VERSION ""

NS_ :

BS_:

BU_: AHLM ASBS CADM CBC DIAGNOST DPDM DTCM ECM EHPS ESC ESL ESM ETM EVCU2 GPF IC IRCM LTM OCM ORC PTS RF_HUB SCCM SGW TBM TCM

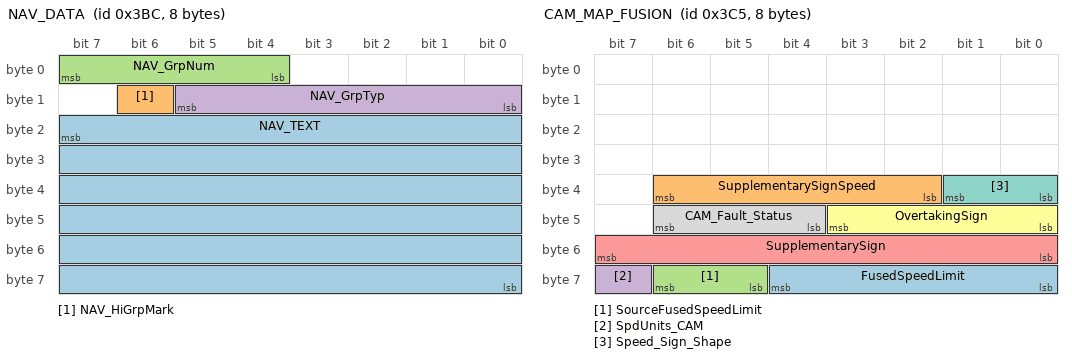
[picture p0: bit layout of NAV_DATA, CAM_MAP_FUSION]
BO_ 956 NAV_DATA: 8 CBC
 SG_ NAV_TEXT : 23|48@0+ (1,0) [0|0] ""  IC,SGW
 SG_ NAV_HiGrpMark : 14|1@1+ (1,0) [0|0] ""  IC,SGW
 SG_ NAV_GrpNum : 4|4@1+ (1,1) [1|16] "Group"  IC,SGW
 SG_ NAV_GrpTyp : 8|6@1+ (1,0) [1|40] "Text"  IC,SGW

BO_ 958 IC_TripData_7: 8 IC
 SG_ Electric_Dist_Miles : 1|10@0+ (1,0) [0|999] "Mile"  CBC,ETM,SGW,TBM
 SG_ Hybrid_Dist_Miles : 17|10@0+ (1,0) [0|999] "Mile"  CBC,ETM,SGW,TBM

BO_ 959 IC_TripData_8: 8 IC
 SG_ Electric_Dist_Kilometers : 1|10@0+ (1,0) [0|999] "km"  CBC,ETM,SGW,TBM
 SG_ Hybrid_Dist_Kilometers : 17|10@0+ (1,0) [0|999] "km"  CBC,ETM,SGW,TBM

BO_ 962 VehCfgCSM3: 8 CBC
 SG_ VC_LIFT_GATE_RELEASE_CSO : 37|1@1+ (1,0) [0|0] ""  RF_HUB,SGW
 SG_ VC_VISM_KEEP_AWAKE_CSO : 38|1@1+ (1,0) [0|0] ""  RF_HUB,SGW
 SG_ VC_FOA_Presence : 39|1@1+ (1,0) [0|0] ""  IC,RF_HUB,SGW,TBM
 SG_ VC_FOA_Type : 12|2@1+ (1,0) [0|0] ""  IC,RF_HUB,SGW,TBM
 SG_ VC_CHMSL_DYN_CNTR_CSO : 7|1@1+ (1,0) [0|0] ""  RF_HUB,SGW
 SG_ VC_VehCfgCSO3_Stat : 0|2@1+ (1,0) [0|0] ""  EVCU2,IC,RF_HUB,SGW
 SG_ VC_FFC_GRIDLINES_CSO : 48|1@1+ (1,0) [0|0] ""  RF_HUB,SGW
 SG_ VC_RVC_CVPM_DGRID_CSO : 49|1@1+ (1,0) [0|0] ""  RF_HUB,SGW
 SG_ VC_RVC_CVPM_SGRID_CSO : 50|1@1+ (1,0) [0|0] ""  RF_HUB,SGW
 SG_ VC_PEB_CSO : 51|1@1+ (1,0) [0|0] ""  RF_HUB,SGW
 SG_ VC_FT_PK_LOOSE_SHIP_CSO : 8|1@1+ (1,0) [0|0] ""  RF_HUB,SGW
 SG_ VC_RR_PK_LOOSE_SHIP_CSO : 9|1@1+ (1,0) [0|0] ""  RF_HUB,SGW
 SG_ VC_ESAVE_CSO : 10|1@1+ (1,0) [0|0] ""  RF_HUB,SGW
 SG_ VC_ESAVE_BATT_LVL_CSO : 11|1@1+ (1,0) [0|0] ""  RF_HUB,SGW
 SG_ VC_AL_OR_PLUS_CSO : 41|1@1+ (1,0) [0|0] ""  RF_HUB,SGW
 SG_ VC_TSR_WARNING_MODE_CSO : 42|1@1+ (1,0) [0|0] ""  RF_HUB,SGW
 SG_ VC_TSR_WARNING_MODE_OFFSET_CSO : 43|1@1+ (1,0) [0|0] ""  RF_HUB,SGW
 SG_ VC_3RD_ROW_LOCK_CSO : 45|1@1+ (1,0) [0|0] ""  RF_HUB,SGW
 SG_ VC_CHARGE_LOW_POPUP_CSO : 46|1@1+ (1,0) [0|0] ""  RF_HUB,SGW
 SG_ VC_FOBIK_SAFE_CSO : 32|1@1+ (1,0) [0|0] ""  RF_HUB,SGW
 SG_ VC_FOB_LEFT_VEHICLE_CHIME_CSO : 33|1@1+ (1,0) [0|0] ""  RF_HUB,SGW
 SG_ VC_THEFT_ALARM_CSO : 34|1@1+ (1,0) [0|0] ""  RF_HUB,SGW
 SG_ VC_PANIC_ALARM_CSO : 35|1@1+ (1,0) [0|0] ""  RF_HUB,SGW
 SG_ VC_SECURE_PARK_CSO : 36|1@1+ (1,0) [0|0] ""  RF_HUB,SGW

BO_ 963 VehCfgCSM3_BU: 8 RF_HUB
 SG_ VC_BU_TSR_WARNING_MODE_CSO : 42|1@1+ (1,0) [0|0] ""  CBC,SGW
 SG_ VC_BU_TSR_WARNING_MODE_OFFSET_CS : 43|1@1+ (1,0) [0|0] ""  CBC,SGW
 SG_ VC_BU_3RD_ROW_LOCK_CSO : 45|1@1+ (1,0) [0|0] ""  CBC,SGW
 SG_ VC_BU_CHARGE_LOW_POPUP_CSO : 46|1@1+ (1,0) [0|0] ""  CBC,SGW
 SG_ VC_BU_FOA_Presence : 39|1@1+ (1,0) [0|0] ""  CBC,SGW
 SG_ VC_BU_FOA_Type : 12|2@1+ (1,0) [0|0] ""  CBC,SGW
 SG_ VC_BU_FOBIK_SAFE_CSO : 32|1@1+ (1,0) [0|0] ""  CBC,SGW
 SG_ VC_BU_FOB_LEFT_VEHICLE_CHIME_CSO : 33|1@1+ (1,0) [0|0] ""  CBC,SGW
 SG_ VC_BU_THEFT_ALARM_CSO : 34|1@1+ (1,0) [0|0] ""  CBC,SGW
 SG_ VC_BU_PANIC_ALARM_CSO : 35|1@1+ (1,0) [0|0] ""  CBC,SGW
 SG_ VC_BU_SECURE_PARK_CSO : 36|1@1+ (1,0) [0|0] ""  CBC,SGW
 SG_ VC_BU_LIFT_GATE_RELEASE_CSO : 37|1@1+ (1,0) [0|0] ""  CBC,SGW
 SG_ VC_BU_VISM_KEEP_AWAKE_CSO : 38|1@1+ (1,0) [0|0] ""  CBC,SGW
 SG_ VC_BU_CHMSL_DYN_CNTR_CSO : 7|1@1+ (1,0) [0|0] ""  CBC,SGW
 SG_ VC_BU_FT_PK_LOOSE_SHIP_CSO : 8|1@1+ (1,0) [0|0] ""  CBC,SGW
 SG_ VC_BU_RR_PK_LOOSE_SHIP_CSO : 9|1@1+ (1,0) [0|0] ""  CBC,SGW
 SG_ VC_BU_ESAVE_CSO : 10|1@1+ (1,0) [0|0] ""  CBC,SGW
 SG_ VC_BU_ESAVE_BATT_LVL_CSO : 11|1@1+ (1,0) [0|0] ""  CBC,SGW
 SG_ VC_BU_VehCfgCSO3_Stat : 0|2@1+ (1,0) [0|0] ""  CBC,SGW
 SG_ VC_BU_FFC_GRIDLINES_CSO : 48|1@1+ (1,0) [0|0] ""  CBC,SGW
 SG_ VC_BU_RVC_CVPM_DGRID_CSO : 49|1@1+ (1,0) [0|0] ""  CBC,SGW
 SG_ VC_BU_RVC_CVPM_SGRID_CSO : 50|1@1+ (1,0) [0|0] ""  CBC,SGW
 SG_ VC_BU_PEB_CSO : 51|1@1+ (1,0) [0|0] ""  CBC,SGW
 SG_ VC_BU_AL_OR_PLUS_CSO : 41|1@1+ (1,0) [0|0] ""  CBC,SGW

BO_ 965 CAM_MAP_FUSION: 8 CADM
 SG_ FusedSpeedLimit : 56|5@1+ (1,0) [0|0] ""  CBC,IC,SGW
 SG_ SupplementarySignSpeed : 34|5@1+ (1,0) [0|0] ""  CBC,IC,SGW
 SG_ SourceFusedSpeedLimit : 61|2@1+ (1,0) [0|0] ""  CBC,SGW
 SG_ SpdUnits_CAM : 63|1@1+ (1,0) [0|0] ""  CBC,IC,SGW
 SG_ SupplementarySign : 48|8@1+ (1,0) [0|0] ""  CBC,IC,SGW
 SG_ OvertakingSign : 40|4@1+ (1,0) [0|0] ""  CBC,IC,SGW
 SG_ Speed_Sign_Shape : 32|2@1+ (1,0) [0|0] ""  CBC,IC,SGW
 SG_ CAM_Fault_Status : 44|3@1+ (1,0) [0|0] ""  CBC,IC,SGW

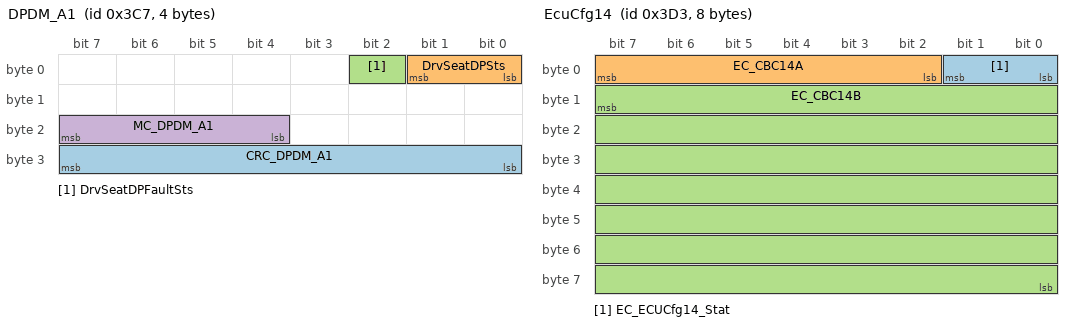
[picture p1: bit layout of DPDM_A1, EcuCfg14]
BO_ 967 DPDM_A1: 4 DPDM
 SG_ CRC_DPDM_A1 : 24|8@1+ (1,0) [0|0] ""  ECM,SGW
 SG_ DrvSeatDPSts : 0|2@1+ (1,0) [0|0] ""  CADM,ECM,ESC,IRCM,ORC,RF_HUB,SGW
 SG_ DrvSeatDPFaultSts : 2|1@1+ (1,0) [0|0] ""  ECM,ORC,SGW
 SG_ MC_DPDM_A1 : 20|4@1+ (1,0) [0|15] ""  ECM,SGW

BO_ 969 AMB_TEMP_DISP: 4 CBC
 SG_ AMB_TEMP_AVG_F : 0|8@1+ (1,-40) [-40|210] "∞F"  IC,SGW
 SG_ AMB_TEMP_AVG_C : 8|8@1+ (1,-40) [-40|210] "∞C"  IC,SGW

BO_ 973 IPC_LMPS: 8 IC
 SG_ EPB_WARN_STAT : 46|2@1+ (1,0) [0|0] ""  CBC,SGW
 SG_ CATALYST_TEMP_STAT : 48|2@1+ (1,0) [0|0] ""  CBC,SGW
 SG_ FUEL_CAP_STAT : 50|2@1+ (1,0) [0|0] ""  CBC,SGW
 SG_ WINDSHIELD_FLUID_STAT : 52|2@1+ (1,0) [0|0] ""  CBC,SGW
 SG_ COOLENT_LEVEL_STAT : 54|2@1+ (1,0) [0|0] ""  CBC,SGW
 SG_ OIL_LEVEL_STAT : 56|2@1+ (1,0) [0|0] ""  CBC,SGW
 SG_ ELECTRIC_WRENCH_STAT : 58|2@1+ (1,0) [0|0] ""  CBC,SGW
 SG_ ENGINE_TEMP_STAT : 0|2@1+ (1,0) [0|0] ""  CBC,SGW
 SG_ BATTERY_CHARGE_STAT : 2|2@1+ (1,0) [0|0] ""  CBC,SGW
 SG_ OIL_PRESSURE_STAT : 4|2@1+ (1,0) [0|0] ""  CBC,SGW
 SG_ BRK_IND_STAT : 6|2@1+ (1,0) [0|0] ""  CBC,SGW
 SG_ ABS_IND_STAT : 8|2@1+ (1,0) [0|0] ""  CBC,SGW
 SG_ ENGINE_MIL_STAT : 10|2@1+ (1,0) [0|0] ""  CBC,SGW
 SG_ TIRE_PRESSURE_STAT : 12|2@1+ (1,0) [0|0] ""  CBC,SGW
 SG_ ETC_CONTROL_STAT : 14|2@1+ (1,0) [0|0] ""  CBC,SGW
 SG_ ELEC_STAB_STAT : 16|2@1+ (1,0) [0|0] ""  CBC,SGW
 SG_ OVER_TEMP_STAT : 18|2@1+ (1,0) [0|0] ""  CBC,SGW
 SG_ STOP_START_STAT : 20|2@1+ (1,0) [0|0] ""  CBC,SGW
 SG_ EPS_STAT : 22|2@1+ (1,0) [0|0] ""  CBC,SGW
 SG_ FCW_SYSTEM_STAT : 24|2@1+ (1,0) [0|0] ""  CBC,SGW
 SG_ SERVICE_ACC_STAT : 26|2@1+ (1,0) [0|0] ""  CBC,SGW
 SG_ WATER_IN_FUEL_STAT : 28|2@1+ (1,0) [0|0] ""  CBC,SGW
 SG_ TORQUE_STAT : 60|2@1+ (1,0) [0|0] ""  CBC,SGW
 SG_ DEF_STAT : 30|2@1+ (1,0) [0|0] ""  CBC,SGW
 SG_ OIL_TEMP_STAT : 32|2@1+ (1,0) [0|0] ""  CBC,SGW
 SG_ SERVICE_STAT : 34|2@1+ (1,0) [0|0] ""  CBC,SGW
 SG_ DAMPING_SYSTEM_STAT : 36|2@1+ (1,0) [0|0] ""  CBC,SGW
 SG_ BRAKE_PAD_STAT : 38|2@1+ (1,0) [0|0] ""  CBC,SGW
 SG_ FOUR_WD_SERVICE_STAT : 40|2@1+ (1,0) [0|0] ""  CBC,SGW
 SG_ LANE_SENSE_STAT : 42|2@1+ (1,0) [0|0] ""  CBC,SGW
 SG_ AWD_SERVICE_STAT : 44|2@1+ (1,0) [0|0] ""  CBC,SGW
 SG_ FOA_AppAlert_Disable_UserReq : 62|1@1+ (1,0) [0|0] ""  CBC,SGW

BO_ 976 ECM_A4: 8 ECM
 SG_ PF_WARN_MSG : 24|3@1+ (1,0) [0|0] ""  IC,SGW
 SG_ KNK_MG_TRIGGER : 29|2@1+ (1,0) [0|0] ""  IC,SGW

BO_ 979 EcuCfg14: 8 CBC
 SG_ EC_ECUCfg14_Stat : 0|2@1+ (1,0) [0|0] ""  RF_HUB,SGW
 SG_ EC_CBC14A : 2|6@1+ (1,0) [0|0] ""  RF_HUB,SGW
 SG_ EC_CBC14B : 15|56@0+ (1,0) [0|0] ""  RF_HUB,SGW

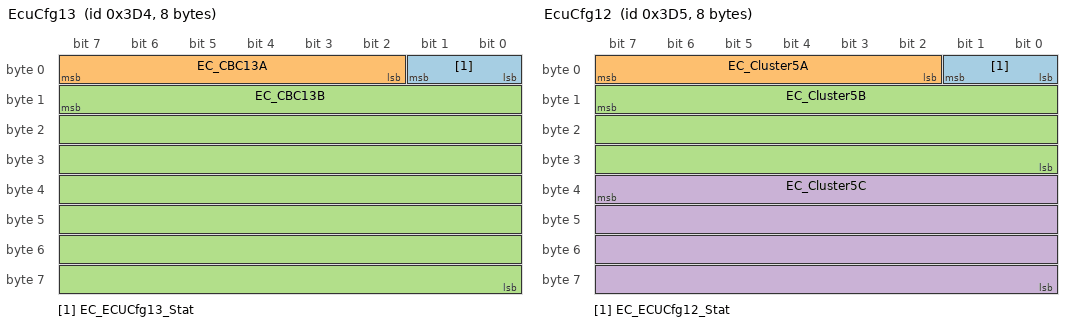
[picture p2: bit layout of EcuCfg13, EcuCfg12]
BO_ 980 EcuCfg13: 8 CBC
 SG_ EC_ECUCfg13_Stat : 0|2@1+ (1,0) [0|0] ""  RF_HUB,SGW
 SG_ EC_CBC13A : 2|6@1+ (1,0) [0|0] ""  RF_HUB,SGW
 SG_ EC_CBC13B : 15|56@0+ (1,0) [0|0] ""  RF_HUB,SGW

BO_ 981 EcuCfg12: 8 CBC
 SG_ EC_ECUCfg12_Stat : 0|2@1+ (1,0) [0|0] ""  IC,RF_HUB,SGW
 SG_ EC_Cluster5A : 2|6@1+ (1,0) [0|0] ""  RF_HUB,SGW
 SG_ EC_Cluster5B : 15|24@0+ (1,0) [0|0] ""  RF_HUB,SGW
 SG_ EC_Cluster5C : 39|32@0+ (1,0) [0|0] ""  RF_HUB,SGW

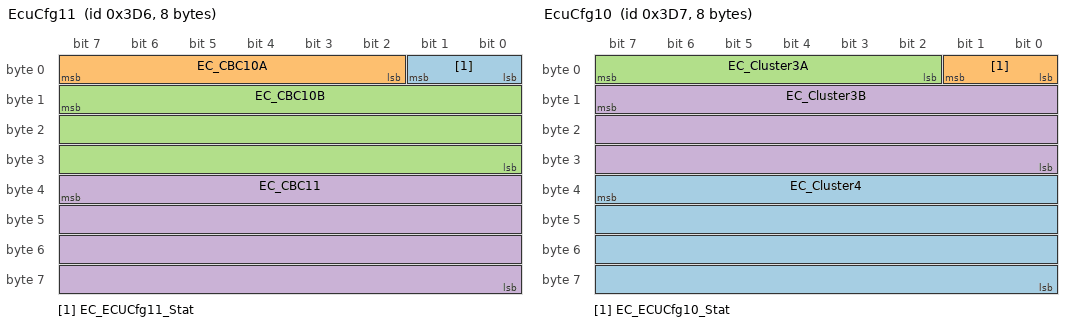
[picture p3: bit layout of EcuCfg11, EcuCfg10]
BO_ 982 EcuCfg11: 8 CBC
 SG_ EC_ECUCfg11_Stat : 0|2@1+ (1,0) [0|0] ""  RF_HUB,SGW
 SG_ EC_CBC10A : 2|6@1+ (1,0) [0|0] ""  RF_HUB,SGW
 SG_ EC_CBC10B : 15|24@0+ (1,0) [0|0] ""  RF_HUB,SGW
 SG_ EC_CBC11 : 39|32@0+ (1,0) [0|0] ""  RF_HUB,SGW

BO_ 983 EcuCfg10: 8 CBC
 SG_ EC_Cluster4 : 39|32@0+ (1,0) [0|0] ""  RF_HUB,SGW
 SG_ EC_ECUCfg10_Stat : 0|2@1+ (1,0) [0|0] ""  IC,RF_HUB,SGW
 SG_ EC_Cluster3A : 2|6@1+ (1,0) [0|0] ""  RF_HUB,SGW
 SG_ EC_Cluster3B : 15|24@0+ (1,0) [0|0] ""  RF_HUB,SGW

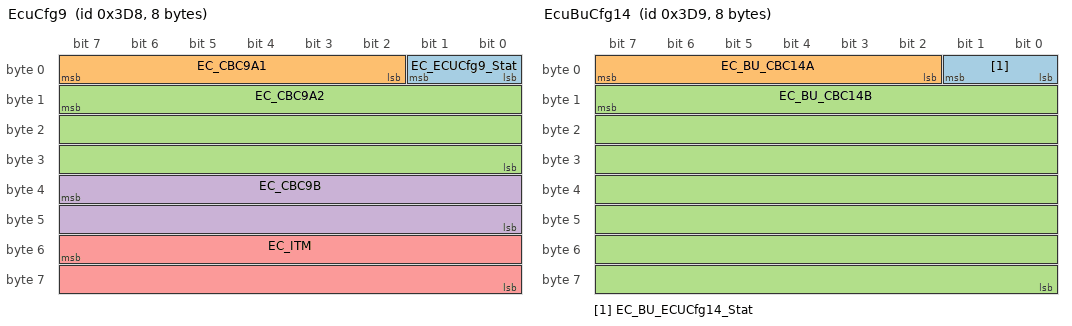
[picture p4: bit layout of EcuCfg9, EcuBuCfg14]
BO_ 984 EcuCfg9: 8 CBC
 SG_ EC_ECUCfg9_Stat : 0|2@1+ (1,0) [0|0] ""  RF_HUB,SGW
 SG_ EC_CBC9A1 : 2|6@1+ (1,0) [0|0] ""  RF_HUB,SGW
 SG_ EC_CBC9A2 : 15|24@0+ (1,0) [0|0] ""  RF_HUB,SGW
 SG_ EC_CBC9B : 39|16@0+ (1,0) [0|0] ""  RF_HUB,SGW
 SG_ EC_ITM : 55|16@0+ (1,0) [0|0] ""  RF_HUB,SGW

BO_ 985 EcuBuCfg14: 8 RF_HUB
 SG_ EC_BU_ECUCfg14_Stat : 0|2@1+ (1,0) [0|0] ""  CBC,SGW
 SG_ EC_BU_CBC14A : 2|6@1+ (1,0) [0|0] ""  CBC,SGW
 SG_ EC_BU_CBC14B : 15|56@0+ (1,0) [0|0] ""  CBC,SGW

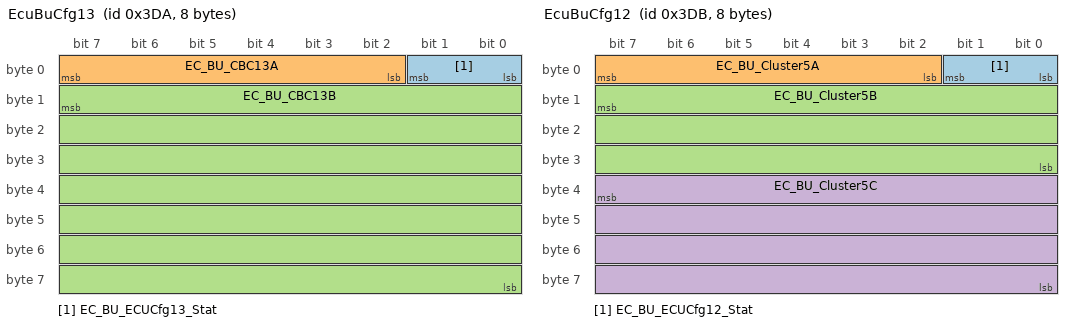
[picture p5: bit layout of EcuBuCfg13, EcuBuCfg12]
BO_ 986 EcuBuCfg13: 8 RF_HUB
 SG_ EC_BU_ECUCfg13_Stat : 0|2@1+ (1,0) [0|0] ""  CBC,SGW
 SG_ EC_BU_CBC13A : 2|6@1+ (1,0) [0|0] ""  CBC,SGW
 SG_ EC_BU_CBC13B : 15|56@0+ (1,0) [0|0] ""  CBC,SGW

BO_ 987 EcuBuCfg12: 8 RF_HUB
 SG_ EC_BU_ECUCfg12_Stat : 0|2@1+ (1,0) [0|0] ""  CBC,SGW
 SG_ EC_BU_Cluster5A : 2|6@1+ (1,0) [0|0] ""  CBC,SGW
 SG_ EC_BU_Cluster5B : 15|24@0+ (1,0) [0|0] ""  CBC,SGW
 SG_ EC_BU_Cluster5C : 39|32@0+ (1,0) [0|0] ""  CBC,SGW

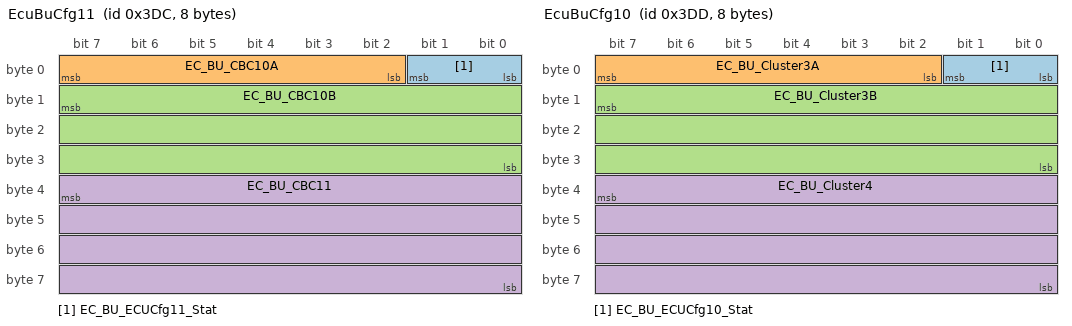
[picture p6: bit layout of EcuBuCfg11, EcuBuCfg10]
BO_ 988 EcuBuCfg11: 8 RF_HUB
 SG_ EC_BU_ECUCfg11_Stat : 0|2@1+ (1,0) [0|0] ""  CBC,SGW
 SG_ EC_BU_CBC10A : 2|6@1+ (1,0) [0|0] ""  CBC,SGW
 SG_ EC_BU_CBC10B : 15|24@0+ (1,0) [0|0] ""  CBC,SGW
 SG_ EC_BU_CBC11 : 39|32@0+ (1,0) [0|0] ""  CBC,SGW

BO_ 989 EcuBuCfg10: 8 RF_HUB
 SG_ EC_BU_ECUCfg10_Stat : 0|2@1+ (1,0) [0|0] ""  CBC,SGW
 SG_ EC_BU_Cluster3A : 2|6@1+ (1,0) [0|0] ""  CBC,SGW
 SG_ EC_BU_Cluster3B : 15|24@0+ (1,0) [0|0] ""  CBC,SGW
 SG_ EC_BU_Cluster4 : 39|32@0+ (1,0) [0|0] ""  CBC,SGW

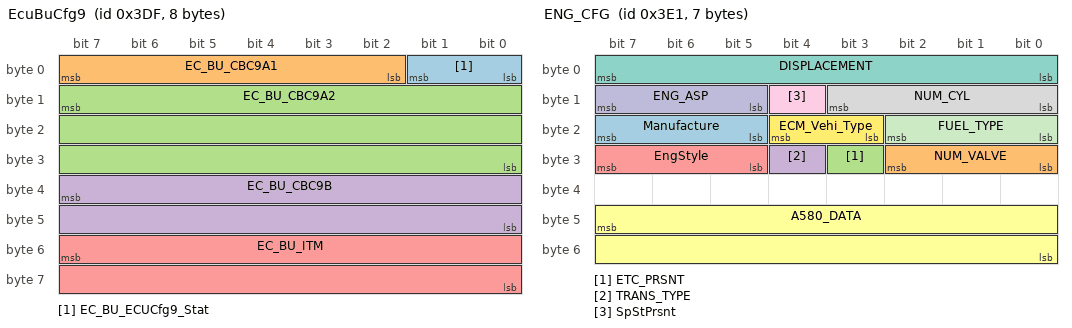
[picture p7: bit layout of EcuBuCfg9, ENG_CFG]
BO_ 991 EcuBuCfg9: 8 RF_HUB
 SG_ EC_BU_ECUCfg9_Stat : 0|2@1+ (1,0) [0|0] ""  CBC,SGW
 SG_ EC_BU_CBC9A1 : 2|6@1+ (1,0) [0|0] ""  CBC,SGW
 SG_ EC_BU_CBC9A2 : 15|24@0+ (1,0) [0|0] ""  CBC,SGW
 SG_ EC_BU_CBC9B : 39|16@0+ (1,0) [0|0] ""  CBC,SGW
 SG_ EC_BU_ITM : 55|16@0+ (1,0) [0|0] ""  CBC,SGW

BO_ 992 VIN: 8 ECM
 SG_ VIN_DATA : 15|56@0+ (1,0) [0|0] ""  AHLM,ASBS,CADM,CBC,DPDM,DTCM,EHPS,ESC,ESL,ESM,ETM,EVCU2,IC,IRCM,OCM,ORC,PTS,RF_HUB,SCCM,SGW,TBM,TCM
 SG_ VIN_MSG : 0|2@1+ (1,0) [0|0] ""  AHLM,ASBS,CADM,CBC,DPDM,DTCM,EHPS,ESC,ESL,ESM,ETM,EVCU2,IC,IRCM,OCM,ORC,PTS,RF_HUB,SCCM,SGW,TBM,TCM

BO_ 993 ENG_CFG: 7 ECM
 SG_ Manufacture : 21|3@1+ (1,0) [0|0] ""  SGW
 SG_ NUM_VALVE : 24|3@1+ (1,0) [0|6] "valve-per-cylinder"  CADM,IRCM,SGW
 SG_ ETC_PRSNT : 27|1@1+ (1,0) [0|0] ""  SGW
 SG_ TRANS_TYPE : 28|1@1+ (1,0) [0|0] ""  ETM,SGW,TBM
 SG_ EngStyle : 29|3@1+ (1,0) [0|0] ""  CBC,ESC,SGW
 SG_ A580_DATA : 47|16@0+ (1,0) [0|0] ""  SGW
 SG_ DISPLACEMENT : 0|8@1+ (0.1,0) [0|25] "liters"  CADM,DTCM,ESC,ETM,IC,IRCM,ORC,SGW,TBM
 SG_ NUM_CYL : 8|4@1+ (1,0) [0|14] "cylinders"  CADM,ESC,ETM,IC,IRCM,SGW,TBM
 SG_ SpStPrsnt : 12|1@1+ (1,0) [0|0] ""  CADM,CBC,EHPS,ESC,IC,IRCM,PTS,SGW
 SG_ ENG_ASP : 13|3@1+ (1,0) [0|0] ""  CADM,ESC,IC,IRCM,SGW
 SG_ FUEL_TYPE : 16|3@1+ (1,0) [0|0] ""  CADM,CBC,ESC,ETM,IC,IRCM,SGW,TBM
 SG_ ECM_Vehi_Type : 19|2@1+ (1,0) [0|0] ""  SGW

BO_ 995 NET_CFG_INT: 8 CBC
 SG_ NetCfg_UPFM : 46|1@1+ (1,0) [0|0] ""  RF_HUB,SGW
 SG_ NetCfg_TTM : 47|1@1+ (1,0) [0|0] ""  RF_HUB,SGW
 SG_ NetCfg_PSSM : 45|1@1+ (1,0) [0|0] ""  IC,RF_HUB,SGW
 SG_ NetCfg_TBM : 38|1@1+ (1,0) [0|0] ""  IC,RF_HUB,SGW
 SG_ NetCfg_ICS_R : 34|1@1+ (1,0) [0|0] ""  RF_HUB,SGW
 SG_ NetCfg_MSM_PASS : 35|1@1+ (1,0) [0|0] ""  RF_HUB,SGW
 SG_ NetCfg_VRM : 36|1@1+ (1,0) [0|0] ""  RF_HUB,SGW
 SG_ NetCfg_VES2_I : 28|1@1+ (1,0) [0|0] ""  RF_HUB,SGW
 SG_ NetCfg_VES3_I : 29|1@1+ (1,0) [0|0] ""  RF_HUB,SGW
 SG_ NetCfg_CRSM : 30|1@1+ (1,0) [0|0] ""  RF_HUB,SGW
 SG_ NetCfg_HVAC_R : 31|1@1+ (1,0) [0|0] ""  RF_HUB,SGW
 SG_ NetCfg_CVPM : 32|1@1+ (1,0) [0|0] ""  RF_HUB,SGW
 SG_ NetCfg_AMP_I : 24|1@1+ (1,0) [0|0] ""  RF_HUB,SGW
 SG_ NetCfg_DVD_CDM : 25|1@1+ (1,0) [0|0] ""  RF_HUB,SGW
 SG_ NetCfg_HFM_CTM : 26|1@1+ (1,0) [0|0] ""  RF_HUB,SGW
 SG_ NetCfg_RBC : 18|1@1+ (1,0) [0|0] ""  RF_HUB,SGW
 SG_ NetCfg_DTV : 19|1@1+ (1,0) [0|0] ""  RF_HUB,SGW
 SG_ NetCfg_TGW : 20|1@1+ (1,0) [0|0] ""  RF_HUB,SGW
 SG_ NetCfg_CLOCK : 21|1@1+ (1,0) [0|0] ""  ETM,RF_HUB,SGW,TBM
 SG_ NetCfg_VSIM : 22|1@1+ (1,0) [0|0] ""  RF_HUB,SGW
 SG_ NetCfg_TGWM : 42|1@1+ (1,0) [0|0] ""  RF_HUB,SGW
 SG_ NetCfg_RBSS : 2|1@1+ (1,0) [0|0] ""  RF_HUB,SGW
 SG_ NetCfg_BSM : 3|1@1+ (1,0) [0|0] ""  CADM,IC,IRCM,RF_HUB,SGW
 SG_ NetCfg_CBC_IN : 4|1@1+ (1,0) [0|0] ""  RF_HUB,SGW
 SG_ NetCfg_CSWM : 5|1@1+ (1,0) [0|0] ""  RF_HUB,SGW
 SG_ NetCfg_DCM_DR : 6|1@1+ (1,0) [0|0] ""  RF_HUB,SGW
 SG_ NetCfg_DCM_PASS : 7|1@1+ (1,0) [0|0] ""  RF_HUB,SGW
 SG_ NetCfg_DCM_RL : 8|1@1+ (1,0) [0|0] ""  RF_HUB,SGW
 SG_ NetCfg_FSM : 16|1@1+ (1,0) [0|0] ""  RF_HUB,SGW
 SG_ NET_CFG_STAT_INT : 0|2@1+ (1,0) [0|0] ""  CADM,IC,IRCM,RF_HUB,SGW
 SG_ NetCfg_HVAC : 10|1@1+ (1,0) [0|0] ""  RF_HUB,SGW
 SG_ NetCfg_MSM : 11|1@1+ (1,0) [0|0] ""  RF_HUB,SGW
 SG_ NetCfg_PLG : 12|1@1+ (1,0) [0|0] ""  RF_HUB,SGW
 SG_ NetCfg_VTM : 13|1@1+ (1,0) [0|0] ""  RF_HUB,SGW
 SG_ NetCfg_PSD_LT : 14|1@1+ (1,0) [0|0] ""  RF_HUB,SGW
 SG_ NetCfg_DCM_RR : 9|1@1+ (1,0) [0|0] ""  RF_HUB,SGW
 SG_ NetCfg_PSD_RT : 15|1@1+ (1,0) [0|0] ""  RF_HUB,SGW
 SG_ NetCfg_PTCM : 17|1@1+ (1,0) [0|0] ""  IC,RF_HUB,SGW
 SG_ NetCfg_ITM : 23|1@1+ (1,0) [0|0] ""  RF_HUB,SGW
 SG_ NetCfg_ICS_I : 27|1@1+ (1,0) [0|0] ""  CADM,RF_HUB,SGW
 SG_ NetCfg_TMM : 33|1@1+ (1,0) [0|0] ""  RF_HUB,SGW
 SG_ NetCfg_DCSD : 37|1@1+ (1,0) [0|0] ""  RF_HUB,SGW
 SG_ NetCfg_ANC_I : 39|1@1+ (1,0) [0|0] ""  RF_HUB,SGW

CM_ SG_ 956 NAV_TEXT "NAV data field";
CM_ SG_ 956 NAV_HiGrpMark "NAV high group mark";
CM_ SG_ 956 NAV_GrpNum "NAV group number";
CM_ SG_ 956 NAV_GrpTyp "NAV group type";
CM_ SG_ 958 Electric_Dist_Miles "Electric distance traveled during IgnCycle in US miles";
CM_ SG_ 958 Hybrid_Dist_Miles "Hybrid distance traveled during IgnCycle in US miles";
CM_ SG_ 959 Electric_Dist_Kilometers "Electric distance traveled during IgnCycle in kilometers";
CM_ SG_ 959 Hybrid_Dist_Kilometers "Hybrid distance traveled during IgnCycle in kilometers";
CM_ SG_ 962 VC_LIFT_GATE_RELEASE_CSO "Liftgate release settings  ; 0 - Absent , 1 - Present";
CM_ SG_ 962 VC_VISM_KEEP_AWAKE_CSO "VSIM Keep Awake settings ; 0 - Absent , 1 - Present";
CM_ SG_ 962 VC_FOA_Presence "Forgotten Occupant/Object Alert;0 =Absent 1 = Present";
CM_ SG_ 962 VC_FOA_Type "Forgotten Occupant/Object Alert Type";
CM_ SG_ 962 VC_CHMSL_DYN_CNTR_CSO "CHMSL Dynamic Centerline Enable/Disable customer settings menu";
CM_ SG_ 962 VC_VehCfgCSO3_Stat "Configuration message CSO3 status";
CM_ SG_ 962 VC_FFC_GRIDLINES_CSO "Forward Facing Camera Gridlines, Present = 1";
CM_ SG_ 962 VC_RVC_CVPM_DGRID_CSO "Rear CVPM Camera Dynamic Gridlines, Present = 1";
CM_ SG_ 962 VC_RVC_CVPM_SGRID_CSO "Rear CVPM Camera Static Gridlines, Present = 1";
CM_ SG_ 962 VC_PEB_CSO "Pedestrian Emergency Brake Enable/Disable customer settings menu";
CM_ SG_ 962 VC_FT_PK_LOOSE_SHIP_CSO "Front Park Sense Loose Ship Enable/Disable customer settings menu;0 - Absent 1 - Present";
CM_ SG_ 962 VC_RR_PK_LOOSE_SHIP_CSO "Rear Park Sense Loose Ship Enable/Disable customer settings menu;0 - Absent 1 - Present";
CM_ SG_ 962 VC_ESAVE_CSO "E-Save Enable/Disable customer settings menu";
CM_ SG_ 962 VC_ESAVE_BATT_LVL_CSO "E-Save Battery Level customer settings menu";
CM_ SG_ 962 VC_AL_OR_PLUS_CSO "Auto Launch Off Road Plus customer settings menu";
CM_ SG_ 962 VC_TSR_WARNING_MODE_CSO "TSR Warning Mode customer setting menu, Present = 1";
CM_ SG_ 962 VC_TSR_WARNING_MODE_OFFSET_CSO "TSR Warning Mode Offset customer setting menu, Present = 1";
CM_ SG_ 962 VC_3RD_ROW_LOCK_CSO "3rd Row Lockout Enable/Disable customer settings menu, Present = [1]";
CM_ SG_ 962 VC_CHARGE_LOW_POPUP_CSO "Charge Low PopUp Enable/Disable customer settings menu, Present = [1]";
CM_ SG_ 962 VC_FOBIK_SAFE_CSO "FOBIK SAFE Enable/Disable customer settings menu;0 - Absent , 1 - Present";
CM_ SG_ 962 VC_FOB_LEFT_VEHICLE_CHIME_CSO "FOB Left Vehicle chime settings;0 - Absent , 1 - Present";
CM_ SG_ 962 VC_THEFT_ALARM_CSO "Theft Alarm settings;0 - Absent , 1 - Present";
CM_ SG_ 962 VC_PANIC_ALARM_CSO "Panic Alarm settings ; 0 - Absent , 1 - Present";
CM_ SG_ 962 VC_SECURE_PARK_CSO "Secure Park settings ; 0 - Absent , 1 - Present";
CM_ SG_ 963 VC_BU_TSR_WARNING_MODE_CSO "Backup TSR Warning Mode customer setting menu, Present = 1";
CM_ SG_ 963 VC_BU_TSR_WARNING_MODE_OFFSET_CS "Backup TSR Warning Mode Offset customer setting menu, Present = 1";
CM_ SG_ 963 VC_BU_3RD_ROW_LOCK_CSO "Backup 3rd Row Lockout Enable/Disable customer settings menu, Present = [1]";
CM_ SG_ 963 VC_BU_CHARGE_LOW_POPUP_CSO "Backup Charge Low PopUp Enable/Disable customer settings menu, Present = [1]";
CM_ SG_ 963 VC_BU_FOA_Presence "Back up for VC_FOA_Presence";
CM_ SG_ 963 VC_BU_FOA_Type "Backup for VC_FOA_Type";
CM_ SG_ 963 VC_BU_FOBIK_SAFE_CSO "Back up for FOBIK SAFE Enable/Disable customer settings menu;0 - Absent , 1 - Present";
CM_ SG_ 963 VC_BU_FOB_LEFT_VEHICLE_CHIME_CSO "Back up for FOB Left Vehicle chime settings ;0 - Absent , 1 - Present";
CM_ SG_ 963 VC_BU_THEFT_ALARM_CSO "Back up for Theft Alarm settings ;0 - Absent , 1 - Present";
CM_ SG_ 963 VC_BU_PANIC_ALARM_CSO "Back up for Panic Alarm settings ; 0 - Absent , 1 - Present";
CM_ SG_ 963 VC_BU_SECURE_PARK_CSO "Back up for Secure Park settings ; 0 - Absent , 1 - Present";
CM_ SG_ 963 VC_BU_LIFT_GATE_RELEASE_CSO "Back up for Liftgate release settings  ; 0 - Absent , 1 - Present";
CM_ SG_ 963 VC_BU_VISM_KEEP_AWAKE_CSO "Back up for VSIM Keep Awake settings ; 0 - Absent , 1 - Present";
CM_ SG_ 963 VC_BU_CHMSL_DYN_CNTR_CSO "BACKUP CHMSL Dynamic Centerline Enable/Disable customer settings menu";
CM_ SG_ 963 VC_BU_FT_PK_LOOSE_SHIP_CSO "Back up for Front Park Sense Loose Ship Enable/Disable customer settings menu;0 - Absent 1 - Present";
CM_ SG_ 963 VC_BU_RR_PK_LOOSE_SHIP_CSO "Back up for Rear Park Sense Loose Ship Enable/Disable customer settings menu;0 - Absent 1 - Present";
CM_ SG_ 963 VC_BU_ESAVE_CSO "Backup E-Save Enable/Disable customer settings menu";
CM_ SG_ 963 VC_BU_ESAVE_BATT_LVL_CSO "Backup E-Save Battery Level customer settings menu";
CM_ SG_ 963 VC_BU_VehCfgCSO3_Stat "Backup for Configuration message CSO3 status";
CM_ SG_ 963 VC_BU_FFC_GRIDLINES_CSO "Backup for Forward Facing Camera Gridlines, Present = 1";
CM_ SG_ 963 VC_BU_RVC_CVPM_DGRID_CSO "Backup for Rear CVPM Camera Dynamic Gridlines, Present = 1";
CM_ SG_ 963 VC_BU_RVC_CVPM_SGRID_CSO "Backup for Rear CVPM Camera Static Gridlines, Present = 1";
CM_ SG_ 963 VC_BU_PEB_CSO "Pedestrian Emergency Brake Enable/Disable customer settings menu";
CM_ SG_ 963 VC_BU_AL_OR_PLUS_CSO "BACKUP Auto Launch Off Road Plus customer settings menu";
CM_ SG_ 965 FusedSpeedLimit "Fused Speed Limit from Camera + Map Data";
CM_ SG_ 965 SupplementarySignSpeed "Supplementary Sign Speed detected by camera";
CM_ SG_ 965 SourceFusedSpeedLimit "Source of the fused speed limit data";
CM_ SG_ 965 SpdUnits_CAM "Speed Units";
CM_ SG_ 965 SupplementarySign "Supplementary Sign detected by camera";
CM_ SG_ 965 OvertakingSign "Overtaking Sign detected by camera";
CM_ SG_ 965 Speed_Sign_Shape "Shape of Speed Sign";
CM_ SG_ 965 CAM_Fault_Status "Camera Status";
CM_ SG_ 967 CRC_DPDM_A1 "CRC-checksum byte 1 to 5 according to SAE J1850";
CM_ SG_ 967 DrvSeatDPSts "Driver Presence Status";
CM_ SG_ 967 DrvSeatDPFaultSts "Driver Detection Fault Status";
CM_ SG_ 967 MC_DPDM_A1 "Message counter";
CM_ SG_ 969 AMB_TEMP_AVG_F "Ambient temperature average - in degrees Fahrenheit";
CM_ SG_ 969 AMB_TEMP_AVG_C "Ambient temperature average - in degrees Celsius";
CM_ SG_ 973 EPB_WARN_STAT "EPB warn indicator status";
CM_ SG_ 973 CATALYST_TEMP_STAT "Catalyst Overtemp";
CM_ SG_ 973 FUEL_CAP_STAT "Fuel Cap Unfastened";
CM_ SG_ 973 WINDSHIELD_FLUID_STAT "Windshield Water Fluid";
CM_ SG_ 973 COOLENT_LEVEL_STAT "Low Coolent Level";
CM_ SG_ 973 OIL_LEVEL_STAT "Oil Level";
CM_ SG_ 973 ELECTRIC_WRENCH_STAT "Electric Wrench";
CM_ SG_ 973 ENGINE_TEMP_STAT "Engine temperature indicator status";
CM_ SG_ 973 BATTERY_CHARGE_STAT "Battery charge indicator status";
CM_ SG_ 973 OIL_PRESSURE_STAT "Oil pressure indicator status";
CM_ SG_ 973 BRK_IND_STAT "Brake indicator status";
CM_ SG_ 973 ABS_IND_STAT "ABS indicator status";
CM_ SG_ 973 ENGINE_MIL_STAT "Engine MIL indicator status";
CM_ SG_ 973 TIRE_PRESSURE_STAT "Tire pressure indicator status";
CM_ SG_ 973 ETC_CONTROL_STAT "ETC control indicator status";
CM_ SG_ 973 ELEC_STAB_STAT "Electronic stability indicator status";
CM_ SG_ 973 OVER_TEMP_STAT "Over temperature indicator status";
CM_ SG_ 973 STOP_START_STAT "Stop start indicator status";
CM_ SG_ 973 EPS_STAT "EPS indicator status";
CM_ SG_ 973 FCW_SYSTEM_STAT "FCW system indicator status";
CM_ SG_ 973 SERVICE_ACC_STAT "Service ACC indicator status";
CM_ SG_ 973 WATER_IN_FUEL_STAT "Water in fuel indicator status";
CM_ SG_ 973 TORQUE_STAT "Torque Limited";
CM_ SG_ 973 DEF_STAT "DEF indicator status";
CM_ SG_ 973 OIL_TEMP_STAT "Oil temperature indicator status";
CM_ SG_ 973 SERVICE_STAT "Service indicator status";
CM_ SG_ 973 DAMPING_SYSTEM_STAT "Damping system indicator status";
CM_ SG_ 973 BRAKE_PAD_STAT "Brake pad indicator status";
CM_ SG_ 973 FOUR_WD_SERVICE_STAT "Service indicator status";
CM_ SG_ 973 LANE_SENSE_STAT "Lane sense indicator status";
CM_ SG_ 973 AWD_SERVICE_STAT "AWD service indicator status";
CM_ SG_ 973 FOA_AppAlert_Disable_UserReq "Forgotten Object Alert IPC disable request;0 = Not_Active 1 = Active";
CM_ SG_ 976 PF_WARN_MSG "Particulate Filter warning message status";
CM_ SG_ 976 KNK_MG_TRIGGER "engine is experiencing high levels of LSPI (mega-knock)";
CM_ SG_ 979 EC_ECUCfg14_Stat "ECU Configuration messages status 14";
CM_ SG_ 979 EC_CBC14A "CBC ecu configuration 14A";
CM_ SG_ 979 EC_CBC14B "CBC ecu configuration 14B";
CM_ SG_ 980 EC_ECUCfg13_Stat "ECU Configuration messages status 13";
CM_ SG_ 980 EC_CBC13A "CBC ecu configuration 13A";
CM_ SG_ 980 EC_CBC13B "CBC ecu configuration 13B";
CM_ SG_ 981 EC_ECUCfg12_Stat "ECU Configuration messages status 12";
CM_ SG_ 981 EC_Cluster5A "Instrument cluster ecu configuration 5A";
CM_ SG_ 981 EC_Cluster5B "Instrument cluster ecu configuration 5B";
CM_ SG_ 981 EC_Cluster5C "Instrument cluster ecu configuration 5C";
CM_ SG_ 982 EC_ECUCfg11_Stat "ECU Configuration messages status 11";
CM_ SG_ 982 EC_CBC10A "CBC ecu configuration 10A";
CM_ SG_ 982 EC_CBC10B "CBC ecu configuration 10B";
CM_ SG_ 982 EC_CBC11 "CBC ecu configuration 11";
CM_ SG_ 983 EC_Cluster4 "Instrument cluster ecu configuration 4";
CM_ SG_ 983 EC_ECUCfg10_Stat "ECU Configuration messages status 10";
CM_ SG_ 983 EC_Cluster3A "Instrument cluster ecu configuration 3A";
CM_ SG_ 983 EC_Cluster3B "Instrument cluster ecu configuration 3B";
CM_ SG_ 984 EC_ECUCfg9_Stat "ECU Configuration messages status 9";
CM_ SG_ 984 EC_CBC9A1 "CBC configuration 9A1";
CM_ SG_ 984 EC_CBC9A2 "CBC configuration 9A2";
CM_ SG_ 984 EC_CBC9B "CBC configuration 9B";
CM_ SG_ 984 EC_ITM "ITM ecu configuration";
CM_ SG_ 985 EC_BU_ECUCfg14_Stat "Backup for ECU Configuration messages status 14";
CM_ SG_ 985 EC_BU_CBC14A "Backup for CBC ecu configuration 14A";
CM_ SG_ 985 EC_BU_CBC14B "Backup for CBC ecu configuration 14B";
CM_ SG_ 986 EC_BU_ECUCfg13_Stat "Backup for ECU Configuration messages status 13";
CM_ SG_ 986 EC_BU_CBC13A "Backup for CBC ecu configuration 13A";
CM_ SG_ 986 EC_BU_CBC13B "Backup for CBC ecu configuration 13B";
CM_ SG_ 987 EC_BU_ECUCfg12_Stat "Backup for ECU Configuration messages status 12";
CM_ SG_ 987 EC_BU_Cluster5A "Backup for Instrument cluster ecu configuration 5A";
CM_ SG_ 987 EC_BU_Cluster5B "Backup for Instrument cluster ecu configuration 5B";
CM_ SG_ 987 EC_BU_Cluster5C "Backup for Instrument cluster ecu configuration 5C";
CM_ SG_ 988 EC_BU_ECUCfg11_Stat "Backup for ECU Configuration messages status 11";
CM_ SG_ 988 EC_BU_CBC10A "Backup for CBC ecu configuration 10A";
CM_ SG_ 988 EC_BU_CBC10B "Backup for CBC ecu configuration 10B";
CM_ SG_ 988 EC_BU_CBC11 "Backup for CBC ecu configuration 11";
CM_ SG_ 989 EC_BU_ECUCfg10_Stat "Backup for ECU Configuration messages status 10";
CM_ SG_ 989 EC_BU_Cluster3A "Backup for Instrument cluster ecu configuration 3A";
CM_ SG_ 989 EC_BU_Cluster3B "Backup for Instrument cluster ecu configuration 3B";
CM_ SG_ 989 EC_BU_Cluster4 "Backup for Instrument cluster ecu configuration 4";
CM_ SG_ 991 EC_BU_ECUCfg9_Stat "Backup for ECU Configuration messages status 9";
CM_ SG_ 991 EC_BU_CBC9A1 "Backup for CBC configuration 9A1";
CM_ SG_ 991 EC_BU_CBC9A2 "Backup for CBC configuration 9A2";
CM_ SG_ 991 EC_BU_CBC9B "Backup for CBC configuration 9B";
CM_ SG_ 991 EC_BU_ITM "Backup for ITM ecu configuration";
CM_ SG_ 992 VIN_DATA "VIN Digits (8 bit ascii encoded) - see Signal Description Doc for details";
CM_ SG_ 992 VIN_MSG "VIN Message Information";
CM_ SG_ 993 Manufacture "Engine manufacture";
CM_ SG_ 993 NUM_VALVE "Number of valves per cylinder";
CM_ SG_ 993 ETC_PRSNT "Electronic throttle control";
CM_ SG_ 993 TRANS_TYPE "Transmission type; [0] = manual, [1] = automatic";
CM_ SG_ 993 EngStyle "Engine output version";
CM_ SG_ 993 A580_DATA "A580 engine stored data and CRC";
CM_ SG_ 993 DISPLACEMENT "Engine displacement";
CM_ SG_ 993 NUM_CYL "Number of engine cylinders";
CM_ SG_ 993 SpStPrsnt "Stop start feature present";
CM_ SG_ 993 ENG_ASP "Engine aspiration method";
CM_ SG_ 993 FUEL_TYPE "Fuel type";
CM_ SG_ 993 ECM_Vehi_Type "Engine vehicle type";
CM_ SG_ 995 NetCfg_UPFM "CAN I Upfitter Module (1=present)";
CM_ SG_ 995 NetCfg_TTM "0= Not Present;  1= Present";
CM_ SG_ 995 NetCfg_PSSM "NetCfg PSSM";
CM_ SG_ 995 NetCfg_TBM "Telematics Box Module (1=present)";
CM_ SG_ 995 NetCfg_ICS_R "CAN I Integrated rear Center Stack Module (1=present)";
CM_ SG_ 995 NetCfg_MSM_PASS "CAN I Memory Seat Module Passenger (1=present)";
CM_ SG_ 995 NetCfg_VRM "Video Routing Module (1=present)";
CM_ SG_ 995 NetCfg_VES2_I "CAN I Video Ent. System screen 2 Module (1=present)";
CM_ SG_ 995 NetCfg_VES3_I "CAN I Video Ent. System screen 1 Module (1=present)";
CM_ SG_ 995 NetCfg_CRSM "CAN I Comfort Rear Seat Module (1=present)";
CM_ SG_ 995 NetCfg_HVAC_R "CAN I Rear Heating Ventilation Air Conditioning (1=present)";
CM_ SG_ 995 NetCfg_CVPM "CAN I Central Vision Processing Module (1=present)";
CM_ SG_ 995 NetCfg_AMP_I "CAN I Amplifier Module (1=present)";
CM_ SG_ 995 NetCfg_DVD_CDM "CAN I in-dash disc player module (1=present)";
CM_ SG_ 995 NetCfg_HFM_CTM "Convergence Telematics Module (1=present)";
CM_ SG_ 995 NetCfg_RBC "Rear Body Controller Module (1=present)";
CM_ SG_ 995 NetCfg_DTV "Digital TV Module (1=present)";
CM_ SG_ 995 NetCfg_TGW "Telematics gateway (1=present)";
CM_ SG_ 995 NetCfg_CLOCK "CAN I Clock Module (1=present)";
CM_ SG_ 995 NetCfg_VSIM "Vehicle System Interface Module (1=present)";
CM_ SG_ 995 NetCfg_TGWM "Trailer Gateway Module  (1=present)";
CM_ SG_ 995 NetCfg_RBSS "Right Blind-Spot Module (1=present)";
CM_ SG_ 995 NetCfg_BSM "Blind-Spot Module (1=present)";
CM_ SG_ 995 NetCfg_CBC_IN "Common Body Controller Int Bus (1=present)";
CM_ SG_ 995 NetCfg_CSWM "Comfot Seats and Wheel Module (1=present)";
CM_ SG_ 995 NetCfg_DCM_DR "Door Control Module Driver (1=present)";
CM_ SG_ 995 NetCfg_DCM_PASS "Door Control Module Passenger (1=present)";
CM_ SG_ 995 NetCfg_DCM_RL "Door Control Module Rear Left (1=present)";
CM_ SG_ 995 NetCfg_FSM "Folding Seat Module (1=present)";
CM_ SG_ 995 NET_CFG_STAT_INT "Network configuration status";
CM_ SG_ 995 NetCfg_HVAC "Heating Ventilation Air Conditioning (1=present)";
CM_ SG_ 995 NetCfg_MSM "Memory Seat Module (1=present)";
CM_ SG_ 995 NetCfg_PLG "Power Liftgate Module (1=present)";
CM_ SG_ 995 NetCfg_VTM "Vehicle theft / tax module (1=present)";
CM_ SG_ 995 NetCfg_PSD_LT "Power Sliding Door Left Module (1=present)";
CM_ SG_ 995 NetCfg_DCM_RR "Door Control Module Rear Right (1=present)";
CM_ SG_ 995 NetCfg_PSD_RT "Power Sliding Door Right Module (1=present)";
CM_ SG_ 995 NetCfg_PTCM "Power Top Control Module (1=present)";
CM_ SG_ 995 NetCfg_ITM "Intrusion module (1=present)";
CM_ SG_ 995 NetCfg_ICS_I "CAN I Integrated Center Stack Module (1=present)";
CM_ SG_ 995 NetCfg_TMM "CAN I Track Mapping Module (1=present)";
CM_ SG_ 995 NetCfg_DCSD "Disassociated Center Stack Display Module (1=present)";
CM_ SG_ 995 NetCfg_ANC_I "Active Noise Cancellation interior (1=present)";
BA_DEF_ BO_  "App-Botschaft" ENUM  "nein","ja";
BA_DEF_ BO_  "CanMsgMinLen" INT 0 8;
BA_DEF_ BO_  "DiagRequest" ENUM  "nein","ja";
BA_DEF_ BO_  "DiagResponse" ENUM  "nein","ja";
BA_DEF_ BO_  "DiagState" ENUM  "nein","ja";
BA_DEF_ BO_  "GenMsgCycleTime" INT 0 65535;
BA_DEF_ BO_  "GenMsgCycleTimeActive" INT 0 65535;
BA_DEF_ BO_  "GenMsgDelayTime" INT 0 65535;
BA_DEF_ BO_  "GenMsgNrOfRepetitions" INT 0 65535;
BA_DEF_ BO_  "GenMsgSendType" ENUM  "cyclicX","spontanX","cyclicIfActiveX","spontanWithDelay","cyclicAndSpontanX","cyclicAndSpontanWithDelay","spontanWithRepitition","cyclicIfActiveAndSpontanWD","cyclicIfActiveFast","cyclicWithRepeatOnDemand","none";
BA_DEF_ BO_  "GenMsgStartDelayTime" INT 0 65535;
BA_DEF_ BO_  "GenMsgStartValue" STRING ;
BA_DEF_ BO_  "NWM-Botschaft" ENUM  "nein","ja";
BA_DEF_ BO_  "TpTxIndex" INT 0 99;
BA_DEF_ SG_  "FlexKomComment" STRING ;
BA_DEF_ SG_  "FlexKomIsMotorola" ENUM  "nein","ja";
BA_DEF_ SG_  "FlexKomSID" INT 0 2147483647;
BA_DEF_ SG_  "FlexKomSigLaenge" INT 0 64;
BA_DEF_ SG_  "FlexKomSigName" STRING ;
BA_DEF_ SG_  "FlexKomSigStartPos" INT 0 63;
BA_DEF_ SG_  "FlexKomSigStartValue" STRING ;
BA_DEF_ SG_  "GenSigCycleTime" INT 0 65535;
BA_DEF_ SG_  "GenSigCycleTimeActive" INT 0 65535;
BA_DEF_ SG_  "GenSigSendType" ENUM  "cyclicX","spontanX","cyclicIfActiveX","spontanWithDelay","cyclicAndSpontanX","cyclicAndSpontanWithDelay","spontanWithRepitition","cyclicIfActiveAndSpontanWD","cyclicIfActiveFast","cyclicWithRepeatOnDemand","none";
BA_DEF_ SG_  "GenSigSNA" STRING ;
BA_DEF_ SG_  "GenSigStartValue" HEX 0 2147483648;
BA_DEF_ SG_  "GenSigTimeout_AHLM" INT 0 65535;
BA_DEF_ SG_  "GenSigTimeout_ASBS" INT 0 65535;
BA_DEF_ SG_  "GenSigTimeout_CBC" INT 0 65535;
BA_DEF_ SG_  "GenSigTimeout_DPDM" INT 0 65535;
BA_DEF_ SG_  "GenSigTimeout_DTCM" INT 0 65535;
BA_DEF_ SG_  "GenSigTimeout_EHPS" INT 0 65535;
BA_DEF_ SG_  "GenSigTimeout_ESC" INT 0 65535;
BA_DEF_ SG_  "GenSigTimeout_ESL" INT 0 65535;
BA_DEF_ SG_  "GenSigTimeout_ESM" INT 0 65535;
BA_DEF_ SG_  "GenSigTimeout_ETM" INT 0 65535;
BA_DEF_ SG_  "GenSigTimeout_IC" INT 0 65535;
BA_DEF_ SG_  "GenSigTimeout_OCM" INT 0 65535;
BA_DEF_ SG_  "GenSigTimeout_ORC" INT 0 65535;
BA_DEF_ SG_  "GenSigTimeout_PTS" INT 0 65535;
BA_DEF_ SG_  "GenSigTimeout_RF_HUB" INT 0 65535;
BA_DEF_ SG_  "GenSigTimeout_SCCM" INT 0 65535;
BA_DEF_ SG_  "GenSigTimeout_TBM" INT 0 65535;
BA_DEF_ SG_  "GenSigTimeout_TCM" INT 0 65535;
BA_DEF_ SG_  "GenSigTimeout_TPM" INT 0 65535;
BA_DEF_ SG_  "RID" STRING ;
BA_DEF_ SG_  "SystemSignalLongSymbol" STRING ;
BA_DEF_DEF_  "App-Botschaft" "nein";
BA_DEF_DEF_  "CanMsgMinLen" 0;
BA_DEF_DEF_  "DiagRequest" "nein";
BA_DEF_DEF_  "DiagResponse" "nein";
BA_DEF_DEF_  "DiagState" "nein";
BA_DEF_DEF_  "GenMsgCycleTime" 0;
BA_DEF_DEF_  "GenMsgCycleTimeActive" 0;
BA_DEF_DEF_  "GenMsgDelayTime" 0;
BA_DEF_DEF_  "GenMsgNrOfRepetitions" 0;
BA_DEF_DEF_  "GenMsgSendType" "cyclicX";
BA_DEF_DEF_  "GenMsgStartDelayTime" 0;
BA_DEF_DEF_  "GenMsgStartValue" "";
BA_DEF_DEF_  "NWM-Botschaft" "nein";
BA_DEF_DEF_  "TpTxIndex" 0;
BA_DEF_DEF_  "FlexKomComment" "";
BA_DEF_DEF_  "FlexKomIsMotorola" "nein";
BA_DEF_DEF_  "FlexKomSID" 0;
BA_DEF_DEF_  "FlexKomSigLaenge" 0;
BA_DEF_DEF_  "FlexKomSigName" "";
BA_DEF_DEF_  "FlexKomSigStartPos" 0;
BA_DEF_DEF_  "FlexKomSigStartValue" "";
BA_DEF_DEF_  "GenSigCycleTime" 0;
BA_DEF_DEF_  "GenSigCycleTimeActive" 0;
BA_DEF_DEF_  "GenSigSendType" "cyclicX";
BA_DEF_DEF_  "GenSigSNA" "";
BA_DEF_DEF_  "GenSigStartValue" 0;
BA_DEF_DEF_  "GenSigTimeout_AHLM" 0;
BA_DEF_DEF_  "GenSigTimeout_ASBS" 0;
BA_DEF_DEF_  "GenSigTimeout_CBC" 0;
BA_DEF_DEF_  "GenSigTimeout_DPDM" 0;
BA_DEF_DEF_  "GenSigTimeout_DTCM" 0;
BA_DEF_DEF_  "GenSigTimeout_EHPS" 0;
BA_DEF_DEF_  "GenSigTimeout_ESC" 0;
BA_DEF_DEF_  "GenSigTimeout_ESL" 0;
BA_DEF_DEF_  "GenSigTimeout_ESM" 0;
BA_DEF_DEF_  "GenSigTimeout_ETM" 0;
BA_DEF_DEF_  "GenSigTimeout_IC" 0;
BA_DEF_DEF_  "GenSigTimeout_OCM" 0;
BA_DEF_DEF_  "GenSigTimeout_ORC" 0;
BA_DEF_DEF_  "GenSigTimeout_PTS" 0;
BA_DEF_DEF_  "GenSigTimeout_RF_HUB" 0;
BA_DEF_DEF_  "GenSigTimeout_SCCM" 0;
BA_DEF_DEF_  "GenSigTimeout_TBM" 0;
BA_DEF_DEF_  "GenSigTimeout_TCM" 0;
BA_DEF_DEF_  "GenSigTimeout_TPM" 0;
BA_DEF_DEF_  "RID" "";
BA_DEF_DEF_  "SystemSignalLongSymbol" "";
BA_ "GenMsgStartValue" BO_ 956 "0000000000000000h";
BA_ "GenMsgSendType" BO_ 956 1;
BA_ "GenMsgNrOfRepetitions" BO_ 956 2;
BA_ "GenMsgDelayTime" BO_ 956 20;
BA_ "GenMsgStartValue" BO_ 958 "0000000000000000h";
BA_ "GenMsgStartDelayTime" BO_ 958 300;
BA_ "GenMsgNrOfRepetitions" BO_ 958 2;
BA_ "GenMsgDelayTime" BO_ 958 20;
BA_ "GenMsgCycleTime" BO_ 958 1000;
BA_ "GenMsgStartValue" BO_ 959 "0000000000000000h";
BA_ "GenMsgStartDelayTime" BO_ 959 350;
BA_ "GenMsgNrOfRepetitions" BO_ 959 2;
BA_ "GenMsgDelayTime" BO_ 959 20;
BA_ "GenMsgCycleTime" BO_ 959 1000;
BA_ "GenMsgStartValue" BO_ 962 "0300400000000000h";
BA_ "GenMsgStartDelayTime" BO_ 962 70;
BA_ "GenMsgSendType" BO_ 962 5;
BA_ "GenMsgNrOfRepetitions" BO_ 962 2;
BA_ "GenMsgDelayTime" BO_ 962 20;
BA_ "GenMsgCycleTime" BO_ 962 2000;
BA_ "GenMsgStartValue" BO_ 963 "0300400000000000h";
BA_ "GenMsgStartDelayTime" BO_ 963 70;
BA_ "GenMsgSendType" BO_ 963 1;
BA_ "GenMsgNrOfRepetitions" BO_ 963 2;
BA_ "GenMsgDelayTime" BO_ 963 20;
BA_ "GenMsgStartValue" BO_ 965 "0000000000000000h";
BA_ "GenMsgSendType" BO_ 965 5;
BA_ "GenMsgNrOfRepetitions" BO_ 965 2;
BA_ "GenMsgDelayTime" BO_ 965 20;
BA_ "GenMsgCycleTime" BO_ 965 500;
BA_ "GenMsgStartValue" BO_ 967 "000000FFh";
BA_ "GenMsgSendType" BO_ 967 5;
BA_ "GenMsgNrOfRepetitions" BO_ 967 2;
BA_ "GenMsgDelayTime" BO_ 967 20;
BA_ "GenMsgCycleTime" BO_ 967 200;
BA_ "GenMsgStartValue" BO_ 969 "FFFF0000h";
BA_ "GenMsgNrOfRepetitions" BO_ 969 2;
BA_ "GenMsgDelayTime" BO_ 969 20;
BA_ "GenMsgCycleTime" BO_ 969 1000;
BA_ "GenMsgStartValue" BO_ 973 "0000000000000000h";
BA_ "GenMsgSendType" BO_ 973 5;
BA_ "GenMsgNrOfRepetitions" BO_ 973 2;
BA_ "GenMsgDelayTime" BO_ 973 20;
BA_ "GenMsgCycleTime" BO_ 973 2000;
BA_ "GenMsgStartValue" BO_ 976 "0000000000000000h";
BA_ "GenMsgNrOfRepetitions" BO_ 976 2;
BA_ "GenMsgDelayTime" BO_ 976 20;
BA_ "GenMsgCycleTime" BO_ 976 500;
BA_ "GenMsgStartValue" BO_ 979 "0300000000000000h";
BA_ "GenMsgStartDelayTime" BO_ 979 130;
BA_ "GenMsgNrOfRepetitions" BO_ 979 2;
BA_ "GenMsgDelayTime" BO_ 979 20;
BA_ "GenMsgCycleTime" BO_ 979 2000;
BA_ "GenMsgStartValue" BO_ 980 "0300000000000000h";
BA_ "GenMsgStartDelayTime" BO_ 980 130;
BA_ "GenMsgNrOfRepetitions" BO_ 980 2;
BA_ "GenMsgDelayTime" BO_ 980 20;
BA_ "GenMsgCycleTime" BO_ 980 2000;
BA_ "GenMsgStartValue" BO_ 981 "0300000000000000h";
BA_ "GenMsgStartDelayTime" BO_ 981 120;
BA_ "GenMsgSendType" BO_ 981 5;
BA_ "GenMsgNrOfRepetitions" BO_ 981 2;
BA_ "GenMsgDelayTime" BO_ 981 20;
BA_ "GenMsgCycleTime" BO_ 981 2000;
BA_ "GenMsgStartValue" BO_ 982 "0300000000000000h";
BA_ "GenMsgStartDelayTime" BO_ 982 130;
BA_ "GenMsgNrOfRepetitions" BO_ 982 2;
BA_ "GenMsgDelayTime" BO_ 982 20;
BA_ "GenMsgCycleTime" BO_ 982 2000;
BA_ "GenMsgStartValue" BO_ 983 "0300000000000000h";
BA_ "GenMsgStartDelayTime" BO_ 983 100;
BA_ "GenMsgSendType" BO_ 983 5;
BA_ "GenMsgNrOfRepetitions" BO_ 983 2;
BA_ "GenMsgDelayTime" BO_ 983 20;
BA_ "GenMsgCycleTime" BO_ 983 2000;
BA_ "GenMsgStartValue" BO_ 984 "0300000000000000h";
BA_ "GenMsgStartDelayTime" BO_ 984 90;
BA_ "GenMsgNrOfRepetitions" BO_ 984 2;
BA_ "GenMsgDelayTime" BO_ 984 20;
BA_ "GenMsgCycleTime" BO_ 984 2000;
BA_ "GenMsgStartValue" BO_ 985 "0300000000000000h";
BA_ "GenMsgSendType" BO_ 985 1;
BA_ "GenMsgNrOfRepetitions" BO_ 985 2;
BA_ "GenMsgDelayTime" BO_ 985 20;
BA_ "GenMsgStartValue" BO_ 986 "0300000000000000h";
BA_ "GenMsgSendType" BO_ 986 1;
BA_ "GenMsgNrOfRepetitions" BO_ 986 2;
BA_ "GenMsgDelayTime" BO_ 986 20;
BA_ "GenMsgStartValue" BO_ 987 "0300000000000000h";
BA_ "GenMsgSendType" BO_ 987 1;
BA_ "GenMsgNrOfRepetitions" BO_ 987 2;
BA_ "GenMsgDelayTime" BO_ 987 20;
BA_ "GenMsgStartValue" BO_ 988 "0300000000000000h";
BA_ "GenMsgSendType" BO_ 988 1;
BA_ "GenMsgNrOfRepetitions" BO_ 988 2;
BA_ "GenMsgDelayTime" BO_ 988 20;
BA_ "GenMsgStartValue" BO_ 989 "0300000000000000h";
BA_ "GenMsgSendType" BO_ 989 1;
BA_ "GenMsgNrOfRepetitions" BO_ 989 2;
BA_ "GenMsgDelayTime" BO_ 989 20;
BA_ "GenMsgStartValue" BO_ 991 "0300000000000000h";
BA_ "GenMsgSendType" BO_ 991 1;
BA_ "GenMsgNrOfRepetitions" BO_ 991 2;
BA_ "GenMsgDelayTime" BO_ 991 20;
BA_ "GenMsgStartValue" BO_ 992 "0300000000000000h";
BA_ "GenMsgNrOfRepetitions" BO_ 992 2;
BA_ "GenMsgDelayTime" BO_ 992 20;
BA_ "GenMsgCycleTime" BO_ 992 100;
BA_ "GenMsgStartValue" BO_ 993 "FFEFE7E71F0000h";
BA_ "GenMsgNrOfRepetitions" BO_ 993 2;
BA_ "GenMsgDelayTime" BO_ 993 20;
BA_ "GenMsgCycleTime" BO_ 993 100;
BA_ "GenMsgStartValue" BO_ 995 "0300000000000000h";
BA_ "GenMsgStartDelayTime" BO_ 995 20;
BA_ "GenMsgSendType" BO_ 995 5;
BA_ "GenMsgNrOfRepetitions" BO_ 995 2;
BA_ "GenMsgDelayTime" BO_ 995 20;
BA_ "GenMsgCycleTime" BO_ 995 2000;
BA_ "RID" SG_ 956 NAV_TEXT "1051";
BA_ "GenSigSNA" SG_ 956 NAV_TEXT "0h";
BA_ "GenSigSendType" SG_ 956 NAV_TEXT 1;
BA_ "FlexKomSigStartValue" SG_ 956 NAV_TEXT "0000000000000000h";
BA_ "FlexKomSigStartPos" SG_ 956 NAV_TEXT 7;
BA_ "FlexKomSigName" SG_ 956 NAV_TEXT "NAV_DATA";
BA_ "FlexKomSigLaenge" SG_ 956 NAV_TEXT 64;
BA_ "FlexKomSID" SG_ 956 NAV_TEXT 576;
BA_ "FlexKomIsMotorola" SG_ 956 NAV_TEXT 1;
BA_ "FlexKomComment" SG_ 956 NAV_TEXT "Text data packet transfer from NAV";
BA_ "RID" SG_ 956 NAV_HiGrpMark "1176";
BA_ "GenSigSNA" SG_ 956 NAV_HiGrpMark "0h";
BA_ "GenSigSendType" SG_ 956 NAV_HiGrpMark 1;
BA_ "FlexKomSigStartValue" SG_ 956 NAV_HiGrpMark "0000000000000000h";
BA_ "FlexKomSigStartPos" SG_ 956 NAV_HiGrpMark 7;
BA_ "FlexKomSigName" SG_ 956 NAV_HiGrpMark "NAV_DATA";
BA_ "FlexKomSigLaenge" SG_ 956 NAV_HiGrpMark 64;
BA_ "FlexKomSID" SG_ 956 NAV_HiGrpMark 576;
BA_ "FlexKomIsMotorola" SG_ 956 NAV_HiGrpMark 1;
BA_ "FlexKomComment" SG_ 956 NAV_HiGrpMark "Text data packet transfer from NAV";
BA_ "RID" SG_ 956 NAV_GrpNum "1187";
BA_ "GenSigSNA" SG_ 956 NAV_GrpNum "0h";
BA_ "GenSigSendType" SG_ 956 NAV_GrpNum 1;
BA_ "FlexKomSigStartValue" SG_ 956 NAV_GrpNum "0000000000000000h";
BA_ "FlexKomSigStartPos" SG_ 956 NAV_GrpNum 7;
BA_ "FlexKomSigName" SG_ 956 NAV_GrpNum "NAV_DATA";
BA_ "FlexKomSigLaenge" SG_ 956 NAV_GrpNum 64;
BA_ "FlexKomSID" SG_ 956 NAV_GrpNum 576;
BA_ "FlexKomIsMotorola" SG_ 956 NAV_GrpNum 1;
BA_ "FlexKomComment" SG_ 956 NAV_GrpNum "Text data packet transfer from NAV";
BA_ "RID" SG_ 956 NAV_GrpTyp "1272";
BA_ "GenSigSNA" SG_ 956 NAV_GrpTyp "3Fh";
BA_ "GenSigSendType" SG_ 956 NAV_GrpTyp 1;
BA_ "FlexKomSigStartValue" SG_ 956 NAV_GrpTyp "0000000000000000h";
BA_ "FlexKomSigStartPos" SG_ 956 NAV_GrpTyp 7;
BA_ "FlexKomSigName" SG_ 956 NAV_GrpTyp "NAV_DATA";
BA_ "FlexKomSigLaenge" SG_ 956 NAV_GrpTyp 64;
BA_ "FlexKomSID" SG_ 956 NAV_GrpTyp 576;
BA_ "FlexKomIsMotorola" SG_ 956 NAV_GrpTyp 1;
BA_ "FlexKomComment" SG_ 956 NAV_GrpTyp "Text data packet transfer from NAV";
BA_ "RID" SG_ 958 Electric_Dist_Miles "6515";
BA_ "GenSigTimeout_ETM" SG_ 958 Electric_Dist_Miles 10500;
BA_ "GenSigTimeout_CBC" SG_ 958 Electric_Dist_Miles 10500;
BA_ "GenSigSNA" SG_ 958 Electric_Dist_Miles "3FFh";
BA_ "GenSigCycleTime" SG_ 958 Electric_Dist_Miles 1000;
BA_ "FlexKomSigStartValue" SG_ 958 Electric_Dist_Miles "0000000000000000h";
BA_ "FlexKomSigStartPos" SG_ 958 Electric_Dist_Miles 7;
BA_ "FlexKomSigName" SG_ 958 Electric_Dist_Miles "IC_TripData_Pkt_7";
BA_ "FlexKomSigLaenge" SG_ 958 Electric_Dist_Miles 64;
BA_ "FlexKomSID" SG_ 958 Electric_Dist_Miles 2579;
BA_ "FlexKomIsMotorola" SG_ 958 Electric_Dist_Miles 1;
BA_ "FlexKomComment" SG_ 958 Electric_Dist_Miles "IC Trip data packet 7";
BA_ "RID" SG_ 958 Hybrid_Dist_Miles "6510";
BA_ "GenSigTimeout_ETM" SG_ 958 Hybrid_Dist_Miles 10500;
BA_ "GenSigTimeout_CBC" SG_ 958 Hybrid_Dist_Miles 10500;
BA_ "GenSigSNA" SG_ 958 Hybrid_Dist_Miles "3FFh";
BA_ "GenSigCycleTime" SG_ 958 Hybrid_Dist_Miles 1000;
BA_ "FlexKomSigStartValue" SG_ 958 Hybrid_Dist_Miles "0000000000000000h";
BA_ "FlexKomSigStartPos" SG_ 958 Hybrid_Dist_Miles 7;
BA_ "FlexKomSigName" SG_ 958 Hybrid_Dist_Miles "IC_TripData_Pkt_7";
BA_ "FlexKomSigLaenge" SG_ 958 Hybrid_Dist_Miles 64;
BA_ "FlexKomSID" SG_ 958 Hybrid_Dist_Miles 2579;
BA_ "FlexKomIsMotorola" SG_ 958 Hybrid_Dist_Miles 1;
BA_ "FlexKomComment" SG_ 958 Hybrid_Dist_Miles "IC Trip data packet 7";
BA_ "RID" SG_ 959 Electric_Dist_Kilometers "6511";
BA_ "GenSigTimeout_ETM" SG_ 959 Electric_Dist_Kilometers 10500;
BA_ "GenSigTimeout_CBC" SG_ 959 Electric_Dist_Kilometers 10500;
BA_ "GenSigSNA" SG_ 959 Electric_Dist_Kilometers "3FFh";
BA_ "GenSigCycleTime" SG_ 959 Electric_Dist_Kilometers 1000;
BA_ "FlexKomSigStartValue" SG_ 959 Electric_Dist_Kilometers "0000000000000000h";
BA_ "FlexKomSigStartPos" SG_ 959 Electric_Dist_Kilometers 7;
BA_ "FlexKomSigName" SG_ 959 Electric_Dist_Kilometers "IC_TripData_Pkt_8";
BA_ "FlexKomSigLaenge" SG_ 959 Electric_Dist_Kilometers 64;
BA_ "FlexKomSID" SG_ 959 Electric_Dist_Kilometers 2569;
BA_ "FlexKomIsMotorola" SG_ 959 Electric_Dist_Kilometers 1;
BA_ "FlexKomComment" SG_ 959 Electric_Dist_Kilometers "IC Trip data packet 8";
BA_ "RID" SG_ 959 Hybrid_Dist_Kilometers "6521";
BA_ "GenSigTimeout_ETM" SG_ 959 Hybrid_Dist_Kilometers 10500;
BA_ "GenSigTimeout_CBC" SG_ 959 Hybrid_Dist_Kilometers 10500;
BA_ "GenSigSNA" SG_ 959 Hybrid_Dist_Kilometers "3FFh";
BA_ "GenSigCycleTime" SG_ 959 Hybrid_Dist_Kilometers 1000;
BA_ "FlexKomSigStartValue" SG_ 959 Hybrid_Dist_Kilometers "0000000000000000h";
BA_ "FlexKomSigStartPos" SG_ 959 Hybrid_Dist_Kilometers 7;
BA_ "FlexKomSigName" SG_ 959 Hybrid_Dist_Kilometers "IC_TripData_Pkt_8";
BA_ "FlexKomSigLaenge" SG_ 959 Hybrid_Dist_Kilometers 64;
BA_ "FlexKomSID" SG_ 959 Hybrid_Dist_Kilometers 2569;
BA_ "FlexKomIsMotorola" SG_ 959 Hybrid_Dist_Kilometers 1;
BA_ "FlexKomComment" SG_ 959 Hybrid_Dist_Kilometers "IC Trip data packet 8";
BA_ "GenSigSNA" SG_ 962 VC_LIFT_GATE_RELEASE_CSO "0h";
BA_ "GenSigSendType" SG_ 962 VC_LIFT_GATE_RELEASE_CSO 5;
BA_ "GenSigCycleTime" SG_ 962 VC_LIFT_GATE_RELEASE_CSO 2000;
BA_ "FlexKomSigStartValue" SG_ 962 VC_LIFT_GATE_RELEASE_CSO "0300400000000000h";
BA_ "FlexKomSigStartPos" SG_ 962 VC_LIFT_GATE_RELEASE_CSO 7;
BA_ "FlexKomSigName" SG_ 962 VC_LIFT_GATE_RELEASE_CSO "VehCfgCSM3_Pkt";
BA_ "FlexKomSigLaenge" SG_ 962 VC_LIFT_GATE_RELEASE_CSO 64;
BA_ "FlexKomSID" SG_ 962 VC_LIFT_GATE_RELEASE_CSO 2720;
BA_ "FlexKomIsMotorola" SG_ 962 VC_LIFT_GATE_RELEASE_CSO 1;
BA_ "FlexKomComment" SG_ 962 VC_LIFT_GATE_RELEASE_CSO "Vehicle configuration - customer settings menu 3 P";
BA_ "GenSigSNA" SG_ 962 VC_VISM_KEEP_AWAKE_CSO "0h";
BA_ "GenSigSendType" SG_ 962 VC_VISM_KEEP_AWAKE_CSO 5;
BA_ "GenSigCycleTime" SG_ 962 VC_VISM_KEEP_AWAKE_CSO 2000;
BA_ "FlexKomSigStartValue" SG_ 962 VC_VISM_KEEP_AWAKE_CSO "0300400000000000h";
BA_ "FlexKomSigStartPos" SG_ 962 VC_VISM_KEEP_AWAKE_CSO 7;
BA_ "FlexKomSigName" SG_ 962 VC_VISM_KEEP_AWAKE_CSO "VehCfgCSM3_Pkt";
BA_ "FlexKomSigLaenge" SG_ 962 VC_VISM_KEEP_AWAKE_CSO 64;
BA_ "FlexKomSID" SG_ 962 VC_VISM_KEEP_AWAKE_CSO 2720;
BA_ "FlexKomIsMotorola" SG_ 962 VC_VISM_KEEP_AWAKE_CSO 1;
BA_ "FlexKomComment" SG_ 962 VC_VISM_KEEP_AWAKE_CSO "Vehicle configuration - customer settings menu 3 P";
BA_ "GenSigSNA" SG_ 962 VC_FOA_Presence "0h";
BA_ "GenSigSendType" SG_ 962 VC_FOA_Presence 5;
BA_ "GenSigCycleTime" SG_ 962 VC_FOA_Presence 2000;
BA_ "FlexKomSigStartValue" SG_ 962 VC_FOA_Presence "0300400000000000h";
BA_ "FlexKomSigStartPos" SG_ 962 VC_FOA_Presence 7;
BA_ "FlexKomSigName" SG_ 962 VC_FOA_Presence "VehCfgCSM3_Pkt";
BA_ "FlexKomSigLaenge" SG_ 962 VC_FOA_Presence 64;
BA_ "FlexKomSID" SG_ 962 VC_FOA_Presence 2720;
BA_ "FlexKomIsMotorola" SG_ 962 VC_FOA_Presence 1;
BA_ "FlexKomComment" SG_ 962 VC_FOA_Presence "Vehicle configuration - customer settings menu 3 P";
BA_ "GenSigSNA" SG_ 962 VC_FOA_Type "0h";
BA_ "GenSigSendType" SG_ 962 VC_FOA_Type 5;
BA_ "GenSigCycleTime" SG_ 962 VC_FOA_Type 2000;
BA_ "FlexKomSigStartValue" SG_ 962 VC_FOA_Type "0300400000000000h";
BA_ "FlexKomSigStartPos" SG_ 962 VC_FOA_Type 7;
BA_ "FlexKomSigName" SG_ 962 VC_FOA_Type "VehCfgCSM3_Pkt";
BA_ "FlexKomSigLaenge" SG_ 962 VC_FOA_Type 64;
BA_ "FlexKomSID" SG_ 962 VC_FOA_Type 2720;
BA_ "FlexKomIsMotorola" SG_ 962 VC_FOA_Type 1;
BA_ "FlexKomComment" SG_ 962 VC_FOA_Type "Vehicle configuration - customer settings menu 3 P";
BA_ "GenSigSNA" SG_ 962 VC_CHMSL_DYN_CNTR_CSO "0h";
BA_ "GenSigSendType" SG_ 962 VC_CHMSL_DYN_CNTR_CSO 5;
BA_ "GenSigCycleTime" SG_ 962 VC_CHMSL_DYN_CNTR_CSO 2000;
BA_ "FlexKomSigStartValue" SG_ 962 VC_CHMSL_DYN_CNTR_CSO "0300400000000000h";
BA_ "FlexKomSigStartPos" SG_ 962 VC_CHMSL_DYN_CNTR_CSO 7;
BA_ "FlexKomSigName" SG_ 962 VC_CHMSL_DYN_CNTR_CSO "VehCfgCSM3_Pkt";
BA_ "FlexKomSigLaenge" SG_ 962 VC_CHMSL_DYN_CNTR_CSO 64;
BA_ "FlexKomSID" SG_ 962 VC_CHMSL_DYN_CNTR_CSO 2720;
BA_ "FlexKomIsMotorola" SG_ 962 VC_CHMSL_DYN_CNTR_CSO 1;
BA_ "FlexKomComment" SG_ 962 VC_CHMSL_DYN_CNTR_CSO "Vehicle configuration - customer settings menu 3 P";
BA_ "GenSigStartValue" SG_ 962 VC_VehCfgCSO3_Stat 3;
BA_ "GenSigSNA" SG_ 962 VC_VehCfgCSO3_Stat "3h";
BA_ "GenSigSendType" SG_ 962 VC_VehCfgCSO3_Stat 5;
BA_ "GenSigCycleTime" SG_ 962 VC_VehCfgCSO3_Stat 2000;
BA_ "FlexKomSigStartValue" SG_ 962 VC_VehCfgCSO3_Stat "0300400000000000h";
BA_ "FlexKomSigStartPos" SG_ 962 VC_VehCfgCSO3_Stat 7;
BA_ "FlexKomSigName" SG_ 962 VC_VehCfgCSO3_Stat "VehCfgCSM3_Pkt";
BA_ "FlexKomSigLaenge" SG_ 962 VC_VehCfgCSO3_Stat 64;
BA_ "FlexKomSID" SG_ 962 VC_VehCfgCSO3_Stat 2720;
BA_ "FlexKomIsMotorola" SG_ 962 VC_VehCfgCSO3_Stat 1;
BA_ "FlexKomComment" SG_ 962 VC_VehCfgCSO3_Stat "Vehicle configuration - customer settings menu 3 P";
BA_ "GenSigSNA" SG_ 962 VC_FFC_GRIDLINES_CSO "0h";
BA_ "GenSigSendType" SG_ 962 VC_FFC_GRIDLINES_CSO 5;
BA_ "GenSigCycleTime" SG_ 962 VC_FFC_GRIDLINES_CSO 2000;
BA_ "FlexKomSigStartValue" SG_ 962 VC_FFC_GRIDLINES_CSO "0300400000000000h";
BA_ "FlexKomSigStartPos" SG_ 962 VC_FFC_GRIDLINES_CSO 7;
BA_ "FlexKomSigName" SG_ 962 VC_FFC_GRIDLINES_CSO "VehCfgCSM3_Pkt";
BA_ "FlexKomSigLaenge" SG_ 962 VC_FFC_GRIDLINES_CSO 64;
BA_ "FlexKomSID" SG_ 962 VC_FFC_GRIDLINES_CSO 2720;
BA_ "FlexKomIsMotorola" SG_ 962 VC_FFC_GRIDLINES_CSO 1;
BA_ "FlexKomComment" SG_ 962 VC_FFC_GRIDLINES_CSO "Vehicle configuration - customer settings menu 3 P";
BA_ "GenSigSNA" SG_ 962 VC_RVC_CVPM_DGRID_CSO "0h";
BA_ "GenSigSendType" SG_ 962 VC_RVC_CVPM_DGRID_CSO 5;
BA_ "GenSigCycleTime" SG_ 962 VC_RVC_CVPM_DGRID_CSO 2000;
BA_ "FlexKomSigStartValue" SG_ 962 VC_RVC_CVPM_DGRID_CSO "0300400000000000h";
BA_ "FlexKomSigStartPos" SG_ 962 VC_RVC_CVPM_DGRID_CSO 7;
BA_ "FlexKomSigName" SG_ 962 VC_RVC_CVPM_DGRID_CSO "VehCfgCSM3_Pkt";
BA_ "FlexKomSigLaenge" SG_ 962 VC_RVC_CVPM_DGRID_CSO 64;
BA_ "FlexKomSID" SG_ 962 VC_RVC_CVPM_DGRID_CSO 2720;
BA_ "FlexKomIsMotorola" SG_ 962 VC_RVC_CVPM_DGRID_CSO 1;
BA_ "FlexKomComment" SG_ 962 VC_RVC_CVPM_DGRID_CSO "Vehicle configuration - customer settings menu 3 P";
BA_ "GenSigSNA" SG_ 962 VC_RVC_CVPM_SGRID_CSO "0h";
BA_ "GenSigSendType" SG_ 962 VC_RVC_CVPM_SGRID_CSO 5;
BA_ "GenSigCycleTime" SG_ 962 VC_RVC_CVPM_SGRID_CSO 2000;
BA_ "FlexKomSigStartValue" SG_ 962 VC_RVC_CVPM_SGRID_CSO "0300400000000000h";
BA_ "FlexKomSigStartPos" SG_ 962 VC_RVC_CVPM_SGRID_CSO 7;
BA_ "FlexKomSigName" SG_ 962 VC_RVC_CVPM_SGRID_CSO "VehCfgCSM3_Pkt";
BA_ "FlexKomSigLaenge" SG_ 962 VC_RVC_CVPM_SGRID_CSO 64;
BA_ "FlexKomSID" SG_ 962 VC_RVC_CVPM_SGRID_CSO 2720;
BA_ "FlexKomIsMotorola" SG_ 962 VC_RVC_CVPM_SGRID_CSO 1;
BA_ "FlexKomComment" SG_ 962 VC_RVC_CVPM_SGRID_CSO "Vehicle configuration - customer settings menu 3 P";
BA_ "GenSigSNA" SG_ 962 VC_PEB_CSO "0h";
BA_ "GenSigSendType" SG_ 962 VC_PEB_CSO 5;
BA_ "GenSigCycleTime" SG_ 962 VC_PEB_CSO 2000;
BA_ "FlexKomSigStartValue" SG_ 962 VC_PEB_CSO "0300400000000000h";
BA_ "FlexKomSigStartPos" SG_ 962 VC_PEB_CSO 7;
BA_ "FlexKomSigName" SG_ 962 VC_PEB_CSO "VehCfgCSM3_Pkt";
BA_ "FlexKomSigLaenge" SG_ 962 VC_PEB_CSO 64;
BA_ "FlexKomSID" SG_ 962 VC_PEB_CSO 2720;
BA_ "FlexKomIsMotorola" SG_ 962 VC_PEB_CSO 1;
BA_ "FlexKomComment" SG_ 962 VC_PEB_CSO "Vehicle configuration - customer settings menu 3 P";
BA_ "GenSigSNA" SG_ 962 VC_FT_PK_LOOSE_SHIP_CSO "0h";
BA_ "GenSigSendType" SG_ 962 VC_FT_PK_LOOSE_SHIP_CSO 5;
BA_ "GenSigCycleTime" SG_ 962 VC_FT_PK_LOOSE_SHIP_CSO 2000;
BA_ "FlexKomSigStartValue" SG_ 962 VC_FT_PK_LOOSE_SHIP_CSO "0300400000000000h";
BA_ "FlexKomSigStartPos" SG_ 962 VC_FT_PK_LOOSE_SHIP_CSO 7;
BA_ "FlexKomSigName" SG_ 962 VC_FT_PK_LOOSE_SHIP_CSO "VehCfgCSM3_Pkt";
BA_ "FlexKomSigLaenge" SG_ 962 VC_FT_PK_LOOSE_SHIP_CSO 64;
BA_ "FlexKomSID" SG_ 962 VC_FT_PK_LOOSE_SHIP_CSO 2720;
BA_ "FlexKomIsMotorola" SG_ 962 VC_FT_PK_LOOSE_SHIP_CSO 1;
BA_ "FlexKomComment" SG_ 962 VC_FT_PK_LOOSE_SHIP_CSO "Vehicle configuration - customer settings menu 3 P";
BA_ "GenSigSNA" SG_ 962 VC_RR_PK_LOOSE_SHIP_CSO "0h";
BA_ "GenSigSendType" SG_ 962 VC_RR_PK_LOOSE_SHIP_CSO 5;
BA_ "GenSigCycleTime" SG_ 962 VC_RR_PK_LOOSE_SHIP_CSO 2000;
BA_ "FlexKomSigStartValue" SG_ 962 VC_RR_PK_LOOSE_SHIP_CSO "0300400000000000h";
BA_ "FlexKomSigStartPos" SG_ 962 VC_RR_PK_LOOSE_SHIP_CSO 7;
BA_ "FlexKomSigName" SG_ 962 VC_RR_PK_LOOSE_SHIP_CSO "VehCfgCSM3_Pkt";
BA_ "FlexKomSigLaenge" SG_ 962 VC_RR_PK_LOOSE_SHIP_CSO 64;
BA_ "FlexKomSID" SG_ 962 VC_RR_PK_LOOSE_SHIP_CSO 2720;
BA_ "FlexKomIsMotorola" SG_ 962 VC_RR_PK_LOOSE_SHIP_CSO 1;
BA_ "FlexKomComment" SG_ 962 VC_RR_PK_LOOSE_SHIP_CSO "Vehicle configuration - customer settings menu 3 P";
BA_ "GenSigSNA" SG_ 962 VC_ESAVE_CSO "0h";
BA_ "GenSigSendType" SG_ 962 VC_ESAVE_CSO 5;
BA_ "GenSigCycleTime" SG_ 962 VC_ESAVE_CSO 2000;
BA_ "FlexKomSigStartValue" SG_ 962 VC_ESAVE_CSO "0300400000000000h";
BA_ "FlexKomSigStartPos" SG_ 962 VC_ESAVE_CSO 7;
BA_ "FlexKomSigName" SG_ 962 VC_ESAVE_CSO "VehCfgCSM3_Pkt";
BA_ "FlexKomSigLaenge" SG_ 962 VC_ESAVE_CSO 64;
BA_ "FlexKomSID" SG_ 962 VC_ESAVE_CSO 2720;
BA_ "FlexKomIsMotorola" SG_ 962 VC_ESAVE_CSO 1;
BA_ "FlexKomComment" SG_ 962 VC_ESAVE_CSO "E-Save Enable/Disable customer settings menu";
BA_ "GenSigSNA" SG_ 962 VC_ESAVE_BATT_LVL_CSO "0h";
BA_ "GenSigSendType" SG_ 962 VC_ESAVE_BATT_LVL_CSO 5;
BA_ "GenSigCycleTime" SG_ 962 VC_ESAVE_BATT_LVL_CSO 2000;
BA_ "FlexKomSigStartValue" SG_ 962 VC_ESAVE_BATT_LVL_CSO "0300400000000000h";
BA_ "FlexKomSigStartPos" SG_ 962 VC_ESAVE_BATT_LVL_CSO 7;
BA_ "FlexKomSigName" SG_ 962 VC_ESAVE_BATT_LVL_CSO "VehCfgCSM3_Pkt";
BA_ "FlexKomSigLaenge" SG_ 962 VC_ESAVE_BATT_LVL_CSO 64;
BA_ "FlexKomSID" SG_ 962 VC_ESAVE_BATT_LVL_CSO 2720;
BA_ "FlexKomIsMotorola" SG_ 962 VC_ESAVE_BATT_LVL_CSO 1;
BA_ "FlexKomComment" SG_ 962 VC_ESAVE_BATT_LVL_CSO "E-Save Battery Level customer settings menu";
BA_ "GenSigSNA" SG_ 962 VC_AL_OR_PLUS_CSO "0h";
BA_ "GenSigSendType" SG_ 962 VC_AL_OR_PLUS_CSO 5;
BA_ "GenSigCycleTime" SG_ 962 VC_AL_OR_PLUS_CSO 2000;
BA_ "FlexKomSigStartValue" SG_ 962 VC_AL_OR_PLUS_CSO "0300400000000000h";
BA_ "FlexKomSigStartPos" SG_ 962 VC_AL_OR_PLUS_CSO 7;
BA_ "FlexKomSigName" SG_ 962 VC_AL_OR_PLUS_CSO "VehCfgCSM3_Pkt";
BA_ "FlexKomSigLaenge" SG_ 962 VC_AL_OR_PLUS_CSO 64;
BA_ "FlexKomSID" SG_ 962 VC_AL_OR_PLUS_CSO 2720;
BA_ "FlexKomIsMotorola" SG_ 962 VC_AL_OR_PLUS_CSO 1;
BA_ "FlexKomComment" SG_ 962 VC_AL_OR_PLUS_CSO "Vehicle configuration - customer settings menu 3 P";
BA_ "GenSigSNA" SG_ 962 VC_TSR_WARNING_MODE_CSO "0h";
BA_ "GenSigSendType" SG_ 962 VC_TSR_WARNING_MODE_CSO 5;
BA_ "GenSigCycleTime" SG_ 962 VC_TSR_WARNING_MODE_CSO 2000;
BA_ "FlexKomSigStartValue" SG_ 962 VC_TSR_WARNING_MODE_CSO "0300400000000000h";
BA_ "FlexKomSigStartPos" SG_ 962 VC_TSR_WARNING_MODE_CSO 7;
BA_ "FlexKomSigName" SG_ 962 VC_TSR_WARNING_MODE_CSO "VehCfgCSM3_Pkt";
BA_ "FlexKomSigLaenge" SG_ 962 VC_TSR_WARNING_MODE_CSO 64;
BA_ "FlexKomSID" SG_ 962 VC_TSR_WARNING_MODE_CSO 2720;
BA_ "FlexKomIsMotorola" SG_ 962 VC_TSR_WARNING_MODE_CSO 1;
BA_ "FlexKomComment" SG_ 962 VC_TSR_WARNING_MODE_CSO "Vehicle configuration - customer settings menu 3 P";
BA_ "GenSigSNA" SG_ 962 VC_TSR_WARNING_MODE_OFFSET_CSO "0h";
BA_ "GenSigSendType" SG_ 962 VC_TSR_WARNING_MODE_OFFSET_CSO 5;
BA_ "GenSigCycleTime" SG_ 962 VC_TSR_WARNING_MODE_OFFSET_CSO 2000;
BA_ "FlexKomSigStartValue" SG_ 962 VC_TSR_WARNING_MODE_OFFSET_CSO "0300400000000000h";
BA_ "FlexKomSigStartPos" SG_ 962 VC_TSR_WARNING_MODE_OFFSET_CSO 7;
BA_ "FlexKomSigName" SG_ 962 VC_TSR_WARNING_MODE_OFFSET_CSO "VehCfgCSM3_Pkt";
BA_ "FlexKomSigLaenge" SG_ 962 VC_TSR_WARNING_MODE_OFFSET_CSO 64;
BA_ "FlexKomSID" SG_ 962 VC_TSR_WARNING_MODE_OFFSET_CSO 2720;
BA_ "FlexKomIsMotorola" SG_ 962 VC_TSR_WARNING_MODE_OFFSET_CSO 1;
BA_ "FlexKomComment" SG_ 962 VC_TSR_WARNING_MODE_OFFSET_CSO "Vehicle configuration - customer settings menu 3 P";
BA_ "GenSigSNA" SG_ 962 VC_3RD_ROW_LOCK_CSO "0h";
BA_ "GenSigSendType" SG_ 962 VC_3RD_ROW_LOCK_CSO 5;
BA_ "GenSigCycleTime" SG_ 962 VC_3RD_ROW_LOCK_CSO 2000;
BA_ "FlexKomSigStartValue" SG_ 962 VC_3RD_ROW_LOCK_CSO "0300400000000000h";
BA_ "FlexKomSigStartPos" SG_ 962 VC_3RD_ROW_LOCK_CSO 7;
BA_ "FlexKomSigName" SG_ 962 VC_3RD_ROW_LOCK_CSO "VehCfgCSM3_Pkt";
BA_ "FlexKomSigLaenge" SG_ 962 VC_3RD_ROW_LOCK_CSO 64;
BA_ "FlexKomSID" SG_ 962 VC_3RD_ROW_LOCK_CSO 2720;
BA_ "FlexKomIsMotorola" SG_ 962 VC_3RD_ROW_LOCK_CSO 1;
BA_ "FlexKomComment" SG_ 962 VC_3RD_ROW_LOCK_CSO "Vehicle configuration - customer settings menu 3 P";
BA_ "GenSigSNA" SG_ 962 VC_CHARGE_LOW_POPUP_CSO "0h";
BA_ "GenSigSendType" SG_ 962 VC_CHARGE_LOW_POPUP_CSO 5;
BA_ "GenSigCycleTime" SG_ 962 VC_CHARGE_LOW_POPUP_CSO 2000;
BA_ "FlexKomSigStartValue" SG_ 962 VC_CHARGE_LOW_POPUP_CSO "0300400000000000h";
BA_ "FlexKomSigStartPos" SG_ 962 VC_CHARGE_LOW_POPUP_CSO 7;
BA_ "FlexKomSigName" SG_ 962 VC_CHARGE_LOW_POPUP_CSO "VehCfgCSM3_Pkt";
BA_ "FlexKomSigLaenge" SG_ 962 VC_CHARGE_LOW_POPUP_CSO 64;
BA_ "FlexKomSID" SG_ 962 VC_CHARGE_LOW_POPUP_CSO 2720;
BA_ "FlexKomIsMotorola" SG_ 962 VC_CHARGE_LOW_POPUP_CSO 1;
BA_ "FlexKomComment" SG_ 962 VC_CHARGE_LOW_POPUP_CSO "Vehicle configuration - customer settings menu 3 P";
BA_ "GenSigSNA" SG_ 962 VC_FOBIK_SAFE_CSO "0h";
BA_ "GenSigSendType" SG_ 962 VC_FOBIK_SAFE_CSO 5;
BA_ "GenSigCycleTime" SG_ 962 VC_FOBIK_SAFE_CSO 2000;
BA_ "FlexKomSigStartValue" SG_ 962 VC_FOBIK_SAFE_CSO "0300400000000000h";
BA_ "FlexKomSigStartPos" SG_ 962 VC_FOBIK_SAFE_CSO 7;
BA_ "FlexKomSigName" SG_ 962 VC_FOBIK_SAFE_CSO "VehCfgCSM3_Pkt";
BA_ "FlexKomSigLaenge" SG_ 962 VC_FOBIK_SAFE_CSO 64;
BA_ "FlexKomSID" SG_ 962 VC_FOBIK_SAFE_CSO 2720;
BA_ "FlexKomIsMotorola" SG_ 962 VC_FOBIK_SAFE_CSO 1;
BA_ "FlexKomComment" SG_ 962 VC_FOBIK_SAFE_CSO "Vehicle configuration - customer settings menu 3 P";
BA_ "GenSigSNA" SG_ 962 VC_FOB_LEFT_VEHICLE_CHIME_CSO "0h";
BA_ "GenSigSendType" SG_ 962 VC_FOB_LEFT_VEHICLE_CHIME_CSO 5;
BA_ "GenSigCycleTime" SG_ 962 VC_FOB_LEFT_VEHICLE_CHIME_CSO 2000;
BA_ "FlexKomSigStartValue" SG_ 962 VC_FOB_LEFT_VEHICLE_CHIME_CSO "0300400000000000h";
BA_ "FlexKomSigStartPos" SG_ 962 VC_FOB_LEFT_VEHICLE_CHIME_CSO 7;
BA_ "FlexKomSigName" SG_ 962 VC_FOB_LEFT_VEHICLE_CHIME_CSO "VehCfgCSM3_Pkt";
BA_ "FlexKomSigLaenge" SG_ 962 VC_FOB_LEFT_VEHICLE_CHIME_CSO 64;
BA_ "FlexKomSID" SG_ 962 VC_FOB_LEFT_VEHICLE_CHIME_CSO 2720;
BA_ "FlexKomIsMotorola" SG_ 962 VC_FOB_LEFT_VEHICLE_CHIME_CSO 1;
BA_ "FlexKomComment" SG_ 962 VC_FOB_LEFT_VEHICLE_CHIME_CSO "Vehicle configuration - customer settings menu 3 P";
BA_ "GenSigSNA" SG_ 962 VC_THEFT_ALARM_CSO "0h";
BA_ "GenSigSendType" SG_ 962 VC_THEFT_ALARM_CSO 5;
BA_ "GenSigCycleTime" SG_ 962 VC_THEFT_ALARM_CSO 2000;
BA_ "FlexKomSigStartValue" SG_ 962 VC_THEFT_ALARM_CSO "0300400000000000h";
BA_ "FlexKomSigStartPos" SG_ 962 VC_THEFT_ALARM_CSO 7;
BA_ "FlexKomSigName" SG_ 962 VC_THEFT_ALARM_CSO "VehCfgCSM3_Pkt";
BA_ "FlexKomSigLaenge" SG_ 962 VC_THEFT_ALARM_CSO 64;
BA_ "FlexKomSID" SG_ 962 VC_THEFT_ALARM_CSO 2720;
BA_ "FlexKomIsMotorola" SG_ 962 VC_THEFT_ALARM_CSO 1;
BA_ "FlexKomComment" SG_ 962 VC_THEFT_ALARM_CSO "Vehicle configuration - customer settings menu 3 P";
BA_ "GenSigSNA" SG_ 962 VC_PANIC_ALARM_CSO "0h";
BA_ "GenSigSendType" SG_ 962 VC_PANIC_ALARM_CSO 5;
BA_ "GenSigCycleTime" SG_ 962 VC_PANIC_ALARM_CSO 2000;
BA_ "FlexKomSigStartValue" SG_ 962 VC_PANIC_ALARM_CSO "0300400000000000h";
BA_ "FlexKomSigStartPos" SG_ 962 VC_PANIC_ALARM_CSO 7;
BA_ "FlexKomSigName" SG_ 962 VC_PANIC_ALARM_CSO "VehCfgCSM3_Pkt";
BA_ "FlexKomSigLaenge" SG_ 962 VC_PANIC_ALARM_CSO 64;
BA_ "FlexKomSID" SG_ 962 VC_PANIC_ALARM_CSO 2720;
BA_ "FlexKomIsMotorola" SG_ 962 VC_PANIC_ALARM_CSO 1;
BA_ "FlexKomComment" SG_ 962 VC_PANIC_ALARM_CSO "Vehicle configuration - customer settings menu 3 P";
BA_ "GenSigSNA" SG_ 962 VC_SECURE_PARK_CSO "0h";
BA_ "GenSigSendType" SG_ 962 VC_SECURE_PARK_CSO 5;
BA_ "GenSigCycleTime" SG_ 962 VC_SECURE_PARK_CSO 2000;
BA_ "FlexKomSigStartValue" SG_ 962 VC_SECURE_PARK_CSO "0300400000000000h";
BA_ "FlexKomSigStartPos" SG_ 962 VC_SECURE_PARK_CSO 7;
BA_ "FlexKomSigName" SG_ 962 VC_SECURE_PARK_CSO "VehCfgCSM3_Pkt";
BA_ "FlexKomSigLaenge" SG_ 962 VC_SECURE_PARK_CSO 64;
BA_ "FlexKomSID" SG_ 962 VC_SECURE_PARK_CSO 2720;
BA_ "FlexKomIsMotorola" SG_ 962 VC_SECURE_PARK_CSO 1;
BA_ "FlexKomComment" SG_ 962 VC_SECURE_PARK_CSO "Vehicle configuration - customer settings menu 3 P";
BA_ "GenSigSNA" SG_ 963 VC_BU_TSR_WARNING_MODE_CSO "0h";
BA_ "GenSigSendType" SG_ 963 VC_BU_TSR_WARNING_MODE_CSO 1;
BA_ "FlexKomSigStartValue" SG_ 963 VC_BU_TSR_WARNING_MODE_CSO "0300400000000000h";
BA_ "FlexKomSigStartPos" SG_ 963 VC_BU_TSR_WARNING_MODE_CSO 7;
BA_ "FlexKomSigName" SG_ 963 VC_BU_TSR_WARNING_MODE_CSO "VehCfgCSM3_BuPkt";
BA_ "FlexKomSigLaenge" SG_ 963 VC_BU_TSR_WARNING_MODE_CSO 64;
BA_ "FlexKomSID" SG_ 963 VC_BU_TSR_WARNING_MODE_CSO 2721;
BA_ "FlexKomIsMotorola" SG_ 963 VC_BU_TSR_WARNING_MODE_CSO 1;
BA_ "FlexKomComment" SG_ 963 VC_BU_TSR_WARNING_MODE_CSO "Backup for veh config - customer settings menu 3 p";
BA_ "GenSigSNA" SG_ 963 VC_BU_TSR_WARNING_MODE_OFFSET_CS "0h";
BA_ "GenSigSendType" SG_ 963 VC_BU_TSR_WARNING_MODE_OFFSET_CS 1;
BA_ "FlexKomSigStartValue" SG_ 963 VC_BU_TSR_WARNING_MODE_OFFSET_CS "0300400000000000h";
BA_ "FlexKomSigStartPos" SG_ 963 VC_BU_TSR_WARNING_MODE_OFFSET_CS 7;
BA_ "FlexKomSigName" SG_ 963 VC_BU_TSR_WARNING_MODE_OFFSET_CS "VehCfgCSM3_BuPkt";
BA_ "FlexKomSigLaenge" SG_ 963 VC_BU_TSR_WARNING_MODE_OFFSET_CS 64;
BA_ "FlexKomSID" SG_ 963 VC_BU_TSR_WARNING_MODE_OFFSET_CS 2721;
BA_ "FlexKomIsMotorola" SG_ 963 VC_BU_TSR_WARNING_MODE_OFFSET_CS 1;
BA_ "FlexKomComment" SG_ 963 VC_BU_TSR_WARNING_MODE_OFFSET_CS "Backup for veh config - customer settings menu 3 p";
BA_ "SystemSignalLongSymbol" SG_ 963 VC_BU_TSR_WARNING_MODE_OFFSET_CS "VC_BU_TSR_WARNING_MODE_OFFSET_CSO";
BA_ "GenSigSNA" SG_ 963 VC_BU_3RD_ROW_LOCK_CSO "0h";
BA_ "GenSigSendType" SG_ 963 VC_BU_3RD_ROW_LOCK_CSO 1;
BA_ "FlexKomSigStartValue" SG_ 963 VC_BU_3RD_ROW_LOCK_CSO "0300400000000000h";
BA_ "FlexKomSigStartPos" SG_ 963 VC_BU_3RD_ROW_LOCK_CSO 7;
BA_ "FlexKomSigName" SG_ 963 VC_BU_3RD_ROW_LOCK_CSO "VehCfgCSM3_BuPkt";
BA_ "FlexKomSigLaenge" SG_ 963 VC_BU_3RD_ROW_LOCK_CSO 64;
BA_ "FlexKomSID" SG_ 963 VC_BU_3RD_ROW_LOCK_CSO 2721;
BA_ "FlexKomIsMotorola" SG_ 963 VC_BU_3RD_ROW_LOCK_CSO 1;
BA_ "FlexKomComment" SG_ 963 VC_BU_3RD_ROW_LOCK_CSO "Backup for veh config - customer settings menu 3 p";
BA_ "GenSigSNA" SG_ 963 VC_BU_CHARGE_LOW_POPUP_CSO "0h";
BA_ "GenSigSendType" SG_ 963 VC_BU_CHARGE_LOW_POPUP_CSO 1;
BA_ "FlexKomSigStartValue" SG_ 963 VC_BU_CHARGE_LOW_POPUP_CSO "0300400000000000h";
BA_ "FlexKomSigStartPos" SG_ 963 VC_BU_CHARGE_LOW_POPUP_CSO 7;
BA_ "FlexKomSigName" SG_ 963 VC_BU_CHARGE_LOW_POPUP_CSO "VehCfgCSM3_BuPkt";
BA_ "FlexKomSigLaenge" SG_ 963 VC_BU_CHARGE_LOW_POPUP_CSO 64;
BA_ "FlexKomSID" SG_ 963 VC_BU_CHARGE_LOW_POPUP_CSO 2721;
BA_ "FlexKomIsMotorola" SG_ 963 VC_BU_CHARGE_LOW_POPUP_CSO 1;
BA_ "FlexKomComment" SG_ 963 VC_BU_CHARGE_LOW_POPUP_CSO "Backup for veh config - customer settings menu 3 p";
BA_ "GenSigSNA" SG_ 963 VC_BU_FOA_Presence "0h";
BA_ "GenSigSendType" SG_ 963 VC_BU_FOA_Presence 1;
BA_ "FlexKomSigStartValue" SG_ 963 VC_BU_FOA_Presence "0300400000000000h";
BA_ "FlexKomSigStartPos" SG_ 963 VC_BU_FOA_Presence 7;
BA_ "FlexKomSigName" SG_ 963 VC_BU_FOA_Presence "VehCfgCSM3_BuPkt";
BA_ "FlexKomSigLaenge" SG_ 963 VC_BU_FOA_Presence 64;
BA_ "FlexKomSID" SG_ 963 VC_BU_FOA_Presence 2721;
BA_ "FlexKomIsMotorola" SG_ 963 VC_BU_FOA_Presence 1;
BA_ "FlexKomComment" SG_ 963 VC_BU_FOA_Presence "Backup for veh config - customer settings menu 3 p";
BA_ "GenSigSNA" SG_ 963 VC_BU_FOA_Type "0h";
BA_ "GenSigSendType" SG_ 963 VC_BU_FOA_Type 1;
BA_ "FlexKomSigStartValue" SG_ 963 VC_BU_FOA_Type "0300400000000000h";
BA_ "FlexKomSigStartPos" SG_ 963 VC_BU_FOA_Type 7;
BA_ "FlexKomSigName" SG_ 963 VC_BU_FOA_Type "VehCfgCSM3_BuPkt";
BA_ "FlexKomSigLaenge" SG_ 963 VC_BU_FOA_Type 64;
BA_ "FlexKomSID" SG_ 963 VC_BU_FOA_Type 2721;
BA_ "FlexKomIsMotorola" SG_ 963 VC_BU_FOA_Type 1;
BA_ "FlexKomComment" SG_ 963 VC_BU_FOA_Type "Backup for veh config - customer settings menu 3 p";
BA_ "GenSigSNA" SG_ 963 VC_BU_FOBIK_SAFE_CSO "0h";
BA_ "GenSigSendType" SG_ 963 VC_BU_FOBIK_SAFE_CSO 1;
BA_ "FlexKomSigStartValue" SG_ 963 VC_BU_FOBIK_SAFE_CSO "0300400000000000h";
BA_ "FlexKomSigStartPos" SG_ 963 VC_BU_FOBIK_SAFE_CSO 7;
BA_ "FlexKomSigName" SG_ 963 VC_BU_FOBIK_SAFE_CSO "VehCfgCSM3_BuPkt";
BA_ "FlexKomSigLaenge" SG_ 963 VC_BU_FOBIK_SAFE_CSO 64;
BA_ "FlexKomSID" SG_ 963 VC_BU_FOBIK_SAFE_CSO 2721;
BA_ "FlexKomIsMotorola" SG_ 963 VC_BU_FOBIK_SAFE_CSO 1;
BA_ "FlexKomComment" SG_ 963 VC_BU_FOBIK_SAFE_CSO "Backup for veh config - customer settings menu 3 p";
BA_ "GenSigSNA" SG_ 963 VC_BU_FOB_LEFT_VEHICLE_CHIME_CSO "0h";
BA_ "GenSigSendType" SG_ 963 VC_BU_FOB_LEFT_VEHICLE_CHIME_CSO 1;
BA_ "FlexKomSigStartValue" SG_ 963 VC_BU_FOB_LEFT_VEHICLE_CHIME_CSO "0300400000000000h";
BA_ "FlexKomSigStartPos" SG_ 963 VC_BU_FOB_LEFT_VEHICLE_CHIME_CSO 7;
BA_ "FlexKomSigName" SG_ 963 VC_BU_FOB_LEFT_VEHICLE_CHIME_CSO "VehCfgCSM3_BuPkt";
BA_ "FlexKomSigLaenge" SG_ 963 VC_BU_FOB_LEFT_VEHICLE_CHIME_CSO 64;
BA_ "FlexKomSID" SG_ 963 VC_BU_FOB_LEFT_VEHICLE_CHIME_CSO 2721;
BA_ "FlexKomIsMotorola" SG_ 963 VC_BU_FOB_LEFT_VEHICLE_CHIME_CSO 1;
BA_ "FlexKomComment" SG_ 963 VC_BU_FOB_LEFT_VEHICLE_CHIME_CSO "Backup for veh config - customer settings menu 3 p";
BA_ "GenSigSNA" SG_ 963 VC_BU_THEFT_ALARM_CSO "0h";
BA_ "GenSigSendType" SG_ 963 VC_BU_THEFT_ALARM_CSO 1;
BA_ "FlexKomSigStartValue" SG_ 963 VC_BU_THEFT_ALARM_CSO "0300400000000000h";
BA_ "FlexKomSigStartPos" SG_ 963 VC_BU_THEFT_ALARM_CSO 7;
BA_ "FlexKomSigName" SG_ 963 VC_BU_THEFT_ALARM_CSO "VehCfgCSM3_BuPkt";
BA_ "FlexKomSigLaenge" SG_ 963 VC_BU_THEFT_ALARM_CSO 64;
BA_ "FlexKomSID" SG_ 963 VC_BU_THEFT_ALARM_CSO 2721;
BA_ "FlexKomIsMotorola" SG_ 963 VC_BU_THEFT_ALARM_CSO 1;
BA_ "FlexKomComment" SG_ 963 VC_BU_THEFT_ALARM_CSO "Backup for veh config - customer settings menu 3 p";
BA_ "GenSigSNA" SG_ 963 VC_BU_PANIC_ALARM_CSO "0h";
BA_ "GenSigSendType" SG_ 963 VC_BU_PANIC_ALARM_CSO 1;
BA_ "FlexKomSigStartValue" SG_ 963 VC_BU_PANIC_ALARM_CSO "0300400000000000h";
BA_ "FlexKomSigStartPos" SG_ 963 VC_BU_PANIC_ALARM_CSO 7;
BA_ "FlexKomSigName" SG_ 963 VC_BU_PANIC_ALARM_CSO "VehCfgCSM3_BuPkt";
BA_ "FlexKomSigLaenge" SG_ 963 VC_BU_PANIC_ALARM_CSO 64;
BA_ "FlexKomSID" SG_ 963 VC_BU_PANIC_ALARM_CSO 2721;
BA_ "FlexKomIsMotorola" SG_ 963 VC_BU_PANIC_ALARM_CSO 1;
BA_ "FlexKomComment" SG_ 963 VC_BU_PANIC_ALARM_CSO "Backup for veh config - customer settings menu 3 p";
BA_ "GenSigSNA" SG_ 963 VC_BU_SECURE_PARK_CSO "0h";
BA_ "GenSigSendType" SG_ 963 VC_BU_SECURE_PARK_CSO 1;
BA_ "FlexKomSigStartValue" SG_ 963 VC_BU_SECURE_PARK_CSO "0300400000000000h";
BA_ "FlexKomSigStartPos" SG_ 963 VC_BU_SECURE_PARK_CSO 7;
BA_ "FlexKomSigName" SG_ 963 VC_BU_SECURE_PARK_CSO "VehCfgCSM3_BuPkt";
BA_ "FlexKomSigLaenge" SG_ 963 VC_BU_SECURE_PARK_CSO 64;
BA_ "FlexKomSID" SG_ 963 VC_BU_SECURE_PARK_CSO 2721;
BA_ "FlexKomIsMotorola" SG_ 963 VC_BU_SECURE_PARK_CSO 1;
BA_ "FlexKomComment" SG_ 963 VC_BU_SECURE_PARK_CSO "Backup for veh config - customer settings menu 3 p";
BA_ "GenSigSNA" SG_ 963 VC_BU_LIFT_GATE_RELEASE_CSO "0h";
BA_ "GenSigSendType" SG_ 963 VC_BU_LIFT_GATE_RELEASE_CSO 1;
BA_ "FlexKomSigStartValue" SG_ 963 VC_BU_LIFT_GATE_RELEASE_CSO "0300400000000000h";
BA_ "FlexKomSigStartPos" SG_ 963 VC_BU_LIFT_GATE_RELEASE_CSO 7;
BA_ "FlexKomSigName" SG_ 963 VC_BU_LIFT_GATE_RELEASE_CSO "VehCfgCSM3_BuPkt";
BA_ "FlexKomSigLaenge" SG_ 963 VC_BU_LIFT_GATE_RELEASE_CSO 64;
BA_ "FlexKomSID" SG_ 963 VC_BU_LIFT_GATE_RELEASE_CSO 2721;
BA_ "FlexKomIsMotorola" SG_ 963 VC_BU_LIFT_GATE_RELEASE_CSO 1;
BA_ "FlexKomComment" SG_ 963 VC_BU_LIFT_GATE_RELEASE_CSO "Backup for veh config - customer settings menu 3 p";
BA_ "GenSigSNA" SG_ 963 VC_BU_VISM_KEEP_AWAKE_CSO "0h";
BA_ "GenSigSendType" SG_ 963 VC_BU_VISM_KEEP_AWAKE_CSO 1;
BA_ "FlexKomSigStartValue" SG_ 963 VC_BU_VISM_KEEP_AWAKE_CSO "0300400000000000h";
BA_ "FlexKomSigStartPos" SG_ 963 VC_BU_VISM_KEEP_AWAKE_CSO 7;
BA_ "FlexKomSigName" SG_ 963 VC_BU_VISM_KEEP_AWAKE_CSO "VehCfgCSM3_BuPkt";
BA_ "FlexKomSigLaenge" SG_ 963 VC_BU_VISM_KEEP_AWAKE_CSO 64;
BA_ "FlexKomSID" SG_ 963 VC_BU_VISM_KEEP_AWAKE_CSO 2721;
BA_ "FlexKomIsMotorola" SG_ 963 VC_BU_VISM_KEEP_AWAKE_CSO 1;
BA_ "FlexKomComment" SG_ 963 VC_BU_VISM_KEEP_AWAKE_CSO "Backup for veh config - customer settings menu 3 p";
BA_ "GenSigSNA" SG_ 963 VC_BU_CHMSL_DYN_CNTR_CSO "0h";
BA_ "GenSigSendType" SG_ 963 VC_BU_CHMSL_DYN_CNTR_CSO 1;
BA_ "FlexKomSigStartValue" SG_ 963 VC_BU_CHMSL_DYN_CNTR_CSO "0300400000000000h";
BA_ "FlexKomSigStartPos" SG_ 963 VC_BU_CHMSL_DYN_CNTR_CSO 7;
BA_ "FlexKomSigName" SG_ 963 VC_BU_CHMSL_DYN_CNTR_CSO "VehCfgCSM3_BuPkt";
BA_ "FlexKomSigLaenge" SG_ 963 VC_BU_CHMSL_DYN_CNTR_CSO 64;
BA_ "FlexKomSID" SG_ 963 VC_BU_CHMSL_DYN_CNTR_CSO 2721;
BA_ "FlexKomIsMotorola" SG_ 963 VC_BU_CHMSL_DYN_CNTR_CSO 1;
BA_ "FlexKomComment" SG_ 963 VC_BU_CHMSL_DYN_CNTR_CSO "Backup for veh config - customer settings menu 3 p";
BA_ "GenSigSNA" SG_ 963 VC_BU_FT_PK_LOOSE_SHIP_CSO "0h";
BA_ "GenSigSendType" SG_ 963 VC_BU_FT_PK_LOOSE_SHIP_CSO 1;
BA_ "FlexKomSigStartValue" SG_ 963 VC_BU_FT_PK_LOOSE_SHIP_CSO "0300400000000000h";
BA_ "FlexKomSigStartPos" SG_ 963 VC_BU_FT_PK_LOOSE_SHIP_CSO 7;
BA_ "FlexKomSigName" SG_ 963 VC_BU_FT_PK_LOOSE_SHIP_CSO "VehCfgCSM3_BuPkt";
BA_ "FlexKomSigLaenge" SG_ 963 VC_BU_FT_PK_LOOSE_SHIP_CSO 64;
BA_ "FlexKomSID" SG_ 963 VC_BU_FT_PK_LOOSE_SHIP_CSO 2721;
BA_ "FlexKomIsMotorola" SG_ 963 VC_BU_FT_PK_LOOSE_SHIP_CSO 1;
BA_ "FlexKomComment" SG_ 963 VC_BU_FT_PK_LOOSE_SHIP_CSO "Backup for veh config - customer settings menu 3 p";
BA_ "GenSigSNA" SG_ 963 VC_BU_RR_PK_LOOSE_SHIP_CSO "0h";
BA_ "GenSigSendType" SG_ 963 VC_BU_RR_PK_LOOSE_SHIP_CSO 1;
BA_ "FlexKomSigStartValue" SG_ 963 VC_BU_RR_PK_LOOSE_SHIP_CSO "0300400000000000h";
BA_ "FlexKomSigStartPos" SG_ 963 VC_BU_RR_PK_LOOSE_SHIP_CSO 7;
BA_ "FlexKomSigName" SG_ 963 VC_BU_RR_PK_LOOSE_SHIP_CSO "VehCfgCSM3_BuPkt";
BA_ "FlexKomSigLaenge" SG_ 963 VC_BU_RR_PK_LOOSE_SHIP_CSO 64;
BA_ "FlexKomSID" SG_ 963 VC_BU_RR_PK_LOOSE_SHIP_CSO 2721;
BA_ "FlexKomIsMotorola" SG_ 963 VC_BU_RR_PK_LOOSE_SHIP_CSO 1;
BA_ "FlexKomComment" SG_ 963 VC_BU_RR_PK_LOOSE_SHIP_CSO "Backup for veh config - customer settings menu 3 p";
BA_ "GenSigSNA" SG_ 963 VC_BU_ESAVE_CSO "0h";
BA_ "GenSigSendType" SG_ 963 VC_BU_ESAVE_CSO 1;
BA_ "FlexKomSigStartValue" SG_ 963 VC_BU_ESAVE_CSO "0300400000000000h";
BA_ "FlexKomSigStartPos" SG_ 963 VC_BU_ESAVE_CSO 7;
BA_ "FlexKomSigName" SG_ 963 VC_BU_ESAVE_CSO "VehCfgCSM3_BuPkt";
BA_ "FlexKomSigLaenge" SG_ 963 VC_BU_ESAVE_CSO 64;
BA_ "FlexKomSID" SG_ 963 VC_BU_ESAVE_CSO 2721;
BA_ "FlexKomIsMotorola" SG_ 963 VC_BU_ESAVE_CSO 1;
BA_ "FlexKomComment" SG_ 963 VC_BU_ESAVE_CSO "Backup E-Save Enable/Disable customer settings menu";
BA_ "GenSigSNA" SG_ 963 VC_BU_ESAVE_BATT_LVL_CSO "0h";
BA_ "GenSigSendType" SG_ 963 VC_BU_ESAVE_BATT_LVL_CSO 1;
BA_ "FlexKomSigStartValue" SG_ 963 VC_BU_ESAVE_BATT_LVL_CSO "0300400000000000h";
BA_ "FlexKomSigStartPos" SG_ 963 VC_BU_ESAVE_BATT_LVL_CSO 7;
BA_ "FlexKomSigName" SG_ 963 VC_BU_ESAVE_BATT_LVL_CSO "VehCfgCSM3_BuPkt";
BA_ "FlexKomSigLaenge" SG_ 963 VC_BU_ESAVE_BATT_LVL_CSO 64;
BA_ "FlexKomSID" SG_ 963 VC_BU_ESAVE_BATT_LVL_CSO 2721;
BA_ "FlexKomIsMotorola" SG_ 963 VC_BU_ESAVE_BATT_LVL_CSO 1;
BA_ "FlexKomComment" SG_ 963 VC_BU_ESAVE_BATT_LVL_CSO "Backup E-Save Battery Level customer settings menu";
BA_ "GenSigStartValue" SG_ 963 VC_BU_VehCfgCSO3_Stat 3;
BA_ "GenSigSNA" SG_ 963 VC_BU_VehCfgCSO3_Stat "3h";
BA_ "GenSigSendType" SG_ 963 VC_BU_VehCfgCSO3_Stat 1;
BA_ "FlexKomSigStartValue" SG_ 963 VC_BU_VehCfgCSO3_Stat "0300400000000000h";
BA_ "FlexKomSigStartPos" SG_ 963 VC_BU_VehCfgCSO3_Stat 7;
BA_ "FlexKomSigName" SG_ 963 VC_BU_VehCfgCSO3_Stat "VehCfgCSM3_BuPkt";
BA_ "FlexKomSigLaenge" SG_ 963 VC_BU_VehCfgCSO3_Stat 64;
BA_ "FlexKomSID" SG_ 963 VC_BU_VehCfgCSO3_Stat 2721;
BA_ "FlexKomIsMotorola" SG_ 963 VC_BU_VehCfgCSO3_Stat 1;
BA_ "FlexKomComment" SG_ 963 VC_BU_VehCfgCSO3_Stat "Backup for veh config - customer settings menu 3 p";
BA_ "GenSigSNA" SG_ 963 VC_BU_FFC_GRIDLINES_CSO "0h";
BA_ "GenSigSendType" SG_ 963 VC_BU_FFC_GRIDLINES_CSO 1;
BA_ "FlexKomSigStartValue" SG_ 963 VC_BU_FFC_GRIDLINES_CSO "0300400000000000h";
BA_ "FlexKomSigStartPos" SG_ 963 VC_BU_FFC_GRIDLINES_CSO 7;
BA_ "FlexKomSigName" SG_ 963 VC_BU_FFC_GRIDLINES_CSO "VehCfgCSM3_BuPkt";
BA_ "FlexKomSigLaenge" SG_ 963 VC_BU_FFC_GRIDLINES_CSO 64;
BA_ "FlexKomSID" SG_ 963 VC_BU_FFC_GRIDLINES_CSO 2721;
BA_ "FlexKomIsMotorola" SG_ 963 VC_BU_FFC_GRIDLINES_CSO 1;
BA_ "FlexKomComment" SG_ 963 VC_BU_FFC_GRIDLINES_CSO "Backup for veh config - customer settings menu 3 p";
BA_ "GenSigSNA" SG_ 963 VC_BU_RVC_CVPM_DGRID_CSO "0h";
BA_ "GenSigSendType" SG_ 963 VC_BU_RVC_CVPM_DGRID_CSO 1;
BA_ "FlexKomSigStartValue" SG_ 963 VC_BU_RVC_CVPM_DGRID_CSO "0300400000000000h";
BA_ "FlexKomSigStartPos" SG_ 963 VC_BU_RVC_CVPM_DGRID_CSO 7;
BA_ "FlexKomSigName" SG_ 963 VC_BU_RVC_CVPM_DGRID_CSO "VehCfgCSM3_BuPkt";
BA_ "FlexKomSigLaenge" SG_ 963 VC_BU_RVC_CVPM_DGRID_CSO 64;
BA_ "FlexKomSID" SG_ 963 VC_BU_RVC_CVPM_DGRID_CSO 2721;
BA_ "FlexKomIsMotorola" SG_ 963 VC_BU_RVC_CVPM_DGRID_CSO 1;
BA_ "FlexKomComment" SG_ 963 VC_BU_RVC_CVPM_DGRID_CSO "Backup for veh config - customer settings menu 3 p";
BA_ "GenSigSNA" SG_ 963 VC_BU_RVC_CVPM_SGRID_CSO "0h";
BA_ "GenSigSendType" SG_ 963 VC_BU_RVC_CVPM_SGRID_CSO 1;
BA_ "FlexKomSigStartValue" SG_ 963 VC_BU_RVC_CVPM_SGRID_CSO "0300400000000000h";
BA_ "FlexKomSigStartPos" SG_ 963 VC_BU_RVC_CVPM_SGRID_CSO 7;
BA_ "FlexKomSigName" SG_ 963 VC_BU_RVC_CVPM_SGRID_CSO "VehCfgCSM3_BuPkt";
BA_ "FlexKomSigLaenge" SG_ 963 VC_BU_RVC_CVPM_SGRID_CSO 64;
BA_ "FlexKomSID" SG_ 963 VC_BU_RVC_CVPM_SGRID_CSO 2721;
BA_ "FlexKomIsMotorola" SG_ 963 VC_BU_RVC_CVPM_SGRID_CSO 1;
BA_ "FlexKomComment" SG_ 963 VC_BU_RVC_CVPM_SGRID_CSO "Backup for veh config - customer settings menu 3 p";
BA_ "GenSigSNA" SG_ 963 VC_BU_PEB_CSO "0h";
BA_ "GenSigSendType" SG_ 963 VC_BU_PEB_CSO 1;
BA_ "FlexKomSigStartValue" SG_ 963 VC_BU_PEB_CSO "0300400000000000h";
BA_ "FlexKomSigStartPos" SG_ 963 VC_BU_PEB_CSO 7;
BA_ "FlexKomSigName" SG_ 963 VC_BU_PEB_CSO "VehCfgCSM3_BuPkt";
BA_ "FlexKomSigLaenge" SG_ 963 VC_BU_PEB_CSO 64;
BA_ "FlexKomSID" SG_ 963 VC_BU_PEB_CSO 2721;
BA_ "FlexKomIsMotorola" SG_ 963 VC_BU_PEB_CSO 1;
BA_ "FlexKomComment" SG_ 963 VC_BU_PEB_CSO "Backup for veh config - customer settings menu 3 p";
BA_ "GenSigSNA" SG_ 963 VC_BU_AL_OR_PLUS_CSO "0h";
BA_ "GenSigSendType" SG_ 963 VC_BU_AL_OR_PLUS_CSO 1;
BA_ "FlexKomSigStartValue" SG_ 963 VC_BU_AL_OR_PLUS_CSO "0300400000000000h";
BA_ "FlexKomSigStartPos" SG_ 963 VC_BU_AL_OR_PLUS_CSO 7;
BA_ "FlexKomSigName" SG_ 963 VC_BU_AL_OR_PLUS_CSO "VehCfgCSM3_BuPkt";
BA_ "FlexKomSigLaenge" SG_ 963 VC_BU_AL_OR_PLUS_CSO 64;
BA_ "FlexKomSID" SG_ 963 VC_BU_AL_OR_PLUS_CSO 2721;
BA_ "FlexKomIsMotorola" SG_ 963 VC_BU_AL_OR_PLUS_CSO 1;
BA_ "FlexKomComment" SG_ 963 VC_BU_AL_OR_PLUS_CSO "Backup for veh config - customer settings menu 3 p";
BA_ "RID" SG_ 965 FusedSpeedLimit "6348";
BA_ "GenSigTimeout_IC" SG_ 965 FusedSpeedLimit 5250;
BA_ "GenSigSNA" SG_ 965 FusedSpeedLimit "0h";
BA_ "GenSigSendType" SG_ 965 FusedSpeedLimit 5;
BA_ "GenSigCycleTime" SG_ 965 FusedSpeedLimit 500;
BA_ "FlexKomSigStartValue" SG_ 965 FusedSpeedLimit "0000000000000000h";
BA_ "FlexKomSigStartPos" SG_ 965 FusedSpeedLimit 7;
BA_ "FlexKomSigName" SG_ 965 FusedSpeedLimit "CAM_MAP_FUSION_pkt";
BA_ "FlexKomSigLaenge" SG_ 965 FusedSpeedLimit 64;
BA_ "FlexKomSID" SG_ 965 FusedSpeedLimit 2704;
BA_ "FlexKomIsMotorola" SG_ 965 FusedSpeedLimit 1;
BA_ "FlexKomComment" SG_ 965 FusedSpeedLimit "CAM_MAP_FUSION_pkt";
BA_ "RID" SG_ 965 SupplementarySignSpeed "6349";
BA_ "GenSigTimeout_IC" SG_ 965 SupplementarySignSpeed 5250;
BA_ "GenSigSNA" SG_ 965 SupplementarySignSpeed "0h";
BA_ "GenSigSendType" SG_ 965 SupplementarySignSpeed 5;
BA_ "GenSigCycleTime" SG_ 965 SupplementarySignSpeed 500;
BA_ "FlexKomSigStartValue" SG_ 965 SupplementarySignSpeed "0000000000000000h";
BA_ "FlexKomSigStartPos" SG_ 965 SupplementarySignSpeed 7;
BA_ "FlexKomSigName" SG_ 965 SupplementarySignSpeed "CAM_MAP_FUSION_pkt";
BA_ "FlexKomSigLaenge" SG_ 965 SupplementarySignSpeed 64;
BA_ "FlexKomSID" SG_ 965 SupplementarySignSpeed 2704;
BA_ "FlexKomIsMotorola" SG_ 965 SupplementarySignSpeed 1;
BA_ "FlexKomComment" SG_ 965 SupplementarySignSpeed "CAM_MAP_FUSION_pkt";
BA_ "RID" SG_ 965 SourceFusedSpeedLimit "6346";
BA_ "GenSigSNA" SG_ 965 SourceFusedSpeedLimit "0h";
BA_ "GenSigSendType" SG_ 965 SourceFusedSpeedLimit 5;
BA_ "GenSigCycleTime" SG_ 965 SourceFusedSpeedLimit 500;
BA_ "FlexKomSigStartValue" SG_ 965 SourceFusedSpeedLimit "0000000000000000h";
BA_ "FlexKomSigStartPos" SG_ 965 SourceFusedSpeedLimit 7;
BA_ "FlexKomSigName" SG_ 965 SourceFusedSpeedLimit "CAM_MAP_FUSION_pkt";
BA_ "FlexKomSigLaenge" SG_ 965 SourceFusedSpeedLimit 64;
BA_ "FlexKomSID" SG_ 965 SourceFusedSpeedLimit 2704;
BA_ "FlexKomIsMotorola" SG_ 965 SourceFusedSpeedLimit 1;
BA_ "FlexKomComment" SG_ 965 SourceFusedSpeedLimit "CAM_MAP_FUSION_pkt";
BA_ "RID" SG_ 965 SpdUnits_CAM "6352";
BA_ "GenSigTimeout_IC" SG_ 965 SpdUnits_CAM 5250;
BA_ "GenSigSNA" SG_ 965 SpdUnits_CAM "0h";
BA_ "GenSigSendType" SG_ 965 SpdUnits_CAM 5;
BA_ "GenSigCycleTime" SG_ 965 SpdUnits_CAM 500;
BA_ "FlexKomSigStartValue" SG_ 965 SpdUnits_CAM "0000000000000000h";
BA_ "FlexKomSigStartPos" SG_ 965 SpdUnits_CAM 7;
BA_ "FlexKomSigName" SG_ 965 SpdUnits_CAM "CAM_MAP_FUSION_pkt";
BA_ "FlexKomSigLaenge" SG_ 965 SpdUnits_CAM 64;
BA_ "FlexKomSID" SG_ 965 SpdUnits_CAM 2704;
BA_ "FlexKomIsMotorola" SG_ 965 SpdUnits_CAM 1;
BA_ "FlexKomComment" SG_ 965 SpdUnits_CAM "CAM_MAP_FUSION_pkt";
BA_ "RID" SG_ 965 SupplementarySign "6359";
BA_ "GenSigTimeout_IC" SG_ 965 SupplementarySign 5250;
BA_ "GenSigSNA" SG_ 965 SupplementarySign "FFh";
BA_ "GenSigSendType" SG_ 965 SupplementarySign 5;
BA_ "GenSigCycleTime" SG_ 965 SupplementarySign 500;
BA_ "FlexKomSigStartValue" SG_ 965 SupplementarySign "0000000000000000h";
BA_ "FlexKomSigStartPos" SG_ 965 SupplementarySign 7;
BA_ "FlexKomSigName" SG_ 965 SupplementarySign "CAM_MAP_FUSION_pkt";
BA_ "FlexKomSigLaenge" SG_ 965 SupplementarySign 64;
BA_ "FlexKomSID" SG_ 965 SupplementarySign 2704;
BA_ "FlexKomIsMotorola" SG_ 965 SupplementarySign 1;
BA_ "FlexKomComment" SG_ 965 SupplementarySign "CAM_MAP_FUSION_pkt";
BA_ "RID" SG_ 965 OvertakingSign "6345";
BA_ "GenSigTimeout_IC" SG_ 965 OvertakingSign 5250;
BA_ "GenSigSNA" SG_ 965 OvertakingSign "Fh";
BA_ "GenSigSendType" SG_ 965 OvertakingSign 5;
BA_ "GenSigCycleTime" SG_ 965 OvertakingSign 500;
BA_ "FlexKomSigStartValue" SG_ 965 OvertakingSign "0000000000000000h";
BA_ "FlexKomSigStartPos" SG_ 965 OvertakingSign 7;
BA_ "FlexKomSigName" SG_ 965 OvertakingSign "CAM_MAP_FUSION_pkt";
BA_ "FlexKomSigLaenge" SG_ 965 OvertakingSign 64;
BA_ "FlexKomSID" SG_ 965 OvertakingSign 2704;
BA_ "FlexKomIsMotorola" SG_ 965 OvertakingSign 1;
BA_ "FlexKomComment" SG_ 965 OvertakingSign "CAM_MAP_FUSION_pkt";
BA_ "RID" SG_ 965 Speed_Sign_Shape "6344";
BA_ "GenSigTimeout_IC" SG_ 965 Speed_Sign_Shape 5250;
BA_ "GenSigSNA" SG_ 965 Speed_Sign_Shape "0h";
BA_ "GenSigSendType" SG_ 965 Speed_Sign_Shape 5;
BA_ "GenSigCycleTime" SG_ 965 Speed_Sign_Shape 500;
BA_ "FlexKomSigStartValue" SG_ 965 Speed_Sign_Shape "0000000000000000h";
BA_ "FlexKomSigStartPos" SG_ 965 Speed_Sign_Shape 7;
BA_ "FlexKomSigName" SG_ 965 Speed_Sign_Shape "CAM_MAP_FUSION_pkt";
BA_ "FlexKomSigLaenge" SG_ 965 Speed_Sign_Shape 64;
BA_ "FlexKomSID" SG_ 965 Speed_Sign_Shape 2704;
BA_ "FlexKomIsMotorola" SG_ 965 Speed_Sign_Shape 1;
BA_ "FlexKomComment" SG_ 965 Speed_Sign_Shape "CAM_MAP_FUSION_pkt";
BA_ "RID" SG_ 965 CAM_Fault_Status "6362";
BA_ "GenSigTimeout_IC" SG_ 965 CAM_Fault_Status 5250;
BA_ "GenSigSNA" SG_ 965 CAM_Fault_Status "0h";
BA_ "GenSigSendType" SG_ 965 CAM_Fault_Status 5;
BA_ "GenSigCycleTime" SG_ 965 CAM_Fault_Status 500;
BA_ "FlexKomSigStartValue" SG_ 965 CAM_Fault_Status "0000000000000000h";
BA_ "FlexKomSigStartPos" SG_ 965 CAM_Fault_Status 7;
BA_ "FlexKomSigName" SG_ 965 CAM_Fault_Status "CAM_MAP_FUSION_pkt";
BA_ "FlexKomSigLaenge" SG_ 965 CAM_Fault_Status 64;
BA_ "FlexKomSID" SG_ 965 CAM_Fault_Status 2704;
BA_ "FlexKomIsMotorola" SG_ 965 CAM_Fault_Status 1;
BA_ "FlexKomComment" SG_ 965 CAM_Fault_Status "CAM_MAP_FUSION_pkt";
BA_ "GenSigStartValue" SG_ 967 CRC_DPDM_A1 255;
BA_ "GenSigSNA" SG_ 967 CRC_DPDM_A1 "FFh";
BA_ "GenSigSendType" SG_ 967 CRC_DPDM_A1 5;
BA_ "GenSigCycleTime" SG_ 967 CRC_DPDM_A1 200;
BA_ "FlexKomSigStartValue" SG_ 967 CRC_DPDM_A1 "020000FFh";
BA_ "FlexKomSigStartPos" SG_ 967 CRC_DPDM_A1 7;
BA_ "FlexKomSigName" SG_ 967 CRC_DPDM_A1 "DPDM_A1_PKT";
BA_ "FlexKomSigLaenge" SG_ 967 CRC_DPDM_A1 32;
BA_ "FlexKomSID" SG_ 967 CRC_DPDM_A1 2682;
BA_ "FlexKomIsMotorola" SG_ 967 CRC_DPDM_A1 1;
BA_ "FlexKomComment" SG_ 967 CRC_DPDM_A1 "DPDM_A1_PKT";
BA_ "GenSigStartValue" SG_ 967 DrvSeatDPSts 2;
BA_ "GenSigSNA" SG_ 967 DrvSeatDPSts "3h";
BA_ "GenSigSendType" SG_ 967 DrvSeatDPSts 5;
BA_ "GenSigCycleTime" SG_ 967 DrvSeatDPSts 200;
BA_ "FlexKomSigStartValue" SG_ 967 DrvSeatDPSts "020000FFh";
BA_ "FlexKomSigStartPos" SG_ 967 DrvSeatDPSts 7;
BA_ "FlexKomSigName" SG_ 967 DrvSeatDPSts "DPDM_A1_PKT";
BA_ "FlexKomSigLaenge" SG_ 967 DrvSeatDPSts 32;
BA_ "FlexKomSID" SG_ 967 DrvSeatDPSts 2682;
BA_ "FlexKomIsMotorola" SG_ 967 DrvSeatDPSts 1;
BA_ "FlexKomComment" SG_ 967 DrvSeatDPSts "DPDM_A1_PKT";
BA_ "GenSigSNA" SG_ 967 DrvSeatDPFaultSts "0h";
BA_ "GenSigSendType" SG_ 967 DrvSeatDPFaultSts 5;
BA_ "GenSigCycleTime" SG_ 967 DrvSeatDPFaultSts 200;
BA_ "FlexKomSigStartValue" SG_ 967 DrvSeatDPFaultSts "020000FFh";
BA_ "FlexKomSigStartPos" SG_ 967 DrvSeatDPFaultSts 7;
BA_ "FlexKomSigName" SG_ 967 DrvSeatDPFaultSts "DPDM_A1_PKT";
BA_ "FlexKomSigLaenge" SG_ 967 DrvSeatDPFaultSts 32;
BA_ "FlexKomSID" SG_ 967 DrvSeatDPFaultSts 2682;
BA_ "FlexKomIsMotorola" SG_ 967 DrvSeatDPFaultSts 1;
BA_ "FlexKomComment" SG_ 967 DrvSeatDPFaultSts "DPDM_A1_PKT";
BA_ "GenSigSNA" SG_ 967 MC_DPDM_A1 "0h";
BA_ "GenSigSendType" SG_ 967 MC_DPDM_A1 5;
BA_ "GenSigCycleTime" SG_ 967 MC_DPDM_A1 200;
BA_ "FlexKomSigStartValue" SG_ 967 MC_DPDM_A1 "020000FFh";
BA_ "FlexKomSigStartPos" SG_ 967 MC_DPDM_A1 7;
BA_ "FlexKomSigName" SG_ 967 MC_DPDM_A1 "DPDM_A1_PKT";
BA_ "FlexKomSigLaenge" SG_ 967 MC_DPDM_A1 32;
BA_ "FlexKomSID" SG_ 967 MC_DPDM_A1 2682;
BA_ "FlexKomIsMotorola" SG_ 967 MC_DPDM_A1 1;
BA_ "FlexKomComment" SG_ 967 MC_DPDM_A1 "DPDM_A1_PKT";
BA_ "GenSigTimeout_IC" SG_ 969 AMB_TEMP_AVG_F 10500;
BA_ "GenSigStartValue" SG_ 969 AMB_TEMP_AVG_F 255;
BA_ "GenSigSNA" SG_ 969 AMB_TEMP_AVG_F "FFh";
BA_ "GenSigCycleTime" SG_ 969 AMB_TEMP_AVG_F 1000;
BA_ "FlexKomSigStartValue" SG_ 969 AMB_TEMP_AVG_F "FFh";
BA_ "FlexKomSigStartPos" SG_ 969 AMB_TEMP_AVG_F 7;
BA_ "FlexKomSigName" SG_ 969 AMB_TEMP_AVG_F "AMB_TEMP_AVG_F";
BA_ "FlexKomSigLaenge" SG_ 969 AMB_TEMP_AVG_F 8;
BA_ "FlexKomSID" SG_ 969 AMB_TEMP_AVG_F 1428;
BA_ "FlexKomIsMotorola" SG_ 969 AMB_TEMP_AVG_F 1;
BA_ "FlexKomComment" SG_ 969 AMB_TEMP_AVG_F "Ambient temperature average - in degrees Fahrenhei";
BA_ "GenSigTimeout_IC" SG_ 969 AMB_TEMP_AVG_C 10500;
BA_ "GenSigTimeout_DTCM" SG_ 969 AMB_TEMP_AVG_C 5500;
BA_ "GenSigStartValue" SG_ 969 AMB_TEMP_AVG_C 255;
BA_ "GenSigSNA" SG_ 969 AMB_TEMP_AVG_C "FFh";
BA_ "GenSigCycleTime" SG_ 969 AMB_TEMP_AVG_C 1000;
BA_ "FlexKomSigStartValue" SG_ 969 AMB_TEMP_AVG_C "FFh";
BA_ "FlexKomSigStartPos" SG_ 969 AMB_TEMP_AVG_C 15;
BA_ "FlexKomSigName" SG_ 969 AMB_TEMP_AVG_C "AMB_TEMP_AVG_C";
BA_ "FlexKomSigLaenge" SG_ 969 AMB_TEMP_AVG_C 8;
BA_ "FlexKomSID" SG_ 969 AMB_TEMP_AVG_C 1427;
BA_ "FlexKomIsMotorola" SG_ 969 AMB_TEMP_AVG_C 1;
BA_ "FlexKomComment" SG_ 969 AMB_TEMP_AVG_C "Ambient temperature average - in degrees Celsius";
BA_ "RID" SG_ 973 EPB_WARN_STAT "6325";
BA_ "GenSigTimeout_ETM" SG_ 973 EPB_WARN_STAT 21000;
BA_ "GenSigSNA" SG_ 973 EPB_WARN_STAT "3h";
BA_ "GenSigSendType" SG_ 973 EPB_WARN_STAT 5;
BA_ "GenSigCycleTime" SG_ 973 EPB_WARN_STAT 2000;
BA_ "FlexKomSigStartValue" SG_ 973 EPB_WARN_STAT "0000000000000000h";
BA_ "FlexKomSigStartPos" SG_ 973 EPB_WARN_STAT 7;
BA_ "FlexKomSigName" SG_ 973 EPB_WARN_STAT "IPC_LMPS_Pkt";
BA_ "FlexKomSigLaenge" SG_ 973 EPB_WARN_STAT 64;
BA_ "FlexKomSID" SG_ 973 EPB_WARN_STAT 2626;
BA_ "FlexKomIsMotorola" SG_ 973 EPB_WARN_STAT 1;
BA_ "FlexKomComment" SG_ 973 EPB_WARN_STAT "IPC_LMPS packet";
BA_ "RID" SG_ 973 CATALYST_TEMP_STAT "6317";
BA_ "GenSigSNA" SG_ 973 CATALYST_TEMP_STAT "3h";
BA_ "GenSigSendType" SG_ 973 CATALYST_TEMP_STAT 5;
BA_ "GenSigCycleTime" SG_ 973 CATALYST_TEMP_STAT 2000;
BA_ "FlexKomSigStartValue" SG_ 973 CATALYST_TEMP_STAT "0000000000000000h";
BA_ "FlexKomSigStartPos" SG_ 973 CATALYST_TEMP_STAT 7;
BA_ "FlexKomSigName" SG_ 973 CATALYST_TEMP_STAT "IPC_LMPS_Pkt";
BA_ "FlexKomSigLaenge" SG_ 973 CATALYST_TEMP_STAT 64;
BA_ "FlexKomSID" SG_ 973 CATALYST_TEMP_STAT 2626;
BA_ "FlexKomIsMotorola" SG_ 973 CATALYST_TEMP_STAT 1;
BA_ "FlexKomComment" SG_ 973 CATALYST_TEMP_STAT "IPC_LMPS packet";
BA_ "RID" SG_ 973 FUEL_CAP_STAT "6322";
BA_ "GenSigSNA" SG_ 973 FUEL_CAP_STAT "3h";
BA_ "GenSigSendType" SG_ 973 FUEL_CAP_STAT 5;
BA_ "GenSigCycleTime" SG_ 973 FUEL_CAP_STAT 2000;
BA_ "FlexKomSigStartValue" SG_ 973 FUEL_CAP_STAT "0000000000000000h";
BA_ "FlexKomSigStartPos" SG_ 973 FUEL_CAP_STAT 7;
BA_ "FlexKomSigName" SG_ 973 FUEL_CAP_STAT "IPC_LMPS_Pkt";
BA_ "FlexKomSigLaenge" SG_ 973 FUEL_CAP_STAT 64;
BA_ "FlexKomSID" SG_ 973 FUEL_CAP_STAT 2626;
BA_ "FlexKomIsMotorola" SG_ 973 FUEL_CAP_STAT 1;
BA_ "FlexKomComment" SG_ 973 FUEL_CAP_STAT "IPC_LMPS packet";
BA_ "RID" SG_ 973 WINDSHIELD_FLUID_STAT "6299";
BA_ "GenSigSNA" SG_ 973 WINDSHIELD_FLUID_STAT "3h";
BA_ "GenSigSendType" SG_ 973 WINDSHIELD_FLUID_STAT 5;
BA_ "GenSigCycleTime" SG_ 973 WINDSHIELD_FLUID_STAT 2000;
BA_ "FlexKomSigStartValue" SG_ 973 WINDSHIELD_FLUID_STAT "0000000000000000h";
BA_ "FlexKomSigStartPos" SG_ 973 WINDSHIELD_FLUID_STAT 7;
BA_ "FlexKomSigName" SG_ 973 WINDSHIELD_FLUID_STAT "IPC_LMPS_Pkt";
BA_ "FlexKomSigLaenge" SG_ 973 WINDSHIELD_FLUID_STAT 64;
BA_ "FlexKomSID" SG_ 973 WINDSHIELD_FLUID_STAT 2626;
BA_ "FlexKomIsMotorola" SG_ 973 WINDSHIELD_FLUID_STAT 1;
BA_ "FlexKomComment" SG_ 973 WINDSHIELD_FLUID_STAT "IPC_LMPS packet";
BA_ "RID" SG_ 973 COOLENT_LEVEL_STAT "6302";
BA_ "GenSigSNA" SG_ 973 COOLENT_LEVEL_STAT "3h";
BA_ "GenSigSendType" SG_ 973 COOLENT_LEVEL_STAT 5;
BA_ "GenSigCycleTime" SG_ 973 COOLENT_LEVEL_STAT 2000;
BA_ "FlexKomSigStartValue" SG_ 973 COOLENT_LEVEL_STAT "0000000000000000h";
BA_ "FlexKomSigStartPos" SG_ 973 COOLENT_LEVEL_STAT 7;
BA_ "FlexKomSigName" SG_ 973 COOLENT_LEVEL_STAT "IPC_LMPS_Pkt";
BA_ "FlexKomSigLaenge" SG_ 973 COOLENT_LEVEL_STAT 64;
BA_ "FlexKomSID" SG_ 973 COOLENT_LEVEL_STAT 2626;
BA_ "FlexKomIsMotorola" SG_ 973 COOLENT_LEVEL_STAT 1;
BA_ "FlexKomComment" SG_ 973 COOLENT_LEVEL_STAT "IPC_LMPS packet";
BA_ "RID" SG_ 973 OIL_LEVEL_STAT "6307";
BA_ "GenSigSNA" SG_ 973 OIL_LEVEL_STAT "3h";
BA_ "GenSigSendType" SG_ 973 OIL_LEVEL_STAT 5;
BA_ "GenSigCycleTime" SG_ 973 OIL_LEVEL_STAT 2000;
BA_ "FlexKomSigStartValue" SG_ 973 OIL_LEVEL_STAT "0000000000000000h";
BA_ "FlexKomSigStartPos" SG_ 973 OIL_LEVEL_STAT 7;
BA_ "FlexKomSigName" SG_ 973 OIL_LEVEL_STAT "IPC_LMPS_Pkt";
BA_ "FlexKomSigLaenge" SG_ 973 OIL_LEVEL_STAT 64;
BA_ "FlexKomSID" SG_ 973 OIL_LEVEL_STAT 2626;
BA_ "FlexKomIsMotorola" SG_ 973 OIL_LEVEL_STAT 1;
BA_ "FlexKomComment" SG_ 973 OIL_LEVEL_STAT "IPC_LMPS packet";
BA_ "RID" SG_ 973 ELECTRIC_WRENCH_STAT "6324";
BA_ "GenSigSNA" SG_ 973 ELECTRIC_WRENCH_STAT "3h";
BA_ "GenSigSendType" SG_ 973 ELECTRIC_WRENCH_STAT 5;
BA_ "GenSigCycleTime" SG_ 973 ELECTRIC_WRENCH_STAT 2000;
BA_ "FlexKomSigStartValue" SG_ 973 ELECTRIC_WRENCH_STAT "0000000000000000h";
BA_ "FlexKomSigStartPos" SG_ 973 ELECTRIC_WRENCH_STAT 7;
BA_ "FlexKomSigName" SG_ 973 ELECTRIC_WRENCH_STAT "IPC_LMPS_Pkt";
BA_ "FlexKomSigLaenge" SG_ 973 ELECTRIC_WRENCH_STAT 64;
BA_ "FlexKomSID" SG_ 973 ELECTRIC_WRENCH_STAT 2626;
BA_ "FlexKomIsMotorola" SG_ 973 ELECTRIC_WRENCH_STAT 1;
BA_ "FlexKomComment" SG_ 973 ELECTRIC_WRENCH_STAT "IPC_LMPS packet";
BA_ "RID" SG_ 973 ENGINE_TEMP_STAT "6312";
BA_ "GenSigTimeout_ETM" SG_ 973 ENGINE_TEMP_STAT 21000;
BA_ "GenSigSNA" SG_ 973 ENGINE_TEMP_STAT "3h";
BA_ "GenSigSendType" SG_ 973 ENGINE_TEMP_STAT 5;
BA_ "GenSigCycleTime" SG_ 973 ENGINE_TEMP_STAT 2000;
BA_ "FlexKomSigStartValue" SG_ 973 ENGINE_TEMP_STAT "0000000000000000h";
BA_ "FlexKomSigStartPos" SG_ 973 ENGINE_TEMP_STAT 7;
BA_ "FlexKomSigName" SG_ 973 ENGINE_TEMP_STAT "IPC_LMPS_Pkt";
BA_ "FlexKomSigLaenge" SG_ 973 ENGINE_TEMP_STAT 64;
BA_ "FlexKomSID" SG_ 973 ENGINE_TEMP_STAT 2626;
BA_ "FlexKomIsMotorola" SG_ 973 ENGINE_TEMP_STAT 1;
BA_ "FlexKomComment" SG_ 973 ENGINE_TEMP_STAT "IPC_LMPS packet";
BA_ "RID" SG_ 973 BATTERY_CHARGE_STAT "6327";
BA_ "GenSigTimeout_ETM" SG_ 973 BATTERY_CHARGE_STAT 21000;
BA_ "GenSigSNA" SG_ 973 BATTERY_CHARGE_STAT "3h";
BA_ "GenSigSendType" SG_ 973 BATTERY_CHARGE_STAT 5;
BA_ "GenSigCycleTime" SG_ 973 BATTERY_CHARGE_STAT 2000;
BA_ "FlexKomSigStartValue" SG_ 973 BATTERY_CHARGE_STAT "0000000000000000h";
BA_ "FlexKomSigStartPos" SG_ 973 BATTERY_CHARGE_STAT 7;
BA_ "FlexKomSigName" SG_ 973 BATTERY_CHARGE_STAT "IPC_LMPS_Pkt";
BA_ "FlexKomSigLaenge" SG_ 973 BATTERY_CHARGE_STAT 64;
BA_ "FlexKomSID" SG_ 973 BATTERY_CHARGE_STAT 2626;
BA_ "FlexKomIsMotorola" SG_ 973 BATTERY_CHARGE_STAT 1;
BA_ "FlexKomComment" SG_ 973 BATTERY_CHARGE_STAT "IPC_LMPS packet";
BA_ "RID" SG_ 973 OIL_PRESSURE_STAT "6316";
BA_ "GenSigTimeout_ETM" SG_ 973 OIL_PRESSURE_STAT 21000;
BA_ "GenSigSNA" SG_ 973 OIL_PRESSURE_STAT "3h";
BA_ "GenSigSendType" SG_ 973 OIL_PRESSURE_STAT 5;
BA_ "GenSigCycleTime" SG_ 973 OIL_PRESSURE_STAT 2000;
BA_ "FlexKomSigStartValue" SG_ 973 OIL_PRESSURE_STAT "0000000000000000h";
BA_ "FlexKomSigStartPos" SG_ 973 OIL_PRESSURE_STAT 7;
BA_ "FlexKomSigName" SG_ 973 OIL_PRESSURE_STAT "IPC_LMPS_Pkt";
BA_ "FlexKomSigLaenge" SG_ 973 OIL_PRESSURE_STAT 64;
BA_ "FlexKomSID" SG_ 973 OIL_PRESSURE_STAT 2626;
BA_ "FlexKomIsMotorola" SG_ 973 OIL_PRESSURE_STAT 1;
BA_ "FlexKomComment" SG_ 973 OIL_PRESSURE_STAT "IPC_LMPS packet";
BA_ "RID" SG_ 973 BRK_IND_STAT "6305";
BA_ "GenSigTimeout_ETM" SG_ 973 BRK_IND_STAT 21000;
BA_ "GenSigSNA" SG_ 973 BRK_IND_STAT "3h";
BA_ "GenSigSendType" SG_ 973 BRK_IND_STAT 5;
BA_ "GenSigCycleTime" SG_ 973 BRK_IND_STAT 2000;
BA_ "FlexKomSigStartValue" SG_ 973 BRK_IND_STAT "0000000000000000h";
BA_ "FlexKomSigStartPos" SG_ 973 BRK_IND_STAT 7;
BA_ "FlexKomSigName" SG_ 973 BRK_IND_STAT "IPC_LMPS_Pkt";
BA_ "FlexKomSigLaenge" SG_ 973 BRK_IND_STAT 64;
BA_ "FlexKomSID" SG_ 973 BRK_IND_STAT 2626;
BA_ "FlexKomIsMotorola" SG_ 973 BRK_IND_STAT 1;
BA_ "FlexKomComment" SG_ 973 BRK_IND_STAT "IPC_LMPS packet";
BA_ "RID" SG_ 973 ABS_IND_STAT "6301";
BA_ "GenSigTimeout_ETM" SG_ 973 ABS_IND_STAT 21000;
BA_ "GenSigSNA" SG_ 973 ABS_IND_STAT "3h";
BA_ "GenSigSendType" SG_ 973 ABS_IND_STAT 5;
BA_ "GenSigCycleTime" SG_ 973 ABS_IND_STAT 2000;
BA_ "FlexKomSigStartValue" SG_ 973 ABS_IND_STAT "0000000000000000h";
BA_ "FlexKomSigStartPos" SG_ 973 ABS_IND_STAT 7;
BA_ "FlexKomSigName" SG_ 973 ABS_IND_STAT "IPC_LMPS_Pkt";
BA_ "FlexKomSigLaenge" SG_ 973 ABS_IND_STAT 64;
BA_ "FlexKomSID" SG_ 973 ABS_IND_STAT 2626;
BA_ "FlexKomIsMotorola" SG_ 973 ABS_IND_STAT 1;
BA_ "FlexKomComment" SG_ 973 ABS_IND_STAT "IPC_LMPS packet";
BA_ "RID" SG_ 973 ENGINE_MIL_STAT "6306";
BA_ "GenSigTimeout_ETM" SG_ 973 ENGINE_MIL_STAT 21000;
BA_ "GenSigSNA" SG_ 973 ENGINE_MIL_STAT "3h";
BA_ "GenSigSendType" SG_ 973 ENGINE_MIL_STAT 5;
BA_ "GenSigCycleTime" SG_ 973 ENGINE_MIL_STAT 2000;
BA_ "FlexKomSigStartValue" SG_ 973 ENGINE_MIL_STAT "0000000000000000h";
BA_ "FlexKomSigStartPos" SG_ 973 ENGINE_MIL_STAT 7;
BA_ "FlexKomSigName" SG_ 973 ENGINE_MIL_STAT "IPC_LMPS_Pkt";
BA_ "FlexKomSigLaenge" SG_ 973 ENGINE_MIL_STAT 64;
BA_ "FlexKomSID" SG_ 973 ENGINE_MIL_STAT 2626;
BA_ "FlexKomIsMotorola" SG_ 973 ENGINE_MIL_STAT 1;
BA_ "FlexKomComment" SG_ 973 ENGINE_MIL_STAT "IPC_LMPS packet";
BA_ "RID" SG_ 973 TIRE_PRESSURE_STAT "6313";
BA_ "GenSigTimeout_ETM" SG_ 973 TIRE_PRESSURE_STAT 21000;
BA_ "GenSigSNA" SG_ 973 TIRE_PRESSURE_STAT "3h";
BA_ "GenSigSendType" SG_ 973 TIRE_PRESSURE_STAT 5;
BA_ "GenSigCycleTime" SG_ 973 TIRE_PRESSURE_STAT 2000;
BA_ "FlexKomSigStartValue" SG_ 973 TIRE_PRESSURE_STAT "0000000000000000h";
BA_ "FlexKomSigStartPos" SG_ 973 TIRE_PRESSURE_STAT 7;
BA_ "FlexKomSigName" SG_ 973 TIRE_PRESSURE_STAT "IPC_LMPS_Pkt";
BA_ "FlexKomSigLaenge" SG_ 973 TIRE_PRESSURE_STAT 64;
BA_ "FlexKomSID" SG_ 973 TIRE_PRESSURE_STAT 2626;
BA_ "FlexKomIsMotorola" SG_ 973 TIRE_PRESSURE_STAT 1;
BA_ "FlexKomComment" SG_ 973 TIRE_PRESSURE_STAT "IPC_LMPS packet";
BA_ "RID" SG_ 973 ETC_CONTROL_STAT "6311";
BA_ "GenSigTimeout_ETM" SG_ 973 ETC_CONTROL_STAT 21000;
BA_ "GenSigSNA" SG_ 973 ETC_CONTROL_STAT "3h";
BA_ "GenSigSendType" SG_ 973 ETC_CONTROL_STAT 5;
BA_ "GenSigCycleTime" SG_ 973 ETC_CONTROL_STAT 2000;
BA_ "FlexKomSigStartValue" SG_ 973 ETC_CONTROL_STAT "0000000000000000h";
BA_ "FlexKomSigStartPos" SG_ 973 ETC_CONTROL_STAT 7;
BA_ "FlexKomSigName" SG_ 973 ETC_CONTROL_STAT "IPC_LMPS_Pkt";
BA_ "FlexKomSigLaenge" SG_ 973 ETC_CONTROL_STAT 64;
BA_ "FlexKomSID" SG_ 973 ETC_CONTROL_STAT 2626;
BA_ "FlexKomIsMotorola" SG_ 973 ETC_CONTROL_STAT 1;
BA_ "FlexKomComment" SG_ 973 ETC_CONTROL_STAT "IPC_LMPS packet";
BA_ "RID" SG_ 973 ELEC_STAB_STAT "6308";
BA_ "GenSigTimeout_ETM" SG_ 973 ELEC_STAB_STAT 21000;
BA_ "GenSigSNA" SG_ 973 ELEC_STAB_STAT "3h";
BA_ "GenSigSendType" SG_ 973 ELEC_STAB_STAT 5;
BA_ "GenSigCycleTime" SG_ 973 ELEC_STAB_STAT 2000;
BA_ "FlexKomSigStartValue" SG_ 973 ELEC_STAB_STAT "0000000000000000h";
BA_ "FlexKomSigStartPos" SG_ 973 ELEC_STAB_STAT 7;
BA_ "FlexKomSigName" SG_ 973 ELEC_STAB_STAT "IPC_LMPS_Pkt";
BA_ "FlexKomSigLaenge" SG_ 973 ELEC_STAB_STAT 64;
BA_ "FlexKomSID" SG_ 973 ELEC_STAB_STAT 2626;
BA_ "FlexKomIsMotorola" SG_ 973 ELEC_STAB_STAT 1;
BA_ "FlexKomComment" SG_ 973 ELEC_STAB_STAT "IPC_LMPS packet";
BA_ "RID" SG_ 973 OVER_TEMP_STAT "6318";
BA_ "GenSigTimeout_ETM" SG_ 973 OVER_TEMP_STAT 21000;
BA_ "GenSigSNA" SG_ 973 OVER_TEMP_STAT "3h";
BA_ "GenSigSendType" SG_ 973 OVER_TEMP_STAT 5;
BA_ "GenSigCycleTime" SG_ 973 OVER_TEMP_STAT 2000;
BA_ "FlexKomSigStartValue" SG_ 973 OVER_TEMP_STAT "0000000000000000h";
BA_ "FlexKomSigStartPos" SG_ 973 OVER_TEMP_STAT 7;
BA_ "FlexKomSigName" SG_ 973 OVER_TEMP_STAT "IPC_LMPS_Pkt";
BA_ "FlexKomSigLaenge" SG_ 973 OVER_TEMP_STAT 64;
BA_ "FlexKomSID" SG_ 973 OVER_TEMP_STAT 2626;
BA_ "FlexKomIsMotorola" SG_ 973 OVER_TEMP_STAT 1;
BA_ "FlexKomComment" SG_ 973 OVER_TEMP_STAT "IPC_LMPS packet";
BA_ "RID" SG_ 973 STOP_START_STAT "6315";
BA_ "GenSigTimeout_ETM" SG_ 973 STOP_START_STAT 21000;
BA_ "GenSigSNA" SG_ 973 STOP_START_STAT "3h";
BA_ "GenSigSendType" SG_ 973 STOP_START_STAT 5;
BA_ "GenSigCycleTime" SG_ 973 STOP_START_STAT 2000;
BA_ "FlexKomSigStartValue" SG_ 973 STOP_START_STAT "0000000000000000h";
BA_ "FlexKomSigStartPos" SG_ 973 STOP_START_STAT 7;
BA_ "FlexKomSigName" SG_ 973 STOP_START_STAT "IPC_LMPS_Pkt";
BA_ "FlexKomSigLaenge" SG_ 973 STOP_START_STAT 64;
BA_ "FlexKomSID" SG_ 973 STOP_START_STAT 2626;
BA_ "FlexKomIsMotorola" SG_ 973 STOP_START_STAT 1;
BA_ "FlexKomComment" SG_ 973 STOP_START_STAT "IPC_LMPS packet";
BA_ "RID" SG_ 973 EPS_STAT "6310";
BA_ "GenSigTimeout_ETM" SG_ 973 EPS_STAT 21000;
BA_ "GenSigSNA" SG_ 973 EPS_STAT "3h";
BA_ "GenSigSendType" SG_ 973 EPS_STAT 5;
BA_ "GenSigCycleTime" SG_ 973 EPS_STAT 2000;
BA_ "FlexKomSigStartValue" SG_ 973 EPS_STAT "0000000000000000h";
BA_ "FlexKomSigStartPos" SG_ 973 EPS_STAT 7;
BA_ "FlexKomSigName" SG_ 973 EPS_STAT "IPC_LMPS_Pkt";
BA_ "FlexKomSigLaenge" SG_ 973 EPS_STAT 64;
BA_ "FlexKomSID" SG_ 973 EPS_STAT 2626;
BA_ "FlexKomIsMotorola" SG_ 973 EPS_STAT 1;
BA_ "FlexKomComment" SG_ 973 EPS_STAT "IPC_LMPS packet";
BA_ "RID" SG_ 973 FCW_SYSTEM_STAT "6304";
BA_ "GenSigTimeout_ETM" SG_ 973 FCW_SYSTEM_STAT 21000;
BA_ "GenSigSNA" SG_ 973 FCW_SYSTEM_STAT "3h";
BA_ "GenSigSendType" SG_ 973 FCW_SYSTEM_STAT 5;
BA_ "GenSigCycleTime" SG_ 973 FCW_SYSTEM_STAT 2000;
BA_ "FlexKomSigStartValue" SG_ 973 FCW_SYSTEM_STAT "0000000000000000h";
BA_ "FlexKomSigStartPos" SG_ 973 FCW_SYSTEM_STAT 7;
BA_ "FlexKomSigName" SG_ 973 FCW_SYSTEM_STAT "IPC_LMPS_Pkt";
BA_ "FlexKomSigLaenge" SG_ 973 FCW_SYSTEM_STAT 64;
BA_ "FlexKomSID" SG_ 973 FCW_SYSTEM_STAT 2626;
BA_ "FlexKomIsMotorola" SG_ 973 FCW_SYSTEM_STAT 1;
BA_ "FlexKomComment" SG_ 973 FCW_SYSTEM_STAT "IPC_LMPS packet";
BA_ "RID" SG_ 973 SERVICE_ACC_STAT "6297";
BA_ "GenSigTimeout_ETM" SG_ 973 SERVICE_ACC_STAT 21000;
BA_ "GenSigSNA" SG_ 973 SERVICE_ACC_STAT "3h";
BA_ "GenSigSendType" SG_ 973 SERVICE_ACC_STAT 5;
BA_ "GenSigCycleTime" SG_ 973 SERVICE_ACC_STAT 2000;
BA_ "FlexKomSigStartValue" SG_ 973 SERVICE_ACC_STAT "0000000000000000h";
BA_ "FlexKomSigStartPos" SG_ 973 SERVICE_ACC_STAT 7;
BA_ "FlexKomSigName" SG_ 973 SERVICE_ACC_STAT "IPC_LMPS_Pkt";
BA_ "FlexKomSigLaenge" SG_ 973 SERVICE_ACC_STAT 64;
BA_ "FlexKomSID" SG_ 973 SERVICE_ACC_STAT 2626;
BA_ "FlexKomIsMotorola" SG_ 973 SERVICE_ACC_STAT 1;
BA_ "FlexKomComment" SG_ 973 SERVICE_ACC_STAT "IPC_LMPS packet";
BA_ "RID" SG_ 973 WATER_IN_FUEL_STAT "6309";
BA_ "GenSigTimeout_ETM" SG_ 973 WATER_IN_FUEL_STAT 21000;
BA_ "GenSigSNA" SG_ 973 WATER_IN_FUEL_STAT "3h";
BA_ "GenSigSendType" SG_ 973 WATER_IN_FUEL_STAT 5;
BA_ "GenSigCycleTime" SG_ 973 WATER_IN_FUEL_STAT 2000;
BA_ "FlexKomSigStartValue" SG_ 973 WATER_IN_FUEL_STAT "0000000000000000h";
BA_ "FlexKomSigStartPos" SG_ 973 WATER_IN_FUEL_STAT 7;
BA_ "FlexKomSigName" SG_ 973 WATER_IN_FUEL_STAT "IPC_LMPS_Pkt";
BA_ "FlexKomSigLaenge" SG_ 973 WATER_IN_FUEL_STAT 64;
BA_ "FlexKomSID" SG_ 973 WATER_IN_FUEL_STAT 2626;
BA_ "FlexKomIsMotorola" SG_ 973 WATER_IN_FUEL_STAT 1;
BA_ "FlexKomComment" SG_ 973 WATER_IN_FUEL_STAT "IPC_LMPS packet";
BA_ "RID" SG_ 973 TORQUE_STAT "6320";
BA_ "GenSigSNA" SG_ 973 TORQUE_STAT "3h";
BA_ "GenSigSendType" SG_ 973 TORQUE_STAT 5;
BA_ "GenSigCycleTime" SG_ 973 TORQUE_STAT 2000;
BA_ "FlexKomSigStartValue" SG_ 973 TORQUE_STAT "0000000000000000h";
BA_ "FlexKomSigStartPos" SG_ 973 TORQUE_STAT 7;
BA_ "FlexKomSigName" SG_ 973 TORQUE_STAT "IPC_LMPS_Pkt";
BA_ "FlexKomSigLaenge" SG_ 973 TORQUE_STAT 64;
BA_ "FlexKomSID" SG_ 973 TORQUE_STAT 2626;
BA_ "FlexKomIsMotorola" SG_ 973 TORQUE_STAT 1;
BA_ "FlexKomComment" SG_ 973 TORQUE_STAT "IPC_LMPS packet";
BA_ "RID" SG_ 973 DEF_STAT "6298";
BA_ "GenSigTimeout_ETM" SG_ 973 DEF_STAT 21000;
BA_ "GenSigSNA" SG_ 973 DEF_STAT "3h";
BA_ "GenSigSendType" SG_ 973 DEF_STAT 5;
BA_ "GenSigCycleTime" SG_ 973 DEF_STAT 2000;
BA_ "FlexKomSigStartValue" SG_ 973 DEF_STAT "0000000000000000h";
BA_ "FlexKomSigStartPos" SG_ 973 DEF_STAT 7;
BA_ "FlexKomSigName" SG_ 973 DEF_STAT "IPC_LMPS_Pkt";
BA_ "FlexKomSigLaenge" SG_ 973 DEF_STAT 64;
BA_ "FlexKomSID" SG_ 973 DEF_STAT 2626;
BA_ "FlexKomIsMotorola" SG_ 973 DEF_STAT 1;
BA_ "FlexKomComment" SG_ 973 DEF_STAT "IPC_LMPS packet";
BA_ "RID" SG_ 973 OIL_TEMP_STAT "6300";
BA_ "GenSigTimeout_ETM" SG_ 973 OIL_TEMP_STAT 21000;
BA_ "GenSigSNA" SG_ 973 OIL_TEMP_STAT "3h";
BA_ "GenSigSendType" SG_ 973 OIL_TEMP_STAT 5;
BA_ "GenSigCycleTime" SG_ 973 OIL_TEMP_STAT 2000;
BA_ "FlexKomSigStartValue" SG_ 973 OIL_TEMP_STAT "0000000000000000h";
BA_ "FlexKomSigStartPos" SG_ 973 OIL_TEMP_STAT 7;
BA_ "FlexKomSigName" SG_ 973 OIL_TEMP_STAT "IPC_LMPS_Pkt";
BA_ "FlexKomSigLaenge" SG_ 973 OIL_TEMP_STAT 64;
BA_ "FlexKomSID" SG_ 973 OIL_TEMP_STAT 2626;
BA_ "FlexKomIsMotorola" SG_ 973 OIL_TEMP_STAT 1;
BA_ "FlexKomComment" SG_ 973 OIL_TEMP_STAT "IPC_LMPS packet";
BA_ "RID" SG_ 973 SERVICE_STAT "6319";
BA_ "GenSigTimeout_ETM" SG_ 973 SERVICE_STAT 21000;
BA_ "GenSigSNA" SG_ 973 SERVICE_STAT "3h";
BA_ "GenSigSendType" SG_ 973 SERVICE_STAT 5;
BA_ "GenSigCycleTime" SG_ 973 SERVICE_STAT 2000;
BA_ "FlexKomSigStartValue" SG_ 973 SERVICE_STAT "0000000000000000h";
BA_ "FlexKomSigStartPos" SG_ 973 SERVICE_STAT 7;
BA_ "FlexKomSigName" SG_ 973 SERVICE_STAT "IPC_LMPS_Pkt";
BA_ "FlexKomSigLaenge" SG_ 973 SERVICE_STAT 64;
BA_ "FlexKomSID" SG_ 973 SERVICE_STAT 2626;
BA_ "FlexKomIsMotorola" SG_ 973 SERVICE_STAT 1;
BA_ "FlexKomComment" SG_ 973 SERVICE_STAT "IPC_LMPS packet";
BA_ "RID" SG_ 973 DAMPING_SYSTEM_STAT "6321";
BA_ "GenSigTimeout_ETM" SG_ 973 DAMPING_SYSTEM_STAT 21000;
BA_ "GenSigSNA" SG_ 973 DAMPING_SYSTEM_STAT "3h";
BA_ "GenSigSendType" SG_ 973 DAMPING_SYSTEM_STAT 5;
BA_ "GenSigCycleTime" SG_ 973 DAMPING_SYSTEM_STAT 2000;
BA_ "FlexKomSigStartValue" SG_ 973 DAMPING_SYSTEM_STAT "0000000000000000h";
BA_ "FlexKomSigStartPos" SG_ 973 DAMPING_SYSTEM_STAT 7;
BA_ "FlexKomSigName" SG_ 973 DAMPING_SYSTEM_STAT "IPC_LMPS_Pkt";
BA_ "FlexKomSigLaenge" SG_ 973 DAMPING_SYSTEM_STAT 64;
BA_ "FlexKomSID" SG_ 973 DAMPING_SYSTEM_STAT 2626;
BA_ "FlexKomIsMotorola" SG_ 973 DAMPING_SYSTEM_STAT 1;
BA_ "FlexKomComment" SG_ 973 DAMPING_SYSTEM_STAT "IPC_LMPS packet";
BA_ "RID" SG_ 973 BRAKE_PAD_STAT "6326";
BA_ "GenSigTimeout_ETM" SG_ 973 BRAKE_PAD_STAT 21000;
BA_ "GenSigSNA" SG_ 973 BRAKE_PAD_STAT "3h";
BA_ "GenSigSendType" SG_ 973 BRAKE_PAD_STAT 5;
BA_ "GenSigCycleTime" SG_ 973 BRAKE_PAD_STAT 2000;
BA_ "FlexKomSigStartValue" SG_ 973 BRAKE_PAD_STAT "0000000000000000h";
BA_ "FlexKomSigStartPos" SG_ 973 BRAKE_PAD_STAT 7;
BA_ "FlexKomSigName" SG_ 973 BRAKE_PAD_STAT "IPC_LMPS_Pkt";
BA_ "FlexKomSigLaenge" SG_ 973 BRAKE_PAD_STAT 64;
BA_ "FlexKomSID" SG_ 973 BRAKE_PAD_STAT 2626;
BA_ "FlexKomIsMotorola" SG_ 973 BRAKE_PAD_STAT 1;
BA_ "FlexKomComment" SG_ 973 BRAKE_PAD_STAT "IPC_LMPS packet";
BA_ "RID" SG_ 973 FOUR_WD_SERVICE_STAT "6303";
BA_ "GenSigTimeout_ETM" SG_ 973 FOUR_WD_SERVICE_STAT 21000;
BA_ "GenSigSNA" SG_ 973 FOUR_WD_SERVICE_STAT "3h";
BA_ "GenSigSendType" SG_ 973 FOUR_WD_SERVICE_STAT 5;
BA_ "GenSigCycleTime" SG_ 973 FOUR_WD_SERVICE_STAT 2000;
BA_ "FlexKomSigStartValue" SG_ 973 FOUR_WD_SERVICE_STAT "0000000000000000h";
BA_ "FlexKomSigStartPos" SG_ 973 FOUR_WD_SERVICE_STAT 7;
BA_ "FlexKomSigName" SG_ 973 FOUR_WD_SERVICE_STAT "IPC_LMPS_Pkt";
BA_ "FlexKomSigLaenge" SG_ 973 FOUR_WD_SERVICE_STAT 64;
BA_ "FlexKomSID" SG_ 973 FOUR_WD_SERVICE_STAT 2626;
BA_ "FlexKomIsMotorola" SG_ 973 FOUR_WD_SERVICE_STAT 1;
BA_ "FlexKomComment" SG_ 973 FOUR_WD_SERVICE_STAT "IPC_LMPS packet";
BA_ "RID" SG_ 973 LANE_SENSE_STAT "6314";
BA_ "GenSigTimeout_ETM" SG_ 973 LANE_SENSE_STAT 21000;
BA_ "GenSigSNA" SG_ 973 LANE_SENSE_STAT "3h";
BA_ "GenSigSendType" SG_ 973 LANE_SENSE_STAT 5;
BA_ "GenSigCycleTime" SG_ 973 LANE_SENSE_STAT 2000;
BA_ "FlexKomSigStartValue" SG_ 973 LANE_SENSE_STAT "0000000000000000h";
BA_ "FlexKomSigStartPos" SG_ 973 LANE_SENSE_STAT 7;
BA_ "FlexKomSigName" SG_ 973 LANE_SENSE_STAT "IPC_LMPS_Pkt";
BA_ "FlexKomSigLaenge" SG_ 973 LANE_SENSE_STAT 64;
BA_ "FlexKomSID" SG_ 973 LANE_SENSE_STAT 2626;
BA_ "FlexKomIsMotorola" SG_ 973 LANE_SENSE_STAT 1;
BA_ "FlexKomComment" SG_ 973 LANE_SENSE_STAT "IPC_LMPS packet";
BA_ "RID" SG_ 973 AWD_SERVICE_STAT "6323";
BA_ "GenSigTimeout_ETM" SG_ 973 AWD_SERVICE_STAT 21000;
BA_ "GenSigSNA" SG_ 973 AWD_SERVICE_STAT "3h";
BA_ "GenSigSendType" SG_ 973 AWD_SERVICE_STAT 5;
BA_ "GenSigCycleTime" SG_ 973 AWD_SERVICE_STAT 2000;
BA_ "FlexKomSigStartValue" SG_ 973 AWD_SERVICE_STAT "0000000000000000h";
BA_ "FlexKomSigStartPos" SG_ 973 AWD_SERVICE_STAT 7;
BA_ "FlexKomSigName" SG_ 973 AWD_SERVICE_STAT "IPC_LMPS_Pkt";
BA_ "FlexKomSigLaenge" SG_ 973 AWD_SERVICE_STAT 64;
BA_ "FlexKomSID" SG_ 973 AWD_SERVICE_STAT 2626;
BA_ "FlexKomIsMotorola" SG_ 973 AWD_SERVICE_STAT 1;
BA_ "FlexKomComment" SG_ 973 AWD_SERVICE_STAT "IPC_LMPS packet";
BA_ "GenSigSNA" SG_ 973 FOA_AppAlert_Disable_UserReq "0h";
BA_ "GenSigSendType" SG_ 973 FOA_AppAlert_Disable_UserReq 5;
BA_ "GenSigCycleTime" SG_ 973 FOA_AppAlert_Disable_UserReq 2000;
BA_ "FlexKomSigStartValue" SG_ 973 FOA_AppAlert_Disable_UserReq "0000000000000000h";
BA_ "FlexKomSigStartPos" SG_ 973 FOA_AppAlert_Disable_UserReq 7;
BA_ "FlexKomSigName" SG_ 973 FOA_AppAlert_Disable_UserReq "IPC_LMPS_Pkt";
BA_ "FlexKomSigLaenge" SG_ 973 FOA_AppAlert_Disable_UserReq 64;
BA_ "FlexKomSID" SG_ 973 FOA_AppAlert_Disable_UserReq 2626;
BA_ "FlexKomIsMotorola" SG_ 973 FOA_AppAlert_Disable_UserReq 1;
BA_ "FlexKomComment" SG_ 973 FOA_AppAlert_Disable_UserReq "IPC_LMPS packet";
BA_ "GenSigTimeout_IC" SG_ 976 PF_WARN_MSG 5250;
BA_ "GenSigSNA" SG_ 976 PF_WARN_MSG "0h";
BA_ "GenSigCycleTime" SG_ 976 PF_WARN_MSG 500;
BA_ "FlexKomSigStartValue" SG_ 976 PF_WARN_MSG "0000000000000000h";
BA_ "FlexKomSigStartPos" SG_ 976 PF_WARN_MSG 7;
BA_ "FlexKomSigName" SG_ 976 PF_WARN_MSG "ECM_A4_Pkt";
BA_ "FlexKomSigLaenge" SG_ 976 PF_WARN_MSG 64;
BA_ "FlexKomSID" SG_ 976 PF_WARN_MSG 2627;
BA_ "FlexKomIsMotorola" SG_ 976 PF_WARN_MSG 1;
BA_ "FlexKomComment" SG_ 976 PF_WARN_MSG "ECM_A4 Packet";
BA_ "GenSigTimeout_IC" SG_ 976 KNK_MG_TRIGGER 5250;
BA_ "GenSigSNA" SG_ 976 KNK_MG_TRIGGER "0h";
BA_ "GenSigCycleTime" SG_ 976 KNK_MG_TRIGGER 500;
BA_ "FlexKomSigStartValue" SG_ 976 KNK_MG_TRIGGER "0000000000000000h";
BA_ "FlexKomSigStartPos" SG_ 976 KNK_MG_TRIGGER 7;
BA_ "FlexKomSigName" SG_ 976 KNK_MG_TRIGGER "ECM_A4_Pkt";
BA_ "FlexKomSigLaenge" SG_ 976 KNK_MG_TRIGGER 64;
BA_ "FlexKomSID" SG_ 976 KNK_MG_TRIGGER 2627;
BA_ "FlexKomIsMotorola" SG_ 976 KNK_MG_TRIGGER 1;
BA_ "FlexKomComment" SG_ 976 KNK_MG_TRIGGER "ECM_A4 Packet";
BA_ "GenSigStartValue" SG_ 979 EC_ECUCfg14_Stat 3;
BA_ "GenSigSNA" SG_ 979 EC_ECUCfg14_Stat "3h";
BA_ "GenSigCycleTime" SG_ 979 EC_ECUCfg14_Stat 2000;
BA_ "FlexKomSigStartValue" SG_ 979 EC_ECUCfg14_Stat "03h";
BA_ "FlexKomSigStartPos" SG_ 979 EC_ECUCfg14_Stat 1;
BA_ "FlexKomSigName" SG_ 979 EC_ECUCfg14_Stat "EC_ECUCfg14_Stat";
BA_ "FlexKomSigLaenge" SG_ 979 EC_ECUCfg14_Stat 2;
BA_ "FlexKomSID" SG_ 979 EC_ECUCfg14_Stat 1950;
BA_ "FlexKomIsMotorola" SG_ 979 EC_ECUCfg14_Stat 1;
BA_ "FlexKomComment" SG_ 979 EC_ECUCfg14_Stat "ECU Configuration messages status 14";
BA_ "GenSigSNA" SG_ 979 EC_CBC14A "0h";
BA_ "GenSigCycleTime" SG_ 979 EC_CBC14A 2000;
BA_ "FlexKomSigStartValue" SG_ 979 EC_CBC14A "0000000000000000h";
BA_ "FlexKomSigStartPos" SG_ 979 EC_CBC14A 7;
BA_ "FlexKomSigName" SG_ 979 EC_CBC14A "EC_CBC14";
BA_ "FlexKomSigLaenge" SG_ 979 EC_CBC14A 64;
BA_ "FlexKomSID" SG_ 979 EC_CBC14A 1951;
BA_ "FlexKomIsMotorola" SG_ 979 EC_CBC14A 1;
BA_ "FlexKomComment" SG_ 979 EC_CBC14A "CBC ecu configuration 14";
BA_ "GenSigSNA" SG_ 979 EC_CBC14B "0h";
BA_ "GenSigCycleTime" SG_ 979 EC_CBC14B 2000;
BA_ "FlexKomSigStartValue" SG_ 979 EC_CBC14B "0000000000000000h";
BA_ "FlexKomSigStartPos" SG_ 979 EC_CBC14B 7;
BA_ "FlexKomSigName" SG_ 979 EC_CBC14B "EC_CBC14";
BA_ "FlexKomSigLaenge" SG_ 979 EC_CBC14B 64;
BA_ "FlexKomSID" SG_ 979 EC_CBC14B 1951;
BA_ "FlexKomIsMotorola" SG_ 979 EC_CBC14B 1;
BA_ "FlexKomComment" SG_ 979 EC_CBC14B "CBC ecu configuration 14";
BA_ "GenSigStartValue" SG_ 980 EC_ECUCfg13_Stat 3;
BA_ "GenSigSNA" SG_ 980 EC_ECUCfg13_Stat "3h";
BA_ "GenSigCycleTime" SG_ 980 EC_ECUCfg13_Stat 2000;
BA_ "FlexKomSigStartValue" SG_ 980 EC_ECUCfg13_Stat "03h";
BA_ "FlexKomSigStartPos" SG_ 980 EC_ECUCfg13_Stat 1;
BA_ "FlexKomSigName" SG_ 980 EC_ECUCfg13_Stat "EC_ECUCfg13_Stat";
BA_ "FlexKomSigLaenge" SG_ 980 EC_ECUCfg13_Stat 2;
BA_ "FlexKomSID" SG_ 980 EC_ECUCfg13_Stat 1868;
BA_ "FlexKomIsMotorola" SG_ 980 EC_ECUCfg13_Stat 1;
BA_ "FlexKomComment" SG_ 980 EC_ECUCfg13_Stat "ECU Configuration messages status 13";
BA_ "GenSigSNA" SG_ 980 EC_CBC13A "0h";
BA_ "GenSigCycleTime" SG_ 980 EC_CBC13A 2000;
BA_ "FlexKomSigStartValue" SG_ 980 EC_CBC13A "0000000000000000h";
BA_ "FlexKomSigStartPos" SG_ 980 EC_CBC13A 7;
BA_ "FlexKomSigName" SG_ 980 EC_CBC13A "EC_CBC13";
BA_ "FlexKomSigLaenge" SG_ 980 EC_CBC13A 64;
BA_ "FlexKomSID" SG_ 980 EC_CBC13A 1990;
BA_ "FlexKomIsMotorola" SG_ 980 EC_CBC13A 1;
BA_ "FlexKomComment" SG_ 980 EC_CBC13A "CBC ecu configuration 13";
BA_ "GenSigSNA" SG_ 980 EC_CBC13B "0h";
BA_ "GenSigCycleTime" SG_ 980 EC_CBC13B 2000;
BA_ "FlexKomSigStartValue" SG_ 980 EC_CBC13B "0000000000000000h";
BA_ "FlexKomSigStartPos" SG_ 980 EC_CBC13B 7;
BA_ "FlexKomSigName" SG_ 980 EC_CBC13B "EC_CBC13";
BA_ "FlexKomSigLaenge" SG_ 980 EC_CBC13B 64;
BA_ "FlexKomSID" SG_ 980 EC_CBC13B 1990;
BA_ "FlexKomIsMotorola" SG_ 980 EC_CBC13B 1;
BA_ "FlexKomComment" SG_ 980 EC_CBC13B "CBC ecu configuration 13";
BA_ "GenSigTimeout_RF_HUB" SG_ 981 EC_ECUCfg12_Stat 21000;
BA_ "GenSigTimeout_IC" SG_ 981 EC_ECUCfg12_Stat 21000;
BA_ "GenSigStartValue" SG_ 981 EC_ECUCfg12_Stat 3;
BA_ "GenSigSNA" SG_ 981 EC_ECUCfg12_Stat "3h";
BA_ "GenSigSendType" SG_ 981 EC_ECUCfg12_Stat 5;
BA_ "GenSigCycleTime" SG_ 981 EC_ECUCfg12_Stat 2000;
BA_ "FlexKomSigStartValue" SG_ 981 EC_ECUCfg12_Stat "03h";
BA_ "FlexKomSigStartPos" SG_ 981 EC_ECUCfg12_Stat 1;
BA_ "FlexKomSigName" SG_ 981 EC_ECUCfg12_Stat "EC_ECUCfg12_Stat";
BA_ "FlexKomSigLaenge" SG_ 981 EC_ECUCfg12_Stat 2;
BA_ "FlexKomSID" SG_ 981 EC_ECUCfg12_Stat 1834;
BA_ "FlexKomIsMotorola" SG_ 981 EC_ECUCfg12_Stat 1;
BA_ "FlexKomComment" SG_ 981 EC_ECUCfg12_Stat "ECU Configuration messages status 12";
BA_ "GenSigTimeout_RF_HUB" SG_ 981 EC_Cluster5A 21000;
BA_ "GenSigTimeout_IC" SG_ 981 EC_Cluster5A 21000;
BA_ "GenSigSNA" SG_ 981 EC_Cluster5A "0h";
BA_ "GenSigSendType" SG_ 981 EC_Cluster5A 5;
BA_ "GenSigCycleTime" SG_ 981 EC_Cluster5A 2000;
BA_ "FlexKomSigStartValue" SG_ 981 EC_Cluster5A "0000000000000000h";
BA_ "FlexKomSigStartPos" SG_ 981 EC_Cluster5A 7;
BA_ "FlexKomSigName" SG_ 981 EC_Cluster5A "EC_Cluster5";
BA_ "FlexKomSigLaenge" SG_ 981 EC_Cluster5A 64;
BA_ "FlexKomSID" SG_ 981 EC_Cluster5A 1835;
BA_ "FlexKomIsMotorola" SG_ 981 EC_Cluster5A 1;
BA_ "FlexKomComment" SG_ 981 EC_Cluster5A "Instrument cluster ecu configuration 5";
BA_ "GenSigTimeout_RF_HUB" SG_ 981 EC_Cluster5B 21000;
BA_ "GenSigTimeout_IC" SG_ 981 EC_Cluster5B 21000;
BA_ "GenSigSNA" SG_ 981 EC_Cluster5B "0h";
BA_ "GenSigSendType" SG_ 981 EC_Cluster5B 5;
BA_ "GenSigCycleTime" SG_ 981 EC_Cluster5B 2000;
BA_ "FlexKomSigStartValue" SG_ 981 EC_Cluster5B "0000000000000000h";
BA_ "FlexKomSigStartPos" SG_ 981 EC_Cluster5B 7;
BA_ "FlexKomSigName" SG_ 981 EC_Cluster5B "EC_Cluster5";
BA_ "FlexKomSigLaenge" SG_ 981 EC_Cluster5B 64;
BA_ "FlexKomSID" SG_ 981 EC_Cluster5B 1835;
BA_ "FlexKomIsMotorola" SG_ 981 EC_Cluster5B 1;
BA_ "FlexKomComment" SG_ 981 EC_Cluster5B "Instrument cluster ecu configuration 5";
BA_ "GenSigTimeout_RF_HUB" SG_ 981 EC_Cluster5C 21000;
BA_ "GenSigTimeout_IC" SG_ 981 EC_Cluster5C 21000;
BA_ "GenSigSNA" SG_ 981 EC_Cluster5C "0h";
BA_ "GenSigSendType" SG_ 981 EC_Cluster5C 5;
BA_ "GenSigCycleTime" SG_ 981 EC_Cluster5C 2000;
BA_ "FlexKomSigStartValue" SG_ 981 EC_Cluster5C "0000000000000000h";
BA_ "FlexKomSigStartPos" SG_ 981 EC_Cluster5C 7;
BA_ "FlexKomSigName" SG_ 981 EC_Cluster5C "EC_Cluster5";
BA_ "FlexKomSigLaenge" SG_ 981 EC_Cluster5C 64;
BA_ "FlexKomSID" SG_ 981 EC_Cluster5C 1835;
BA_ "FlexKomIsMotorola" SG_ 981 EC_Cluster5C 1;
BA_ "FlexKomComment" SG_ 981 EC_Cluster5C "Instrument cluster ecu configuration 5";
BA_ "GenSigStartValue" SG_ 982 EC_ECUCfg11_Stat 3;
BA_ "GenSigSNA" SG_ 982 EC_ECUCfg11_Stat "3h";
BA_ "GenSigCycleTime" SG_ 982 EC_ECUCfg11_Stat 2000;
BA_ "FlexKomSigStartValue" SG_ 982 EC_ECUCfg11_Stat "03h";
BA_ "FlexKomSigStartPos" SG_ 982 EC_ECUCfg11_Stat 1;
BA_ "FlexKomSigName" SG_ 982 EC_ECUCfg11_Stat "EC_ECUCfg11_Stat";
BA_ "FlexKomSigLaenge" SG_ 982 EC_ECUCfg11_Stat 2;
BA_ "FlexKomSID" SG_ 982 EC_ECUCfg11_Stat 1708;
BA_ "FlexKomIsMotorola" SG_ 982 EC_ECUCfg11_Stat 1;
BA_ "FlexKomComment" SG_ 982 EC_ECUCfg11_Stat "ECU Configuration messages status 11";
BA_ "GenSigSNA" SG_ 982 EC_CBC10A "0h";
BA_ "GenSigCycleTime" SG_ 982 EC_CBC10A 2000;
BA_ "FlexKomSigStartValue" SG_ 982 EC_CBC10A "00000000h";
BA_ "FlexKomSigStartPos" SG_ 982 EC_CBC10A 7;
BA_ "FlexKomSigName" SG_ 982 EC_CBC10A "EC_CBC10";
BA_ "FlexKomSigLaenge" SG_ 982 EC_CBC10A 32;
BA_ "FlexKomSID" SG_ 982 EC_CBC10A 1709;
BA_ "FlexKomIsMotorola" SG_ 982 EC_CBC10A 1;
BA_ "FlexKomComment" SG_ 982 EC_CBC10A "CBC ecu configuration 10";
BA_ "GenSigSNA" SG_ 982 EC_CBC10B "0h";
BA_ "GenSigCycleTime" SG_ 982 EC_CBC10B 2000;
BA_ "FlexKomSigStartValue" SG_ 982 EC_CBC10B "00000000h";
BA_ "FlexKomSigStartPos" SG_ 982 EC_CBC10B 7;
BA_ "FlexKomSigName" SG_ 982 EC_CBC10B "EC_CBC10";
BA_ "FlexKomSigLaenge" SG_ 982 EC_CBC10B 32;
BA_ "FlexKomSID" SG_ 982 EC_CBC10B 1709;
BA_ "FlexKomIsMotorola" SG_ 982 EC_CBC10B 1;
BA_ "FlexKomComment" SG_ 982 EC_CBC10B "CBC ecu configuration 10";
BA_ "GenSigSNA" SG_ 982 EC_CBC11 "0h";
BA_ "GenSigCycleTime" SG_ 982 EC_CBC11 2000;
BA_ "FlexKomSigStartValue" SG_ 982 EC_CBC11 "00000000h";
BA_ "FlexKomSigStartPos" SG_ 982 EC_CBC11 39;
BA_ "FlexKomSigName" SG_ 982 EC_CBC11 "EC_CBC11";
BA_ "FlexKomSigLaenge" SG_ 982 EC_CBC11 32;
BA_ "FlexKomSID" SG_ 982 EC_CBC11 1710;
BA_ "FlexKomIsMotorola" SG_ 982 EC_CBC11 1;
BA_ "FlexKomComment" SG_ 982 EC_CBC11 "CBC ecu configuration 11";
BA_ "GenSigTimeout_IC" SG_ 983 EC_Cluster4 21000;
BA_ "GenSigSNA" SG_ 983 EC_Cluster4 "0h";
BA_ "GenSigSendType" SG_ 983 EC_Cluster4 5;
BA_ "GenSigCycleTime" SG_ 983 EC_Cluster4 2000;
BA_ "FlexKomSigStartValue" SG_ 983 EC_Cluster4 "00000000h";
BA_ "FlexKomSigStartPos" SG_ 983 EC_Cluster4 39;
BA_ "FlexKomSigName" SG_ 983 EC_Cluster4 "EC_Cluster4";
BA_ "FlexKomSigLaenge" SG_ 983 EC_Cluster4 32;
BA_ "FlexKomSID" SG_ 983 EC_Cluster4 1306;
BA_ "FlexKomIsMotorola" SG_ 983 EC_Cluster4 1;
BA_ "FlexKomComment" SG_ 983 EC_Cluster4 "Instrument cluster ecu configuration 4";
BA_ "GenSigTimeout_IC" SG_ 983 EC_ECUCfg10_Stat 21000;
BA_ "GenSigStartValue" SG_ 983 EC_ECUCfg10_Stat 3;
BA_ "GenSigSNA" SG_ 983 EC_ECUCfg10_Stat "3h";
BA_ "GenSigSendType" SG_ 983 EC_ECUCfg10_Stat 5;
BA_ "GenSigCycleTime" SG_ 983 EC_ECUCfg10_Stat 2000;
BA_ "FlexKomSigStartValue" SG_ 983 EC_ECUCfg10_Stat "03h";
BA_ "FlexKomSigStartPos" SG_ 983 EC_ECUCfg10_Stat 1;
BA_ "FlexKomSigName" SG_ 983 EC_ECUCfg10_Stat "EC_ECUCfg10_Stat";
BA_ "FlexKomSigLaenge" SG_ 983 EC_ECUCfg10_Stat 2;
BA_ "FlexKomSID" SG_ 983 EC_ECUCfg10_Stat 1303;
BA_ "FlexKomIsMotorola" SG_ 983 EC_ECUCfg10_Stat 1;
BA_ "FlexKomComment" SG_ 983 EC_ECUCfg10_Stat "ECU Configuration messages status 10";
BA_ "GenSigTimeout_IC" SG_ 983 EC_Cluster3A 21000;
BA_ "GenSigSNA" SG_ 983 EC_Cluster3A "0h";
BA_ "GenSigSendType" SG_ 983 EC_Cluster3A 5;
BA_ "GenSigCycleTime" SG_ 983 EC_Cluster3A 2000;
BA_ "FlexKomSigStartValue" SG_ 983 EC_Cluster3A "00000000h";
BA_ "FlexKomSigStartPos" SG_ 983 EC_Cluster3A 7;
BA_ "FlexKomSigName" SG_ 983 EC_Cluster3A "EC_Cluster3";
BA_ "FlexKomSigLaenge" SG_ 983 EC_Cluster3A 32;
BA_ "FlexKomSID" SG_ 983 EC_Cluster3A 1307;
BA_ "FlexKomIsMotorola" SG_ 983 EC_Cluster3A 1;
BA_ "FlexKomComment" SG_ 983 EC_Cluster3A "Instrument cluster ecu configuration 3";
BA_ "GenSigTimeout_IC" SG_ 983 EC_Cluster3B 21000;
BA_ "GenSigSNA" SG_ 983 EC_Cluster3B "0h";
BA_ "GenSigSendType" SG_ 983 EC_Cluster3B 5;
BA_ "GenSigCycleTime" SG_ 983 EC_Cluster3B 2000;
BA_ "FlexKomSigStartValue" SG_ 983 EC_Cluster3B "00000000h";
BA_ "FlexKomSigStartPos" SG_ 983 EC_Cluster3B 7;
BA_ "FlexKomSigName" SG_ 983 EC_Cluster3B "EC_Cluster3";
BA_ "FlexKomSigLaenge" SG_ 983 EC_Cluster3B 32;
BA_ "FlexKomSID" SG_ 983 EC_Cluster3B 1307;
BA_ "FlexKomIsMotorola" SG_ 983 EC_Cluster3B 1;
BA_ "FlexKomComment" SG_ 983 EC_Cluster3B "Instrument cluster ecu configuration 3";
BA_ "GenSigStartValue" SG_ 984 EC_ECUCfg9_Stat 3;
BA_ "GenSigSNA" SG_ 984 EC_ECUCfg9_Stat "3h";
BA_ "GenSigCycleTime" SG_ 984 EC_ECUCfg9_Stat 2000;
BA_ "FlexKomSigStartValue" SG_ 984 EC_ECUCfg9_Stat "03h";
BA_ "FlexKomSigStartPos" SG_ 984 EC_ECUCfg9_Stat 1;
BA_ "FlexKomSigName" SG_ 984 EC_ECUCfg9_Stat "EC_ECUCfg9_Stat";
BA_ "FlexKomSigLaenge" SG_ 984 EC_ECUCfg9_Stat 2;
BA_ "FlexKomSID" SG_ 984 EC_ECUCfg9_Stat 1215;
BA_ "FlexKomIsMotorola" SG_ 984 EC_ECUCfg9_Stat 1;
BA_ "FlexKomComment" SG_ 984 EC_ECUCfg9_Stat "ECU Configuration messages status 9";
BA_ "GenSigSNA" SG_ 984 EC_CBC9A1 "0h";
BA_ "GenSigCycleTime" SG_ 984 EC_CBC9A1 2000;
BA_ "FlexKomSigStartValue" SG_ 984 EC_CBC9A1 "00000000h";
BA_ "FlexKomSigStartPos" SG_ 984 EC_CBC9A1 7;
BA_ "FlexKomSigName" SG_ 984 EC_CBC9A1 "EC_CBC9A";
BA_ "FlexKomSigLaenge" SG_ 984 EC_CBC9A1 32;
BA_ "FlexKomSID" SG_ 984 EC_CBC9A1 1421;
BA_ "FlexKomIsMotorola" SG_ 984 EC_CBC9A1 1;
BA_ "FlexKomComment" SG_ 984 EC_CBC9A1 "CBC configuration 9A";
BA_ "GenSigSNA" SG_ 984 EC_CBC9A2 "0h";
BA_ "GenSigCycleTime" SG_ 984 EC_CBC9A2 2000;
BA_ "FlexKomSigStartValue" SG_ 984 EC_CBC9A2 "00000000h";
BA_ "FlexKomSigStartPos" SG_ 984 EC_CBC9A2 7;
BA_ "FlexKomSigName" SG_ 984 EC_CBC9A2 "EC_CBC9A";
BA_ "FlexKomSigLaenge" SG_ 984 EC_CBC9A2 32;
BA_ "FlexKomSID" SG_ 984 EC_CBC9A2 1421;
BA_ "FlexKomIsMotorola" SG_ 984 EC_CBC9A2 1;
BA_ "FlexKomComment" SG_ 984 EC_CBC9A2 "CBC configuration 9A";
BA_ "GenSigSNA" SG_ 984 EC_CBC9B "0h";
BA_ "GenSigCycleTime" SG_ 984 EC_CBC9B 2000;
BA_ "FlexKomSigStartValue" SG_ 984 EC_CBC9B "0000h";
BA_ "FlexKomSigStartPos" SG_ 984 EC_CBC9B 39;
BA_ "FlexKomSigName" SG_ 984 EC_CBC9B "EC_CBC9B";
BA_ "FlexKomSigLaenge" SG_ 984 EC_CBC9B 16;
BA_ "FlexKomSID" SG_ 984 EC_CBC9B 1422;
BA_ "FlexKomIsMotorola" SG_ 984 EC_CBC9B 1;
BA_ "FlexKomComment" SG_ 984 EC_CBC9B "CBC configuration 9B";
BA_ "GenSigSNA" SG_ 984 EC_ITM "0h";
BA_ "GenSigCycleTime" SG_ 984 EC_ITM 2000;
BA_ "FlexKomSigStartValue" SG_ 984 EC_ITM "0000h";
BA_ "FlexKomSigStartPos" SG_ 984 EC_ITM 55;
BA_ "FlexKomSigName" SG_ 984 EC_ITM "EC_ITM";
BA_ "FlexKomSigLaenge" SG_ 984 EC_ITM 16;
BA_ "FlexKomSID" SG_ 984 EC_ITM 1219;
BA_ "FlexKomIsMotorola" SG_ 984 EC_ITM 1;
BA_ "FlexKomComment" SG_ 984 EC_ITM "ITM ecu configuration";
BA_ "GenSigStartValue" SG_ 985 EC_BU_ECUCfg14_Stat 3;
BA_ "GenSigSNA" SG_ 985 EC_BU_ECUCfg14_Stat "3h";
BA_ "GenSigSendType" SG_ 985 EC_BU_ECUCfg14_Stat 1;
BA_ "FlexKomSigStartValue" SG_ 985 EC_BU_ECUCfg14_Stat "03h";
BA_ "FlexKomSigStartPos" SG_ 985 EC_BU_ECUCfg14_Stat 1;
BA_ "FlexKomSigName" SG_ 985 EC_BU_ECUCfg14_Stat "EC_BU_ECUCfg14_Stat";
BA_ "FlexKomSigLaenge" SG_ 985 EC_BU_ECUCfg14_Stat 2;
BA_ "FlexKomSID" SG_ 985 EC_BU_ECUCfg14_Stat 1952;
BA_ "FlexKomIsMotorola" SG_ 985 EC_BU_ECUCfg14_Stat 1;
BA_ "FlexKomComment" SG_ 985 EC_BU_ECUCfg14_Stat "Backup for ECU Configuration messages status 14";
BA_ "GenSigSNA" SG_ 985 EC_BU_CBC14A "0h";
BA_ "GenSigSendType" SG_ 985 EC_BU_CBC14A 1;
BA_ "FlexKomSigStartValue" SG_ 985 EC_BU_CBC14A "0000000000000000h";
BA_ "FlexKomSigStartPos" SG_ 985 EC_BU_CBC14A 7;
BA_ "FlexKomSigName" SG_ 985 EC_BU_CBC14A "EC_BU_CBC14";
BA_ "FlexKomSigLaenge" SG_ 985 EC_BU_CBC14A 64;
BA_ "FlexKomSID" SG_ 985 EC_BU_CBC14A 1953;
BA_ "FlexKomIsMotorola" SG_ 985 EC_BU_CBC14A 1;
BA_ "FlexKomComment" SG_ 985 EC_BU_CBC14A "CBC ecu configuration 14";
BA_ "GenSigSNA" SG_ 985 EC_BU_CBC14B "0h";
BA_ "GenSigSendType" SG_ 985 EC_BU_CBC14B 1;
BA_ "FlexKomSigStartValue" SG_ 985 EC_BU_CBC14B "0000000000000000h";
BA_ "FlexKomSigStartPos" SG_ 985 EC_BU_CBC14B 7;
BA_ "FlexKomSigName" SG_ 985 EC_BU_CBC14B "EC_BU_CBC14";
BA_ "FlexKomSigLaenge" SG_ 985 EC_BU_CBC14B 64;
BA_ "FlexKomSID" SG_ 985 EC_BU_CBC14B 1953;
BA_ "FlexKomIsMotorola" SG_ 985 EC_BU_CBC14B 1;
BA_ "FlexKomComment" SG_ 985 EC_BU_CBC14B "CBC ecu configuration 14";
BA_ "GenSigStartValue" SG_ 986 EC_BU_ECUCfg13_Stat 3;
BA_ "GenSigSNA" SG_ 986 EC_BU_ECUCfg13_Stat "3h";
BA_ "GenSigSendType" SG_ 986 EC_BU_ECUCfg13_Stat 1;
BA_ "FlexKomSigStartValue" SG_ 986 EC_BU_ECUCfg13_Stat "03h";
BA_ "FlexKomSigStartPos" SG_ 986 EC_BU_ECUCfg13_Stat 1;
BA_ "FlexKomSigName" SG_ 986 EC_BU_ECUCfg13_Stat "EC_BU_ECUCfg13_Stat";
BA_ "FlexKomSigLaenge" SG_ 986 EC_BU_ECUCfg13_Stat 2;
BA_ "FlexKomSID" SG_ 986 EC_BU_ECUCfg13_Stat 1871;
BA_ "FlexKomIsMotorola" SG_ 986 EC_BU_ECUCfg13_Stat 1;
BA_ "FlexKomComment" SG_ 986 EC_BU_ECUCfg13_Stat "Backup for ECU Configuration messages status 13";
BA_ "GenSigSNA" SG_ 986 EC_BU_CBC13A "0h";
BA_ "GenSigSendType" SG_ 986 EC_BU_CBC13A 1;
BA_ "FlexKomSigStartValue" SG_ 986 EC_BU_CBC13A "0000000000000000h";
BA_ "FlexKomSigStartPos" SG_ 986 EC_BU_CBC13A 7;
BA_ "FlexKomSigName" SG_ 986 EC_BU_CBC13A "EC_BU_CBC13";
BA_ "FlexKomSigLaenge" SG_ 986 EC_BU_CBC13A 64;
BA_ "FlexKomSID" SG_ 986 EC_BU_CBC13A 1991;
BA_ "FlexKomIsMotorola" SG_ 986 EC_BU_CBC13A 1;
BA_ "FlexKomComment" SG_ 986 EC_BU_CBC13A "CBC ecu configuration 13";
BA_ "GenSigSNA" SG_ 986 EC_BU_CBC13B "0h";
BA_ "GenSigSendType" SG_ 986 EC_BU_CBC13B 1;
BA_ "FlexKomSigStartValue" SG_ 986 EC_BU_CBC13B "0000000000000000h";
BA_ "FlexKomSigStartPos" SG_ 986 EC_BU_CBC13B 7;
BA_ "FlexKomSigName" SG_ 986 EC_BU_CBC13B "EC_BU_CBC13";
BA_ "FlexKomSigLaenge" SG_ 986 EC_BU_CBC13B 64;
BA_ "FlexKomSID" SG_ 986 EC_BU_CBC13B 1991;
BA_ "FlexKomIsMotorola" SG_ 986 EC_BU_CBC13B 1;
BA_ "FlexKomComment" SG_ 986 EC_BU_CBC13B "CBC ecu configuration 13";
BA_ "GenSigStartValue" SG_ 987 EC_BU_ECUCfg12_Stat 3;
BA_ "GenSigSNA" SG_ 987 EC_BU_ECUCfg12_Stat "3h";
BA_ "GenSigSendType" SG_ 987 EC_BU_ECUCfg12_Stat 1;
BA_ "FlexKomSigStartValue" SG_ 987 EC_BU_ECUCfg12_Stat "03h";
BA_ "FlexKomSigStartPos" SG_ 987 EC_BU_ECUCfg12_Stat 1;
BA_ "FlexKomSigName" SG_ 987 EC_BU_ECUCfg12_Stat "EC_BU_ECUCfg12_Stat";
BA_ "FlexKomSigLaenge" SG_ 987 EC_BU_ECUCfg12_Stat 2;
BA_ "FlexKomSID" SG_ 987 EC_BU_ECUCfg12_Stat 1836;
BA_ "FlexKomIsMotorola" SG_ 987 EC_BU_ECUCfg12_Stat 1;
BA_ "FlexKomComment" SG_ 987 EC_BU_ECUCfg12_Stat "Backup for ECU Configuration messages status 12";
BA_ "GenSigSNA" SG_ 987 EC_BU_Cluster5A "0h";
BA_ "GenSigSendType" SG_ 987 EC_BU_Cluster5A 1;
BA_ "FlexKomSigStartValue" SG_ 987 EC_BU_Cluster5A "0000000000000000h";
BA_ "FlexKomSigStartPos" SG_ 987 EC_BU_Cluster5A 7;
BA_ "FlexKomSigName" SG_ 987 EC_BU_Cluster5A "EC_BU_Cluster5";
BA_ "FlexKomSigLaenge" SG_ 987 EC_BU_Cluster5A 64;
BA_ "FlexKomSID" SG_ 987 EC_BU_Cluster5A 1837;
BA_ "FlexKomIsMotorola" SG_ 987 EC_BU_Cluster5A 1;
BA_ "FlexKomComment" SG_ 987 EC_BU_Cluster5A "Backup for Instrument cluster ecu configuration 5";
BA_ "GenSigSNA" SG_ 987 EC_BU_Cluster5B "0h";
BA_ "GenSigSendType" SG_ 987 EC_BU_Cluster5B 1;
BA_ "FlexKomSigStartValue" SG_ 987 EC_BU_Cluster5B "0000000000000000h";
BA_ "FlexKomSigStartPos" SG_ 987 EC_BU_Cluster5B 7;
BA_ "FlexKomSigName" SG_ 987 EC_BU_Cluster5B "EC_BU_Cluster5";
BA_ "FlexKomSigLaenge" SG_ 987 EC_BU_Cluster5B 64;
BA_ "FlexKomSID" SG_ 987 EC_BU_Cluster5B 1837;
BA_ "FlexKomIsMotorola" SG_ 987 EC_BU_Cluster5B 1;
BA_ "FlexKomComment" SG_ 987 EC_BU_Cluster5B "Backup for Instrument cluster ecu configuration 5";
BA_ "GenSigSNA" SG_ 987 EC_BU_Cluster5C "0h";
BA_ "GenSigSendType" SG_ 987 EC_BU_Cluster5C 1;
BA_ "FlexKomSigStartValue" SG_ 987 EC_BU_Cluster5C "0000000000000000h";
BA_ "FlexKomSigStartPos" SG_ 987 EC_BU_Cluster5C 7;
BA_ "FlexKomSigName" SG_ 987 EC_BU_Cluster5C "EC_BU_Cluster5";
BA_ "FlexKomSigLaenge" SG_ 987 EC_BU_Cluster5C 64;
BA_ "FlexKomSID" SG_ 987 EC_BU_Cluster5C 1837;
BA_ "FlexKomIsMotorola" SG_ 987 EC_BU_Cluster5C 1;
BA_ "FlexKomComment" SG_ 987 EC_BU_Cluster5C "Backup for Instrument cluster ecu configuration 5";
BA_ "GenSigStartValue" SG_ 988 EC_BU_ECUCfg11_Stat 3;
BA_ "GenSigSNA" SG_ 988 EC_BU_ECUCfg11_Stat "3h";
BA_ "GenSigSendType" SG_ 988 EC_BU_ECUCfg11_Stat 1;
BA_ "FlexKomSigStartValue" SG_ 988 EC_BU_ECUCfg11_Stat "03h";
BA_ "FlexKomSigStartPos" SG_ 988 EC_BU_ECUCfg11_Stat 1;
BA_ "FlexKomSigName" SG_ 988 EC_BU_ECUCfg11_Stat "EC_BU_ECUCfg11_Stat";
BA_ "FlexKomSigLaenge" SG_ 988 EC_BU_ECUCfg11_Stat 2;
BA_ "FlexKomSID" SG_ 988 EC_BU_ECUCfg11_Stat 1711;
BA_ "FlexKomIsMotorola" SG_ 988 EC_BU_ECUCfg11_Stat 1;
BA_ "FlexKomComment" SG_ 988 EC_BU_ECUCfg11_Stat "Backup for ECU Configuration messages status 11";
BA_ "GenSigSNA" SG_ 988 EC_BU_CBC10A "0h";
BA_ "GenSigSendType" SG_ 988 EC_BU_CBC10A 1;
BA_ "FlexKomSigStartValue" SG_ 988 EC_BU_CBC10A "00000000h";
BA_ "FlexKomSigStartPos" SG_ 988 EC_BU_CBC10A 7;
BA_ "FlexKomSigName" SG_ 988 EC_BU_CBC10A "EC_BU_CBC10";
BA_ "FlexKomSigLaenge" SG_ 988 EC_BU_CBC10A 32;
BA_ "FlexKomSID" SG_ 988 EC_BU_CBC10A 1712;
BA_ "FlexKomIsMotorola" SG_ 988 EC_BU_CBC10A 1;
BA_ "FlexKomComment" SG_ 988 EC_BU_CBC10A "Backup for CBC ecu configuration 10";
BA_ "GenSigSNA" SG_ 988 EC_BU_CBC10B "0h";
BA_ "GenSigSendType" SG_ 988 EC_BU_CBC10B 1;
BA_ "FlexKomSigStartValue" SG_ 988 EC_BU_CBC10B "00000000h";
BA_ "FlexKomSigStartPos" SG_ 988 EC_BU_CBC10B 7;
BA_ "FlexKomSigName" SG_ 988 EC_BU_CBC10B "EC_BU_CBC10";
BA_ "FlexKomSigLaenge" SG_ 988 EC_BU_CBC10B 32;
BA_ "FlexKomSID" SG_ 988 EC_BU_CBC10B 1712;
BA_ "FlexKomIsMotorola" SG_ 988 EC_BU_CBC10B 1;
BA_ "FlexKomComment" SG_ 988 EC_BU_CBC10B "Backup for CBC ecu configuration 10";
BA_ "GenSigSNA" SG_ 988 EC_BU_CBC11 "0h";
BA_ "GenSigSendType" SG_ 988 EC_BU_CBC11 1;
BA_ "FlexKomSigStartValue" SG_ 988 EC_BU_CBC11 "00000000h";
BA_ "FlexKomSigStartPos" SG_ 988 EC_BU_CBC11 39;
BA_ "FlexKomSigName" SG_ 988 EC_BU_CBC11 "EC_BU_CBC11";
BA_ "FlexKomSigLaenge" SG_ 988 EC_BU_CBC11 32;
BA_ "FlexKomSID" SG_ 988 EC_BU_CBC11 1713;
BA_ "FlexKomIsMotorola" SG_ 988 EC_BU_CBC11 1;
BA_ "FlexKomComment" SG_ 988 EC_BU_CBC11 "Backup for CBC ecu configuration 11";
BA_ "GenSigStartValue" SG_ 989 EC_BU_ECUCfg10_Stat 3;
BA_ "GenSigSNA" SG_ 989 EC_BU_ECUCfg10_Stat "3h";
BA_ "GenSigSendType" SG_ 989 EC_BU_ECUCfg10_Stat 1;
BA_ "FlexKomSigStartValue" SG_ 989 EC_BU_ECUCfg10_Stat "03h";
BA_ "FlexKomSigStartPos" SG_ 989 EC_BU_ECUCfg10_Stat 1;
BA_ "FlexKomSigName" SG_ 989 EC_BU_ECUCfg10_Stat "EC_BU_ECUCfg10_Stat";
BA_ "FlexKomSigLaenge" SG_ 989 EC_BU_ECUCfg10_Stat 2;
BA_ "FlexKomSID" SG_ 989 EC_BU_ECUCfg10_Stat 1302;
BA_ "FlexKomIsMotorola" SG_ 989 EC_BU_ECUCfg10_Stat 1;
BA_ "FlexKomComment" SG_ 989 EC_BU_ECUCfg10_Stat "Backup for ECU Configuration messages status 10";
BA_ "GenSigSNA" SG_ 989 EC_BU_Cluster3A "0h";
BA_ "GenSigSendType" SG_ 989 EC_BU_Cluster3A 1;
BA_ "FlexKomSigStartValue" SG_ 989 EC_BU_Cluster3A "00000000h";
BA_ "FlexKomSigStartPos" SG_ 989 EC_BU_Cluster3A 7;
BA_ "FlexKomSigName" SG_ 989 EC_BU_Cluster3A "EC_BU_Cluster3";
BA_ "FlexKomSigLaenge" SG_ 989 EC_BU_Cluster3A 32;
BA_ "FlexKomSID" SG_ 989 EC_BU_Cluster3A 1305;
BA_ "FlexKomIsMotorola" SG_ 989 EC_BU_Cluster3A 1;
BA_ "FlexKomComment" SG_ 989 EC_BU_Cluster3A "Backup for Instrument cluster ecu configuration 3";
BA_ "GenSigSNA" SG_ 989 EC_BU_Cluster3B "0h";
BA_ "GenSigSendType" SG_ 989 EC_BU_Cluster3B 1;
BA_ "FlexKomSigStartValue" SG_ 989 EC_BU_Cluster3B "00000000h";
BA_ "FlexKomSigStartPos" SG_ 989 EC_BU_Cluster3B 7;
BA_ "FlexKomSigName" SG_ 989 EC_BU_Cluster3B "EC_BU_Cluster3";
BA_ "FlexKomSigLaenge" SG_ 989 EC_BU_Cluster3B 32;
BA_ "FlexKomSID" SG_ 989 EC_BU_Cluster3B 1305;
BA_ "FlexKomIsMotorola" SG_ 989 EC_BU_Cluster3B 1;
BA_ "FlexKomComment" SG_ 989 EC_BU_Cluster3B "Backup for Instrument cluster ecu configuration 3";
BA_ "GenSigSNA" SG_ 989 EC_BU_Cluster4 "0h";
BA_ "GenSigSendType" SG_ 989 EC_BU_Cluster4 1;
BA_ "FlexKomSigStartValue" SG_ 989 EC_BU_Cluster4 "00000000h";
BA_ "FlexKomSigStartPos" SG_ 989 EC_BU_Cluster4 39;
BA_ "FlexKomSigName" SG_ 989 EC_BU_Cluster4 "EC_BU_Cluster4";
BA_ "FlexKomSigLaenge" SG_ 989 EC_BU_Cluster4 32;
BA_ "FlexKomSID" SG_ 989 EC_BU_Cluster4 1304;
BA_ "FlexKomIsMotorola" SG_ 989 EC_BU_Cluster4 1;
BA_ "FlexKomComment" SG_ 989 EC_BU_Cluster4 "Backup for Instrument cluster ecu configuration 4";
BA_ "GenSigStartValue" SG_ 991 EC_BU_ECUCfg9_Stat 3;
BA_ "GenSigSNA" SG_ 991 EC_BU_ECUCfg9_Stat "3h";
BA_ "GenSigSendType" SG_ 991 EC_BU_ECUCfg9_Stat 1;
BA_ "FlexKomSigStartValue" SG_ 991 EC_BU_ECUCfg9_Stat "03h";
BA_ "FlexKomSigStartPos" SG_ 991 EC_BU_ECUCfg9_Stat 1;
BA_ "FlexKomSigName" SG_ 991 EC_BU_ECUCfg9_Stat "EC_BU_ECUCfg9_Stat";
BA_ "FlexKomSigLaenge" SG_ 991 EC_BU_ECUCfg9_Stat 2;
BA_ "FlexKomSID" SG_ 991 EC_BU_ECUCfg9_Stat 1216;
BA_ "FlexKomIsMotorola" SG_ 991 EC_BU_ECUCfg9_Stat 1;
BA_ "FlexKomComment" SG_ 991 EC_BU_ECUCfg9_Stat "Backup for ECU Configuration messages status 9";
BA_ "GenSigSNA" SG_ 991 EC_BU_CBC9A1 "0h";
BA_ "GenSigSendType" SG_ 991 EC_BU_CBC9A1 1;
BA_ "FlexKomSigStartValue" SG_ 991 EC_BU_CBC9A1 "00000000h";
BA_ "FlexKomSigStartPos" SG_ 991 EC_BU_CBC9A1 7;
BA_ "FlexKomSigName" SG_ 991 EC_BU_CBC9A1 "EC_BU_CBC9A";
BA_ "FlexKomSigLaenge" SG_ 991 EC_BU_CBC9A1 32;
BA_ "FlexKomSID" SG_ 991 EC_BU_CBC9A1 1419;
BA_ "FlexKomIsMotorola" SG_ 991 EC_BU_CBC9A1 1;
BA_ "FlexKomComment" SG_ 991 EC_BU_CBC9A1 "Backup for CBC configuration 9A";
BA_ "GenSigSNA" SG_ 991 EC_BU_CBC9A2 "0h";
BA_ "GenSigSendType" SG_ 991 EC_BU_CBC9A2 1;
BA_ "FlexKomSigStartValue" SG_ 991 EC_BU_CBC9A2 "00000000h";
BA_ "FlexKomSigStartPos" SG_ 991 EC_BU_CBC9A2 7;
BA_ "FlexKomSigName" SG_ 991 EC_BU_CBC9A2 "EC_BU_CBC9A";
BA_ "FlexKomSigLaenge" SG_ 991 EC_BU_CBC9A2 32;
BA_ "FlexKomSID" SG_ 991 EC_BU_CBC9A2 1419;
BA_ "FlexKomIsMotorola" SG_ 991 EC_BU_CBC9A2 1;
BA_ "FlexKomComment" SG_ 991 EC_BU_CBC9A2 "Backup for CBC configuration 9A";
BA_ "GenSigSNA" SG_ 991 EC_BU_CBC9B "0h";
BA_ "GenSigSendType" SG_ 991 EC_BU_CBC9B 1;
BA_ "FlexKomSigStartValue" SG_ 991 EC_BU_CBC9B "0000h";
BA_ "FlexKomSigStartPos" SG_ 991 EC_BU_CBC9B 39;
BA_ "FlexKomSigName" SG_ 991 EC_BU_CBC9B "EC_BU_CBC9B";
BA_ "FlexKomSigLaenge" SG_ 991 EC_BU_CBC9B 16;
BA_ "FlexKomSID" SG_ 991 EC_BU_CBC9B 1420;
BA_ "FlexKomIsMotorola" SG_ 991 EC_BU_CBC9B 1;
BA_ "FlexKomComment" SG_ 991 EC_BU_CBC9B "Backup for CBC configuration 9B";
BA_ "GenSigSNA" SG_ 991 EC_BU_ITM "0h";
BA_ "GenSigSendType" SG_ 991 EC_BU_ITM 1;
BA_ "FlexKomSigStartValue" SG_ 991 EC_BU_ITM "0000h";
BA_ "FlexKomSigStartPos" SG_ 991 EC_BU_ITM 55;
BA_ "FlexKomSigName" SG_ 991 EC_BU_ITM "EC_BU_ITM";
BA_ "FlexKomSigLaenge" SG_ 991 EC_BU_ITM 16;
BA_ "FlexKomSID" SG_ 991 EC_BU_ITM 1220;
BA_ "FlexKomIsMotorola" SG_ 991 EC_BU_ITM 1;
BA_ "FlexKomComment" SG_ 991 EC_BU_ITM "Backup for ITM ecu configuration";
BA_ "RID" SG_ 992 VIN_DATA "1239";
BA_ "GenSigTimeout_SCCM" SG_ 992 VIN_DATA 1050;
BA_ "GenSigTimeout_ORC" SG_ 992 VIN_DATA 350;
BA_ "GenSigTimeout_OCM" SG_ 992 VIN_DATA 5050;
BA_ "GenSigTimeout_IC" SG_ 992 VIN_DATA 1050;
BA_ "GenSigTimeout_ESM" SG_ 992 VIN_DATA 1050;
BA_ "GenSigTimeout_EHPS" SG_ 992 VIN_DATA 1050;
BA_ "GenSigTimeout_DPDM" SG_ 992 VIN_DATA 5050;
BA_ "GenSigSNA" SG_ 992 VIN_DATA "0h";
BA_ "GenSigCycleTime" SG_ 992 VIN_DATA 100;
BA_ "FlexKomSigStartValue" SG_ 992 VIN_DATA "0300000000000000h";
BA_ "FlexKomSigStartPos" SG_ 992 VIN_DATA 7;
BA_ "FlexKomSigName" SG_ 992 VIN_DATA "VIN_INFO";
BA_ "FlexKomSigLaenge" SG_ 992 VIN_DATA 64;
BA_ "FlexKomSID" SG_ 992 VIN_DATA 430;
BA_ "FlexKomIsMotorola" SG_ 992 VIN_DATA 1;
BA_ "FlexKomComment" SG_ 992 VIN_DATA "Vin Information";
BA_ "RID" SG_ 992 VIN_MSG "1275";
BA_ "GenSigTimeout_SCCM" SG_ 992 VIN_MSG 1050;
BA_ "GenSigTimeout_RF_HUB" SG_ 992 VIN_MSG 1050;
BA_ "GenSigTimeout_ORC" SG_ 992 VIN_MSG 350;
BA_ "GenSigTimeout_OCM" SG_ 992 VIN_MSG 5050;
BA_ "GenSigTimeout_IC" SG_ 992 VIN_MSG 1050;
BA_ "GenSigTimeout_ESM" SG_ 992 VIN_MSG 1050;
BA_ "GenSigTimeout_EHPS" SG_ 992 VIN_MSG 1050;
BA_ "GenSigTimeout_DTCM" SG_ 992 VIN_MSG 1050;
BA_ "GenSigTimeout_DPDM" SG_ 992 VIN_MSG 5050;
BA_ "GenSigStartValue" SG_ 992 VIN_MSG 3;
BA_ "GenSigSNA" SG_ 992 VIN_MSG "3h";
BA_ "GenSigCycleTime" SG_ 992 VIN_MSG 100;
BA_ "FlexKomSigStartValue" SG_ 992 VIN_MSG "0300000000000000h";
BA_ "FlexKomSigStartPos" SG_ 992 VIN_MSG 7;
BA_ "FlexKomSigName" SG_ 992 VIN_MSG "VIN_INFO";
BA_ "FlexKomSigLaenge" SG_ 992 VIN_MSG 64;
BA_ "FlexKomSID" SG_ 992 VIN_MSG 430;
BA_ "FlexKomIsMotorola" SG_ 992 VIN_MSG 1;
BA_ "FlexKomComment" SG_ 992 VIN_MSG "Vin Information";
BA_ "GenSigStartValue" SG_ 993 Manufacture 7;
BA_ "GenSigSNA" SG_ 993 Manufacture "7h";
BA_ "GenSigCycleTime" SG_ 993 Manufacture 100;
BA_ "FlexKomSigStartValue" SG_ 993 Manufacture "FFEFE7E7h";
BA_ "FlexKomSigStartPos" SG_ 993 Manufacture 7;
BA_ "FlexKomSigName" SG_ 993 Manufacture "ENG_CFG";
BA_ "FlexKomSigLaenge" SG_ 993 Manufacture 32;
BA_ "FlexKomSID" SG_ 993 Manufacture 617;
BA_ "FlexKomIsMotorola" SG_ 993 Manufacture 1;
BA_ "FlexKomComment" SG_ 993 Manufacture "Engine Configuration Information";
BA_ "GenSigStartValue" SG_ 993 NUM_VALVE 7;
BA_ "GenSigSNA" SG_ 993 NUM_VALVE "7h";
BA_ "GenSigCycleTime" SG_ 993 NUM_VALVE 100;
BA_ "FlexKomSigStartValue" SG_ 993 NUM_VALVE "FFEFE7E7h";
BA_ "FlexKomSigStartPos" SG_ 993 NUM_VALVE 7;
BA_ "FlexKomSigName" SG_ 993 NUM_VALVE "ENG_CFG";
BA_ "FlexKomSigLaenge" SG_ 993 NUM_VALVE 32;
BA_ "FlexKomSID" SG_ 993 NUM_VALVE 617;
BA_ "FlexKomIsMotorola" SG_ 993 NUM_VALVE 1;
BA_ "FlexKomComment" SG_ 993 NUM_VALVE "Engine Configuration Information";
BA_ "GenSigTimeout_IC" SG_ 993 ETC_PRSNT 1050;
BA_ "GenSigSNA" SG_ 993 ETC_PRSNT "0h";
BA_ "GenSigCycleTime" SG_ 993 ETC_PRSNT 100;
BA_ "FlexKomSigStartValue" SG_ 993 ETC_PRSNT "FFEFE7E7h";
BA_ "FlexKomSigStartPos" SG_ 993 ETC_PRSNT 7;
BA_ "FlexKomSigName" SG_ 993 ETC_PRSNT "ENG_CFG";
BA_ "FlexKomSigLaenge" SG_ 993 ETC_PRSNT 32;
BA_ "FlexKomSID" SG_ 993 ETC_PRSNT 617;
BA_ "FlexKomIsMotorola" SG_ 993 ETC_PRSNT 1;
BA_ "FlexKomComment" SG_ 993 ETC_PRSNT "Engine Configuration Information";
BA_ "RID" SG_ 993 TRANS_TYPE "1094";
BA_ "GenSigTimeout_ORC" SG_ 993 TRANS_TYPE 350;
BA_ "GenSigTimeout_IC" SG_ 993 TRANS_TYPE 1050;
BA_ "GenSigSNA" SG_ 993 TRANS_TYPE "0h";
BA_ "GenSigCycleTime" SG_ 993 TRANS_TYPE 100;
BA_ "FlexKomSigStartValue" SG_ 993 TRANS_TYPE "FFEFE7E7h";
BA_ "FlexKomSigStartPos" SG_ 993 TRANS_TYPE 7;
BA_ "FlexKomSigName" SG_ 993 TRANS_TYPE "ENG_CFG";
BA_ "FlexKomSigLaenge" SG_ 993 TRANS_TYPE 32;
BA_ "FlexKomSID" SG_ 993 TRANS_TYPE 617;
BA_ "FlexKomIsMotorola" SG_ 993 TRANS_TYPE 1;
BA_ "FlexKomComment" SG_ 993 TRANS_TYPE "Engine Configuration Information";
BA_ "RID" SG_ 993 EngStyle "1062";
BA_ "GenSigTimeout_CBC" SG_ 993 EngStyle 1050;
BA_ "GenSigStartValue" SG_ 993 EngStyle 7;
BA_ "GenSigSNA" SG_ 993 EngStyle "7h";
BA_ "GenSigCycleTime" SG_ 993 EngStyle 100;
BA_ "FlexKomSigStartValue" SG_ 993 EngStyle "FFEFE7E7h";
BA_ "FlexKomSigStartPos" SG_ 993 EngStyle 7;
BA_ "FlexKomSigName" SG_ 993 EngStyle "ENG_CFG";
BA_ "FlexKomSigLaenge" SG_ 993 EngStyle 32;
BA_ "FlexKomSID" SG_ 993 EngStyle 617;
BA_ "FlexKomIsMotorola" SG_ 993 EngStyle 1;
BA_ "FlexKomComment" SG_ 993 EngStyle "Engine Configuration Information";
BA_ "GenSigSNA" SG_ 993 A580_DATA "0h";
BA_ "GenSigCycleTime" SG_ 993 A580_DATA 100;
BA_ "FlexKomSigStartValue" SG_ 993 A580_DATA "1F0000h";
BA_ "FlexKomSigStartPos" SG_ 993 A580_DATA 39;
BA_ "FlexKomSigName" SG_ 993 A580_DATA "AVC_CFG";
BA_ "FlexKomSigLaenge" SG_ 993 A580_DATA 24;
BA_ "FlexKomSID" SG_ 993 A580_DATA 1090;
BA_ "FlexKomIsMotorola" SG_ 993 A580_DATA 1;
BA_ "FlexKomComment" SG_ 993 A580_DATA "TCM_EGS AVC Configuration";
BA_ "RID" SG_ 993 DISPLACEMENT "1899";
BA_ "GenSigTimeout_ORC" SG_ 993 DISPLACEMENT 350;
BA_ "GenSigTimeout_IC" SG_ 993 DISPLACEMENT 1050;
BA_ "GenSigTimeout_ETM" SG_ 993 DISPLACEMENT 1050;
BA_ "GenSigTimeout_DTCM" SG_ 993 DISPLACEMENT 1050;
BA_ "GenSigTimeout_CBC" SG_ 993 DISPLACEMENT 1050;
BA_ "GenSigStartValue" SG_ 993 DISPLACEMENT 255;
BA_ "GenSigSNA" SG_ 993 DISPLACEMENT "FFh";
BA_ "GenSigCycleTime" SG_ 993 DISPLACEMENT 100;
BA_ "FlexKomSigStartValue" SG_ 993 DISPLACEMENT "FFEFE7E7h";
BA_ "FlexKomSigStartPos" SG_ 993 DISPLACEMENT 7;
BA_ "FlexKomSigName" SG_ 993 DISPLACEMENT "ENG_CFG";
BA_ "FlexKomSigLaenge" SG_ 993 DISPLACEMENT 32;
BA_ "FlexKomSID" SG_ 993 DISPLACEMENT 617;
BA_ "FlexKomIsMotorola" SG_ 993 DISPLACEMENT 1;
BA_ "FlexKomComment" SG_ 993 DISPLACEMENT "Engine Configuration Information";
BA_ "GenSigStartValue" SG_ 993 NUM_CYL 15;
BA_ "GenSigSNA" SG_ 993 NUM_CYL "Fh";
BA_ "GenSigCycleTime" SG_ 993 NUM_CYL 100;
BA_ "FlexKomSigStartValue" SG_ 993 NUM_CYL "FFEFE7E7h";
BA_ "FlexKomSigStartPos" SG_ 993 NUM_CYL 7;
BA_ "FlexKomSigName" SG_ 993 NUM_CYL "ENG_CFG";
BA_ "FlexKomSigLaenge" SG_ 993 NUM_CYL 32;
BA_ "FlexKomSID" SG_ 993 NUM_CYL 617;
BA_ "FlexKomIsMotorola" SG_ 993 NUM_CYL 1;
BA_ "FlexKomComment" SG_ 993 NUM_CYL "Engine Configuration Information";
BA_ "RID" SG_ 993 SpStPrsnt "1164";
BA_ "GenSigTimeout_ORC" SG_ 993 SpStPrsnt 350;
BA_ "GenSigTimeout_IC" SG_ 993 SpStPrsnt 1050;
BA_ "GenSigSNA" SG_ 993 SpStPrsnt "0h";
BA_ "GenSigCycleTime" SG_ 993 SpStPrsnt 100;
BA_ "FlexKomSigStartValue" SG_ 993 SpStPrsnt "FFEFE7E7h";
BA_ "FlexKomSigStartPos" SG_ 993 SpStPrsnt 7;
BA_ "FlexKomSigName" SG_ 993 SpStPrsnt "ENG_CFG";
BA_ "FlexKomSigLaenge" SG_ 993 SpStPrsnt 32;
BA_ "FlexKomSID" SG_ 993 SpStPrsnt 617;
BA_ "FlexKomIsMotorola" SG_ 993 SpStPrsnt 1;
BA_ "FlexKomComment" SG_ 993 SpStPrsnt "Engine Configuration Information";
BA_ "GenSigTimeout_ETM" SG_ 993 ENG_ASP 1050;
BA_ "GenSigStartValue" SG_ 993 ENG_ASP 7;
BA_ "GenSigSNA" SG_ 993 ENG_ASP "7h";
BA_ "GenSigCycleTime" SG_ 993 ENG_ASP 100;
BA_ "FlexKomSigStartValue" SG_ 993 ENG_ASP "FFEFE7E7h";
BA_ "FlexKomSigStartPos" SG_ 993 ENG_ASP 7;
BA_ "FlexKomSigName" SG_ 993 ENG_ASP "ENG_CFG";
BA_ "FlexKomSigLaenge" SG_ 993 ENG_ASP 32;
BA_ "FlexKomSID" SG_ 993 ENG_ASP 617;
BA_ "FlexKomIsMotorola" SG_ 993 ENG_ASP 1;
BA_ "FlexKomComment" SG_ 993 ENG_ASP "Engine Configuration Information";
BA_ "RID" SG_ 993 FUEL_TYPE "1261";
BA_ "GenSigTimeout_ORC" SG_ 993 FUEL_TYPE 350;
BA_ "GenSigTimeout_IC" SG_ 993 FUEL_TYPE 1050;
BA_ "GenSigTimeout_EHPS" SG_ 993 FUEL_TYPE 1050;
BA_ "GenSigTimeout_CBC" SG_ 993 FUEL_TYPE 1050;
BA_ "GenSigStartValue" SG_ 993 FUEL_TYPE 7;
BA_ "GenSigSNA" SG_ 993 FUEL_TYPE "7h";
BA_ "GenSigCycleTime" SG_ 993 FUEL_TYPE 100;
BA_ "FlexKomSigStartValue" SG_ 993 FUEL_TYPE "FFEFE7E7h";
BA_ "FlexKomSigStartPos" SG_ 993 FUEL_TYPE 7;
BA_ "FlexKomSigName" SG_ 993 FUEL_TYPE "ENG_CFG";
BA_ "FlexKomSigLaenge" SG_ 993 FUEL_TYPE 32;
BA_ "FlexKomSID" SG_ 993 FUEL_TYPE 617;
BA_ "FlexKomIsMotorola" SG_ 993 FUEL_TYPE 1;
BA_ "FlexKomComment" SG_ 993 FUEL_TYPE "Engine Configuration Information";
BA_ "GenSigTimeout_IC" SG_ 993 ECM_Vehi_Type 1050;
BA_ "GenSigSNA" SG_ 993 ECM_Vehi_Type "3h";
BA_ "GenSigCycleTime" SG_ 993 ECM_Vehi_Type 100;
BA_ "FlexKomSigStartValue" SG_ 993 ECM_Vehi_Type "FFEFE7E7h";
BA_ "FlexKomSigStartPos" SG_ 993 ECM_Vehi_Type 7;
BA_ "FlexKomSigName" SG_ 993 ECM_Vehi_Type "ENG_CFG";
BA_ "FlexKomSigLaenge" SG_ 993 ECM_Vehi_Type 32;
BA_ "FlexKomSID" SG_ 993 ECM_Vehi_Type 617;
BA_ "FlexKomIsMotorola" SG_ 993 ECM_Vehi_Type 1;
BA_ "FlexKomComment" SG_ 993 ECM_Vehi_Type "Engine Configuration Information";
BA_ "GenSigTimeout_RF_HUB" SG_ 995 NetCfg_UPFM 21000;
BA_ "GenSigSNA" SG_ 995 NetCfg_UPFM "0h";
BA_ "GenSigSendType" SG_ 995 NetCfg_UPFM 5;
BA_ "GenSigCycleTime" SG_ 995 NetCfg_UPFM 2000;
BA_ "FlexKomSigStartValue" SG_ 995 NetCfg_UPFM "0300000000000000h";
BA_ "FlexKomSigStartPos" SG_ 995 NetCfg_UPFM 7;
BA_ "FlexKomSigName" SG_ 995 NetCfg_UPFM "NET_CFG_DATA_INT";
BA_ "FlexKomSigLaenge" SG_ 995 NetCfg_UPFM 64;
BA_ "FlexKomSID" SG_ 995 NetCfg_UPFM 38;
BA_ "FlexKomIsMotorola" SG_ 995 NetCfg_UPFM 1;
BA_ "FlexKomComment" SG_ 995 NetCfg_UPFM "Network ECU config data for interior";
BA_ "GenSigTimeout_RF_HUB" SG_ 995 NetCfg_TTM 21000;
BA_ "GenSigSNA" SG_ 995 NetCfg_TTM "0h";
BA_ "GenSigSendType" SG_ 995 NetCfg_TTM 5;
BA_ "GenSigCycleTime" SG_ 995 NetCfg_TTM 2000;
BA_ "FlexKomSigStartValue" SG_ 995 NetCfg_TTM "0300000000000000h";
BA_ "FlexKomSigStartPos" SG_ 995 NetCfg_TTM 7;
BA_ "FlexKomSigName" SG_ 995 NetCfg_TTM "NET_CFG_DATA_INT";
BA_ "FlexKomSigLaenge" SG_ 995 NetCfg_TTM 64;
BA_ "FlexKomSID" SG_ 995 NetCfg_TTM 38;
BA_ "FlexKomIsMotorola" SG_ 995 NetCfg_TTM 1;
BA_ "FlexKomComment" SG_ 995 NetCfg_TTM "Network ECU config data for interior";
BA_ "GenSigSNA" SG_ 995 NetCfg_PSSM "0h";
BA_ "GenSigSendType" SG_ 995 NetCfg_PSSM 5;
BA_ "GenSigCycleTime" SG_ 995 NetCfg_PSSM 2000;
BA_ "FlexKomSigStartValue" SG_ 995 NetCfg_PSSM "0300000000000000h";
BA_ "FlexKomSigStartPos" SG_ 995 NetCfg_PSSM 7;
BA_ "FlexKomSigName" SG_ 995 NetCfg_PSSM "NET_CFG_DATA_INT";
BA_ "FlexKomSigLaenge" SG_ 995 NetCfg_PSSM 64;
BA_ "FlexKomSID" SG_ 995 NetCfg_PSSM 38;
BA_ "FlexKomIsMotorola" SG_ 995 NetCfg_PSSM 1;
BA_ "FlexKomComment" SG_ 995 NetCfg_PSSM "Network ECU config data for interior";
BA_ "GenSigTimeout_RF_HUB" SG_ 995 NetCfg_TBM 21000;
BA_ "GenSigSNA" SG_ 995 NetCfg_TBM "0h";
BA_ "GenSigSendType" SG_ 995 NetCfg_TBM 5;
BA_ "GenSigCycleTime" SG_ 995 NetCfg_TBM 2000;
BA_ "FlexKomSigStartValue" SG_ 995 NetCfg_TBM "0300000000000000h";
BA_ "FlexKomSigStartPos" SG_ 995 NetCfg_TBM 7;
BA_ "FlexKomSigName" SG_ 995 NetCfg_TBM "NET_CFG_DATA_INT";
BA_ "FlexKomSigLaenge" SG_ 995 NetCfg_TBM 64;
BA_ "FlexKomSID" SG_ 995 NetCfg_TBM 38;
BA_ "FlexKomIsMotorola" SG_ 995 NetCfg_TBM 1;
BA_ "FlexKomComment" SG_ 995 NetCfg_TBM "Network ECU config data for interior";
BA_ "GenSigTimeout_RF_HUB" SG_ 995 NetCfg_ICS_R 21000;
BA_ "GenSigSNA" SG_ 995 NetCfg_ICS_R "0h";
BA_ "GenSigSendType" SG_ 995 NetCfg_ICS_R 5;
BA_ "GenSigCycleTime" SG_ 995 NetCfg_ICS_R 2000;
BA_ "FlexKomSigStartValue" SG_ 995 NetCfg_ICS_R "0300000000000000h";
BA_ "FlexKomSigStartPos" SG_ 995 NetCfg_ICS_R 7;
BA_ "FlexKomSigName" SG_ 995 NetCfg_ICS_R "NET_CFG_DATA_INT";
BA_ "FlexKomSigLaenge" SG_ 995 NetCfg_ICS_R 64;
BA_ "FlexKomSID" SG_ 995 NetCfg_ICS_R 38;
BA_ "FlexKomIsMotorola" SG_ 995 NetCfg_ICS_R 1;
BA_ "FlexKomComment" SG_ 995 NetCfg_ICS_R "Network ECU config data for interior";
BA_ "GenSigTimeout_RF_HUB" SG_ 995 NetCfg_MSM_PASS 21000;
BA_ "GenSigSNA" SG_ 995 NetCfg_MSM_PASS "0h";
BA_ "GenSigSendType" SG_ 995 NetCfg_MSM_PASS 5;
BA_ "GenSigCycleTime" SG_ 995 NetCfg_MSM_PASS 2000;
BA_ "FlexKomSigStartValue" SG_ 995 NetCfg_MSM_PASS "0300000000000000h";
BA_ "FlexKomSigStartPos" SG_ 995 NetCfg_MSM_PASS 7;
BA_ "FlexKomSigName" SG_ 995 NetCfg_MSM_PASS "NET_CFG_DATA_INT";
BA_ "FlexKomSigLaenge" SG_ 995 NetCfg_MSM_PASS 64;
BA_ "FlexKomSID" SG_ 995 NetCfg_MSM_PASS 38;
BA_ "FlexKomIsMotorola" SG_ 995 NetCfg_MSM_PASS 1;
BA_ "FlexKomComment" SG_ 995 NetCfg_MSM_PASS "Network ECU config data for interior";
BA_ "GenSigTimeout_RF_HUB" SG_ 995 NetCfg_VRM 21000;
BA_ "GenSigSNA" SG_ 995 NetCfg_VRM "0h";
BA_ "GenSigSendType" SG_ 995 NetCfg_VRM 5;
BA_ "GenSigCycleTime" SG_ 995 NetCfg_VRM 2000;
BA_ "FlexKomSigStartValue" SG_ 995 NetCfg_VRM "0300000000000000h";
BA_ "FlexKomSigStartPos" SG_ 995 NetCfg_VRM 7;
BA_ "FlexKomSigName" SG_ 995 NetCfg_VRM "NET_CFG_DATA_INT";
BA_ "FlexKomSigLaenge" SG_ 995 NetCfg_VRM 64;
BA_ "FlexKomSID" SG_ 995 NetCfg_VRM 38;
BA_ "FlexKomIsMotorola" SG_ 995 NetCfg_VRM 1;
BA_ "FlexKomComment" SG_ 995 NetCfg_VRM "Network ECU config data for interior";
BA_ "GenSigTimeout_RF_HUB" SG_ 995 NetCfg_VES2_I 21000;
BA_ "GenSigSNA" SG_ 995 NetCfg_VES2_I "0h";
BA_ "GenSigSendType" SG_ 995 NetCfg_VES2_I 5;
BA_ "GenSigCycleTime" SG_ 995 NetCfg_VES2_I 2000;
BA_ "FlexKomSigStartValue" SG_ 995 NetCfg_VES2_I "0300000000000000h";
BA_ "FlexKomSigStartPos" SG_ 995 NetCfg_VES2_I 7;
BA_ "FlexKomSigName" SG_ 995 NetCfg_VES2_I "NET_CFG_DATA_INT";
BA_ "FlexKomSigLaenge" SG_ 995 NetCfg_VES2_I 64;
BA_ "FlexKomSID" SG_ 995 NetCfg_VES2_I 38;
BA_ "FlexKomIsMotorola" SG_ 995 NetCfg_VES2_I 1;
BA_ "FlexKomComment" SG_ 995 NetCfg_VES2_I "Network ECU config data for interior";
BA_ "GenSigTimeout_RF_HUB" SG_ 995 NetCfg_VES3_I 21000;
BA_ "GenSigSNA" SG_ 995 NetCfg_VES3_I "0h";
BA_ "GenSigSendType" SG_ 995 NetCfg_VES3_I 5;
BA_ "GenSigCycleTime" SG_ 995 NetCfg_VES3_I 2000;
BA_ "FlexKomSigStartValue" SG_ 995 NetCfg_VES3_I "0300000000000000h";
BA_ "FlexKomSigStartPos" SG_ 995 NetCfg_VES3_I 7;
BA_ "FlexKomSigName" SG_ 995 NetCfg_VES3_I "NET_CFG_DATA_INT";
BA_ "FlexKomSigLaenge" SG_ 995 NetCfg_VES3_I 64;
BA_ "FlexKomSID" SG_ 995 NetCfg_VES3_I 38;
BA_ "FlexKomIsMotorola" SG_ 995 NetCfg_VES3_I 1;
BA_ "FlexKomComment" SG_ 995 NetCfg_VES3_I "Network ECU config data for interior";
BA_ "GenSigTimeout_RF_HUB" SG_ 995 NetCfg_CRSM 21000;
BA_ "GenSigSNA" SG_ 995 NetCfg_CRSM "0h";
BA_ "GenSigSendType" SG_ 995 NetCfg_CRSM 5;
BA_ "GenSigCycleTime" SG_ 995 NetCfg_CRSM 2000;
BA_ "FlexKomSigStartValue" SG_ 995 NetCfg_CRSM "0300000000000000h";
BA_ "FlexKomSigStartPos" SG_ 995 NetCfg_CRSM 7;
BA_ "FlexKomSigName" SG_ 995 NetCfg_CRSM "NET_CFG_DATA_INT";
BA_ "FlexKomSigLaenge" SG_ 995 NetCfg_CRSM 64;
BA_ "FlexKomSID" SG_ 995 NetCfg_CRSM 38;
BA_ "FlexKomIsMotorola" SG_ 995 NetCfg_CRSM 1;
BA_ "FlexKomComment" SG_ 995 NetCfg_CRSM "Network ECU config data for interior";
BA_ "GenSigTimeout_RF_HUB" SG_ 995 NetCfg_HVAC_R 21000;
BA_ "GenSigSNA" SG_ 995 NetCfg_HVAC_R "0h";
BA_ "GenSigSendType" SG_ 995 NetCfg_HVAC_R 5;
BA_ "GenSigCycleTime" SG_ 995 NetCfg_HVAC_R 2000;
BA_ "FlexKomSigStartValue" SG_ 995 NetCfg_HVAC_R "0300000000000000h";
BA_ "FlexKomSigStartPos" SG_ 995 NetCfg_HVAC_R 7;
BA_ "FlexKomSigName" SG_ 995 NetCfg_HVAC_R "NET_CFG_DATA_INT";
BA_ "FlexKomSigLaenge" SG_ 995 NetCfg_HVAC_R 64;
BA_ "FlexKomSID" SG_ 995 NetCfg_HVAC_R 38;
BA_ "FlexKomIsMotorola" SG_ 995 NetCfg_HVAC_R 1;
BA_ "FlexKomComment" SG_ 995 NetCfg_HVAC_R "Network ECU config data for interior";
BA_ "GenSigTimeout_RF_HUB" SG_ 995 NetCfg_CVPM 21000;
BA_ "GenSigSNA" SG_ 995 NetCfg_CVPM "0h";
BA_ "GenSigSendType" SG_ 995 NetCfg_CVPM 5;
BA_ "GenSigCycleTime" SG_ 995 NetCfg_CVPM 2000;
BA_ "FlexKomSigStartValue" SG_ 995 NetCfg_CVPM "0300000000000000h";
BA_ "FlexKomSigStartPos" SG_ 995 NetCfg_CVPM 7;
BA_ "FlexKomSigName" SG_ 995 NetCfg_CVPM "NET_CFG_DATA_INT";
BA_ "FlexKomSigLaenge" SG_ 995 NetCfg_CVPM 64;
BA_ "FlexKomSID" SG_ 995 NetCfg_CVPM 38;
BA_ "FlexKomIsMotorola" SG_ 995 NetCfg_CVPM 1;
BA_ "FlexKomComment" SG_ 995 NetCfg_CVPM "Network ECU config data for interior";
BA_ "GenSigTimeout_RF_HUB" SG_ 995 NetCfg_AMP_I 21000;
BA_ "GenSigSNA" SG_ 995 NetCfg_AMP_I "0h";
BA_ "GenSigSendType" SG_ 995 NetCfg_AMP_I 5;
BA_ "GenSigCycleTime" SG_ 995 NetCfg_AMP_I 2000;
BA_ "FlexKomSigStartValue" SG_ 995 NetCfg_AMP_I "0300000000000000h";
BA_ "FlexKomSigStartPos" SG_ 995 NetCfg_AMP_I 7;
BA_ "FlexKomSigName" SG_ 995 NetCfg_AMP_I "NET_CFG_DATA_INT";
BA_ "FlexKomSigLaenge" SG_ 995 NetCfg_AMP_I 64;
BA_ "FlexKomSID" SG_ 995 NetCfg_AMP_I 38;
BA_ "FlexKomIsMotorola" SG_ 995 NetCfg_AMP_I 1;
BA_ "FlexKomComment" SG_ 995 NetCfg_AMP_I "Network ECU config data for interior";
BA_ "GenSigTimeout_RF_HUB" SG_ 995 NetCfg_DVD_CDM 21000;
BA_ "GenSigSNA" SG_ 995 NetCfg_DVD_CDM "0h";
BA_ "GenSigSendType" SG_ 995 NetCfg_DVD_CDM 5;
BA_ "GenSigCycleTime" SG_ 995 NetCfg_DVD_CDM 2000;
BA_ "FlexKomSigStartValue" SG_ 995 NetCfg_DVD_CDM "0300000000000000h";
BA_ "FlexKomSigStartPos" SG_ 995 NetCfg_DVD_CDM 7;
BA_ "FlexKomSigName" SG_ 995 NetCfg_DVD_CDM "NET_CFG_DATA_INT";
BA_ "FlexKomSigLaenge" SG_ 995 NetCfg_DVD_CDM 64;
BA_ "FlexKomSID" SG_ 995 NetCfg_DVD_CDM 38;
BA_ "FlexKomIsMotorola" SG_ 995 NetCfg_DVD_CDM 1;
BA_ "FlexKomComment" SG_ 995 NetCfg_DVD_CDM "Network ECU config data for interior";
BA_ "GenSigTimeout_RF_HUB" SG_ 995 NetCfg_HFM_CTM 21000;
BA_ "GenSigSNA" SG_ 995 NetCfg_HFM_CTM "0h";
BA_ "GenSigSendType" SG_ 995 NetCfg_HFM_CTM 5;
BA_ "GenSigCycleTime" SG_ 995 NetCfg_HFM_CTM 2000;
BA_ "FlexKomSigStartValue" SG_ 995 NetCfg_HFM_CTM "0300000000000000h";
BA_ "FlexKomSigStartPos" SG_ 995 NetCfg_HFM_CTM 7;
BA_ "FlexKomSigName" SG_ 995 NetCfg_HFM_CTM "NET_CFG_DATA_INT";
BA_ "FlexKomSigLaenge" SG_ 995 NetCfg_HFM_CTM 64;
BA_ "FlexKomSID" SG_ 995 NetCfg_HFM_CTM 38;
BA_ "FlexKomIsMotorola" SG_ 995 NetCfg_HFM_CTM 1;
BA_ "FlexKomComment" SG_ 995 NetCfg_HFM_CTM "Network ECU config data for interior";
BA_ "GenSigTimeout_RF_HUB" SG_ 995 NetCfg_RBC 21000;
BA_ "GenSigTimeout_IC" SG_ 995 NetCfg_RBC 21000;
BA_ "GenSigSNA" SG_ 995 NetCfg_RBC "0h";
BA_ "GenSigSendType" SG_ 995 NetCfg_RBC 5;
BA_ "GenSigCycleTime" SG_ 995 NetCfg_RBC 2000;
BA_ "FlexKomSigStartValue" SG_ 995 NetCfg_RBC "0300000000000000h";
BA_ "FlexKomSigStartPos" SG_ 995 NetCfg_RBC 7;
BA_ "FlexKomSigName" SG_ 995 NetCfg_RBC "NET_CFG_DATA_INT";
BA_ "FlexKomSigLaenge" SG_ 995 NetCfg_RBC 64;
BA_ "FlexKomSID" SG_ 995 NetCfg_RBC 38;
BA_ "FlexKomIsMotorola" SG_ 995 NetCfg_RBC 1;
BA_ "FlexKomComment" SG_ 995 NetCfg_RBC "Network ECU config data for interior";
BA_ "GenSigTimeout_RF_HUB" SG_ 995 NetCfg_DTV 21000;
BA_ "GenSigSNA" SG_ 995 NetCfg_DTV "0h";
BA_ "GenSigSendType" SG_ 995 NetCfg_DTV 5;
BA_ "GenSigCycleTime" SG_ 995 NetCfg_DTV 2000;
BA_ "FlexKomSigStartValue" SG_ 995 NetCfg_DTV "0300000000000000h";
BA_ "FlexKomSigStartPos" SG_ 995 NetCfg_DTV 7;
BA_ "FlexKomSigName" SG_ 995 NetCfg_DTV "NET_CFG_DATA_INT";
BA_ "FlexKomSigLaenge" SG_ 995 NetCfg_DTV 64;
BA_ "FlexKomSID" SG_ 995 NetCfg_DTV 38;
BA_ "FlexKomIsMotorola" SG_ 995 NetCfg_DTV 1;
BA_ "FlexKomComment" SG_ 995 NetCfg_DTV "Network ECU config data for interior";
BA_ "GenSigTimeout_RF_HUB" SG_ 995 NetCfg_TGW 21000;
BA_ "GenSigTimeout_IC" SG_ 995 NetCfg_TGW 21000;
BA_ "GenSigSNA" SG_ 995 NetCfg_TGW "0h";
BA_ "GenSigSendType" SG_ 995 NetCfg_TGW 5;
BA_ "GenSigCycleTime" SG_ 995 NetCfg_TGW 2000;
BA_ "FlexKomSigStartValue" SG_ 995 NetCfg_TGW "0300000000000000h";
BA_ "FlexKomSigStartPos" SG_ 995 NetCfg_TGW 7;
BA_ "FlexKomSigName" SG_ 995 NetCfg_TGW "NET_CFG_DATA_INT";
BA_ "FlexKomSigLaenge" SG_ 995 NetCfg_TGW 64;
BA_ "FlexKomSID" SG_ 995 NetCfg_TGW 38;
BA_ "FlexKomIsMotorola" SG_ 995 NetCfg_TGW 1;
BA_ "FlexKomComment" SG_ 995 NetCfg_TGW "Network ECU config data for interior";
BA_ "GenSigTimeout_RF_HUB" SG_ 995 NetCfg_CLOCK 21000;
BA_ "GenSigSNA" SG_ 995 NetCfg_CLOCK "0h";
BA_ "GenSigSendType" SG_ 995 NetCfg_CLOCK 5;
BA_ "GenSigCycleTime" SG_ 995 NetCfg_CLOCK 2000;
BA_ "FlexKomSigStartValue" SG_ 995 NetCfg_CLOCK "0300000000000000h";
BA_ "FlexKomSigStartPos" SG_ 995 NetCfg_CLOCK 7;
BA_ "FlexKomSigName" SG_ 995 NetCfg_CLOCK "NET_CFG_DATA_INT";
BA_ "FlexKomSigLaenge" SG_ 995 NetCfg_CLOCK 64;
BA_ "FlexKomSID" SG_ 995 NetCfg_CLOCK 38;
BA_ "FlexKomIsMotorola" SG_ 995 NetCfg_CLOCK 1;
BA_ "FlexKomComment" SG_ 995 NetCfg_CLOCK "Network ECU config data for interior";
BA_ "GenSigTimeout_RF_HUB" SG_ 995 NetCfg_VSIM 21000;
BA_ "GenSigTimeout_IC" SG_ 995 NetCfg_VSIM 21000;
BA_ "GenSigSNA" SG_ 995 NetCfg_VSIM "0h";
BA_ "GenSigSendType" SG_ 995 NetCfg_VSIM 5;
BA_ "GenSigCycleTime" SG_ 995 NetCfg_VSIM 2000;
BA_ "FlexKomSigStartValue" SG_ 995 NetCfg_VSIM "0300000000000000h";
BA_ "FlexKomSigStartPos" SG_ 995 NetCfg_VSIM 7;
BA_ "FlexKomSigName" SG_ 995 NetCfg_VSIM "NET_CFG_DATA_INT";
BA_ "FlexKomSigLaenge" SG_ 995 NetCfg_VSIM 64;
BA_ "FlexKomSID" SG_ 995 NetCfg_VSIM 38;
BA_ "FlexKomIsMotorola" SG_ 995 NetCfg_VSIM 1;
BA_ "FlexKomComment" SG_ 995 NetCfg_VSIM "Network ECU config data for interior";
BA_ "GenSigSNA" SG_ 995 NetCfg_TGWM "0h";
BA_ "GenSigSendType" SG_ 995 NetCfg_TGWM 5;
BA_ "GenSigCycleTime" SG_ 995 NetCfg_TGWM 2000;
BA_ "FlexKomSigStartValue" SG_ 995 NetCfg_TGWM "0300000000000000h";
BA_ "FlexKomSigStartPos" SG_ 995 NetCfg_TGWM 7;
BA_ "FlexKomSigName" SG_ 995 NetCfg_TGWM "NET_CFG_DATA_INT";
BA_ "FlexKomSigLaenge" SG_ 995 NetCfg_TGWM 64;
BA_ "FlexKomSID" SG_ 995 NetCfg_TGWM 38;
BA_ "FlexKomIsMotorola" SG_ 995 NetCfg_TGWM 1;
BA_ "FlexKomComment" SG_ 995 NetCfg_TGWM "Network ECU config data for interior";
BA_ "GenSigTimeout_RF_HUB" SG_ 995 NetCfg_RBSS 21000;
BA_ "GenSigSNA" SG_ 995 NetCfg_RBSS "0h";
BA_ "GenSigSendType" SG_ 995 NetCfg_RBSS 5;
BA_ "GenSigCycleTime" SG_ 995 NetCfg_RBSS 2000;
BA_ "FlexKomSigStartValue" SG_ 995 NetCfg_RBSS "0300000000000000h";
BA_ "FlexKomSigStartPos" SG_ 995 NetCfg_RBSS 7;
BA_ "FlexKomSigName" SG_ 995 NetCfg_RBSS "NET_CFG_DATA_INT";
BA_ "FlexKomSigLaenge" SG_ 995 NetCfg_RBSS 64;
BA_ "FlexKomSID" SG_ 995 NetCfg_RBSS 38;
BA_ "FlexKomIsMotorola" SG_ 995 NetCfg_RBSS 1;
BA_ "FlexKomComment" SG_ 995 NetCfg_RBSS "Network ECU config data for interior";
BA_ "GenSigTimeout_RF_HUB" SG_ 995 NetCfg_BSM 21000;
BA_ "GenSigTimeout_IC" SG_ 995 NetCfg_BSM 21000;
BA_ "GenSigSNA" SG_ 995 NetCfg_BSM "0h";
BA_ "GenSigSendType" SG_ 995 NetCfg_BSM 5;
BA_ "GenSigCycleTime" SG_ 995 NetCfg_BSM 2000;
BA_ "FlexKomSigStartValue" SG_ 995 NetCfg_BSM "0300000000000000h";
BA_ "FlexKomSigStartPos" SG_ 995 NetCfg_BSM 7;
BA_ "FlexKomSigName" SG_ 995 NetCfg_BSM "NET_CFG_DATA_INT";
BA_ "FlexKomSigLaenge" SG_ 995 NetCfg_BSM 64;
BA_ "FlexKomSID" SG_ 995 NetCfg_BSM 38;
BA_ "FlexKomIsMotorola" SG_ 995 NetCfg_BSM 1;
BA_ "FlexKomComment" SG_ 995 NetCfg_BSM "Network ECU config data for interior";
BA_ "GenSigTimeout_RF_HUB" SG_ 995 NetCfg_CBC_IN 21000;
BA_ "GenSigTimeout_IC" SG_ 995 NetCfg_CBC_IN 21000;
BA_ "GenSigSNA" SG_ 995 NetCfg_CBC_IN "0h";
BA_ "GenSigSendType" SG_ 995 NetCfg_CBC_IN 5;
BA_ "GenSigCycleTime" SG_ 995 NetCfg_CBC_IN 2000;
BA_ "FlexKomSigStartValue" SG_ 995 NetCfg_CBC_IN "0300000000000000h";
BA_ "FlexKomSigStartPos" SG_ 995 NetCfg_CBC_IN 7;
BA_ "FlexKomSigName" SG_ 995 NetCfg_CBC_IN "NET_CFG_DATA_INT";
BA_ "FlexKomSigLaenge" SG_ 995 NetCfg_CBC_IN 64;
BA_ "FlexKomSID" SG_ 995 NetCfg_CBC_IN 38;
BA_ "FlexKomIsMotorola" SG_ 995 NetCfg_CBC_IN 1;
BA_ "FlexKomComment" SG_ 995 NetCfg_CBC_IN "Network ECU config data for interior";
BA_ "GenSigTimeout_RF_HUB" SG_ 995 NetCfg_CSWM 21000;
BA_ "GenSigTimeout_IC" SG_ 995 NetCfg_CSWM 21000;
BA_ "GenSigSNA" SG_ 995 NetCfg_CSWM "0h";
BA_ "GenSigSendType" SG_ 995 NetCfg_CSWM 5;
BA_ "GenSigCycleTime" SG_ 995 NetCfg_CSWM 2000;
BA_ "FlexKomSigStartValue" SG_ 995 NetCfg_CSWM "0300000000000000h";
BA_ "FlexKomSigStartPos" SG_ 995 NetCfg_CSWM 7;
BA_ "FlexKomSigName" SG_ 995 NetCfg_CSWM "NET_CFG_DATA_INT";
BA_ "FlexKomSigLaenge" SG_ 995 NetCfg_CSWM 64;
BA_ "FlexKomSID" SG_ 995 NetCfg_CSWM 38;
BA_ "FlexKomIsMotorola" SG_ 995 NetCfg_CSWM 1;
BA_ "FlexKomComment" SG_ 995 NetCfg_CSWM "Network ECU config data for interior";
BA_ "GenSigTimeout_RF_HUB" SG_ 995 NetCfg_DCM_DR 21000;
BA_ "GenSigTimeout_IC" SG_ 995 NetCfg_DCM_DR 21000;
BA_ "GenSigSNA" SG_ 995 NetCfg_DCM_DR "0h";
BA_ "GenSigSendType" SG_ 995 NetCfg_DCM_DR 5;
BA_ "GenSigCycleTime" SG_ 995 NetCfg_DCM_DR 2000;
BA_ "FlexKomSigStartValue" SG_ 995 NetCfg_DCM_DR "0300000000000000h";
BA_ "FlexKomSigStartPos" SG_ 995 NetCfg_DCM_DR 7;
BA_ "FlexKomSigName" SG_ 995 NetCfg_DCM_DR "NET_CFG_DATA_INT";
BA_ "FlexKomSigLaenge" SG_ 995 NetCfg_DCM_DR 64;
BA_ "FlexKomSID" SG_ 995 NetCfg_DCM_DR 38;
BA_ "FlexKomIsMotorola" SG_ 995 NetCfg_DCM_DR 1;
BA_ "FlexKomComment" SG_ 995 NetCfg_DCM_DR "Network ECU config data for interior";
BA_ "GenSigTimeout_RF_HUB" SG_ 995 NetCfg_DCM_PASS 21000;
BA_ "GenSigTimeout_IC" SG_ 995 NetCfg_DCM_PASS 21000;
BA_ "GenSigSNA" SG_ 995 NetCfg_DCM_PASS "0h";
BA_ "GenSigSendType" SG_ 995 NetCfg_DCM_PASS 5;
BA_ "GenSigCycleTime" SG_ 995 NetCfg_DCM_PASS 2000;
BA_ "FlexKomSigStartValue" SG_ 995 NetCfg_DCM_PASS "0300000000000000h";
BA_ "FlexKomSigStartPos" SG_ 995 NetCfg_DCM_PASS 7;
BA_ "FlexKomSigName" SG_ 995 NetCfg_DCM_PASS "NET_CFG_DATA_INT";
BA_ "FlexKomSigLaenge" SG_ 995 NetCfg_DCM_PASS 64;
BA_ "FlexKomSID" SG_ 995 NetCfg_DCM_PASS 38;
BA_ "FlexKomIsMotorola" SG_ 995 NetCfg_DCM_PASS 1;
BA_ "FlexKomComment" SG_ 995 NetCfg_DCM_PASS "Network ECU config data for interior";
BA_ "GenSigTimeout_RF_HUB" SG_ 995 NetCfg_DCM_RL 21000;
BA_ "GenSigTimeout_IC" SG_ 995 NetCfg_DCM_RL 21000;
BA_ "GenSigSNA" SG_ 995 NetCfg_DCM_RL "0h";
BA_ "GenSigSendType" SG_ 995 NetCfg_DCM_RL 5;
BA_ "GenSigCycleTime" SG_ 995 NetCfg_DCM_RL 2000;
BA_ "FlexKomSigStartValue" SG_ 995 NetCfg_DCM_RL "0300000000000000h";
BA_ "FlexKomSigStartPos" SG_ 995 NetCfg_DCM_RL 7;
BA_ "FlexKomSigName" SG_ 995 NetCfg_DCM_RL "NET_CFG_DATA_INT";
BA_ "FlexKomSigLaenge" SG_ 995 NetCfg_DCM_RL 64;
BA_ "FlexKomSID" SG_ 995 NetCfg_DCM_RL 38;
BA_ "FlexKomIsMotorola" SG_ 995 NetCfg_DCM_RL 1;
BA_ "FlexKomComment" SG_ 995 NetCfg_DCM_RL "Network ECU config data for interior";
BA_ "GenSigTimeout_RF_HUB" SG_ 995 NetCfg_FSM 21000;
BA_ "GenSigTimeout_IC" SG_ 995 NetCfg_FSM 21000;
BA_ "GenSigSNA" SG_ 995 NetCfg_FSM "0h";
BA_ "GenSigSendType" SG_ 995 NetCfg_FSM 5;
BA_ "GenSigCycleTime" SG_ 995 NetCfg_FSM 2000;
BA_ "FlexKomSigStartValue" SG_ 995 NetCfg_FSM "0300000000000000h";
BA_ "FlexKomSigStartPos" SG_ 995 NetCfg_FSM 7;
BA_ "FlexKomSigName" SG_ 995 NetCfg_FSM "NET_CFG_DATA_INT";
BA_ "FlexKomSigLaenge" SG_ 995 NetCfg_FSM 64;
BA_ "FlexKomSID" SG_ 995 NetCfg_FSM 38;
BA_ "FlexKomIsMotorola" SG_ 995 NetCfg_FSM 1;
BA_ "FlexKomComment" SG_ 995 NetCfg_FSM "Network ECU config data for interior";
BA_ "GenSigTimeout_RF_HUB" SG_ 995 NET_CFG_STAT_INT 21000;
BA_ "GenSigTimeout_IC" SG_ 995 NET_CFG_STAT_INT 21000;
BA_ "GenSigStartValue" SG_ 995 NET_CFG_STAT_INT 3;
BA_ "GenSigSNA" SG_ 995 NET_CFG_STAT_INT "3h";
BA_ "GenSigSendType" SG_ 995 NET_CFG_STAT_INT 5;
BA_ "GenSigCycleTime" SG_ 995 NET_CFG_STAT_INT 2000;
BA_ "FlexKomSigStartValue" SG_ 995 NET_CFG_STAT_INT "0300000000000000h";
BA_ "FlexKomSigStartPos" SG_ 995 NET_CFG_STAT_INT 7;
BA_ "FlexKomSigName" SG_ 995 NET_CFG_STAT_INT "NET_CFG_DATA_INT";
BA_ "FlexKomSigLaenge" SG_ 995 NET_CFG_STAT_INT 64;
BA_ "FlexKomSID" SG_ 995 NET_CFG_STAT_INT 38;
BA_ "FlexKomIsMotorola" SG_ 995 NET_CFG_STAT_INT 1;
BA_ "FlexKomComment" SG_ 995 NET_CFG_STAT_INT "Network ECU config data for interior";
BA_ "GenSigTimeout_RF_HUB" SG_ 995 NetCfg_HVAC 21000;
BA_ "GenSigTimeout_IC" SG_ 995 NetCfg_HVAC 21000;
BA_ "GenSigSNA" SG_ 995 NetCfg_HVAC "0h";
BA_ "GenSigSendType" SG_ 995 NetCfg_HVAC 5;
BA_ "GenSigCycleTime" SG_ 995 NetCfg_HVAC 2000;
BA_ "FlexKomSigStartValue" SG_ 995 NetCfg_HVAC "0300000000000000h";
BA_ "FlexKomSigStartPos" SG_ 995 NetCfg_HVAC 7;
BA_ "FlexKomSigName" SG_ 995 NetCfg_HVAC "NET_CFG_DATA_INT";
BA_ "FlexKomSigLaenge" SG_ 995 NetCfg_HVAC 64;
BA_ "FlexKomSID" SG_ 995 NetCfg_HVAC 38;
BA_ "FlexKomIsMotorola" SG_ 995 NetCfg_HVAC 1;
BA_ "FlexKomComment" SG_ 995 NetCfg_HVAC "Network ECU config data for interior";
BA_ "GenSigTimeout_RF_HUB" SG_ 995 NetCfg_MSM 21000;
BA_ "GenSigTimeout_IC" SG_ 995 NetCfg_MSM 21000;
BA_ "GenSigSNA" SG_ 995 NetCfg_MSM "0h";
BA_ "GenSigSendType" SG_ 995 NetCfg_MSM 5;
BA_ "GenSigCycleTime" SG_ 995 NetCfg_MSM 2000;
BA_ "FlexKomSigStartValue" SG_ 995 NetCfg_MSM "0300000000000000h";
BA_ "FlexKomSigStartPos" SG_ 995 NetCfg_MSM 7;
BA_ "FlexKomSigName" SG_ 995 NetCfg_MSM "NET_CFG_DATA_INT";
BA_ "FlexKomSigLaenge" SG_ 995 NetCfg_MSM 64;
BA_ "FlexKomSID" SG_ 995 NetCfg_MSM 38;
BA_ "FlexKomIsMotorola" SG_ 995 NetCfg_MSM 1;
BA_ "FlexKomComment" SG_ 995 NetCfg_MSM "Network ECU config data for interior";
BA_ "GenSigTimeout_RF_HUB" SG_ 995 NetCfg_PLG 21000;
BA_ "GenSigTimeout_IC" SG_ 995 NetCfg_PLG 21000;
BA_ "GenSigSNA" SG_ 995 NetCfg_PLG "0h";
BA_ "GenSigSendType" SG_ 995 NetCfg_PLG 5;
BA_ "GenSigCycleTime" SG_ 995 NetCfg_PLG 2000;
BA_ "FlexKomSigStartValue" SG_ 995 NetCfg_PLG "0300000000000000h";
BA_ "FlexKomSigStartPos" SG_ 995 NetCfg_PLG 7;
BA_ "FlexKomSigName" SG_ 995 NetCfg_PLG "NET_CFG_DATA_INT";
BA_ "FlexKomSigLaenge" SG_ 995 NetCfg_PLG 64;
BA_ "FlexKomSID" SG_ 995 NetCfg_PLG 38;
BA_ "FlexKomIsMotorola" SG_ 995 NetCfg_PLG 1;
BA_ "FlexKomComment" SG_ 995 NetCfg_PLG "Network ECU config data for interior";
BA_ "GenSigTimeout_RF_HUB" SG_ 995 NetCfg_VTM 21000;
BA_ "GenSigSNA" SG_ 995 NetCfg_VTM "0h";
BA_ "GenSigSendType" SG_ 995 NetCfg_VTM 5;
BA_ "GenSigCycleTime" SG_ 995 NetCfg_VTM 2000;
BA_ "FlexKomSigStartValue" SG_ 995 NetCfg_VTM "0300000000000000h";
BA_ "FlexKomSigStartPos" SG_ 995 NetCfg_VTM 7;
BA_ "FlexKomSigName" SG_ 995 NetCfg_VTM "NET_CFG_DATA_INT";
BA_ "FlexKomSigLaenge" SG_ 995 NetCfg_VTM 64;
BA_ "FlexKomSID" SG_ 995 NetCfg_VTM 38;
BA_ "FlexKomIsMotorola" SG_ 995 NetCfg_VTM 1;
BA_ "FlexKomComment" SG_ 995 NetCfg_VTM "Network ECU config data for interior";
BA_ "GenSigTimeout_RF_HUB" SG_ 995 NetCfg_PSD_LT 21000;
BA_ "GenSigTimeout_IC" SG_ 995 NetCfg_PSD_LT 21000;
BA_ "GenSigSNA" SG_ 995 NetCfg_PSD_LT "0h";
BA_ "GenSigSendType" SG_ 995 NetCfg_PSD_LT 5;
BA_ "GenSigCycleTime" SG_ 995 NetCfg_PSD_LT 2000;
BA_ "FlexKomSigStartValue" SG_ 995 NetCfg_PSD_LT "0300000000000000h";
BA_ "FlexKomSigStartPos" SG_ 995 NetCfg_PSD_LT 7;
BA_ "FlexKomSigName" SG_ 995 NetCfg_PSD_LT "NET_CFG_DATA_INT";
BA_ "FlexKomSigLaenge" SG_ 995 NetCfg_PSD_LT 64;
BA_ "FlexKomSID" SG_ 995 NetCfg_PSD_LT 38;
BA_ "FlexKomIsMotorola" SG_ 995 NetCfg_PSD_LT 1;
BA_ "FlexKomComment" SG_ 995 NetCfg_PSD_LT "Network ECU config data for interior";
BA_ "GenSigTimeout_RF_HUB" SG_ 995 NetCfg_DCM_RR 21000;
BA_ "GenSigTimeout_IC" SG_ 995 NetCfg_DCM_RR 21000;
BA_ "GenSigSNA" SG_ 995 NetCfg_DCM_RR "0h";
BA_ "GenSigSendType" SG_ 995 NetCfg_DCM_RR 5;
BA_ "GenSigCycleTime" SG_ 995 NetCfg_DCM_RR 2000;
BA_ "FlexKomSigStartValue" SG_ 995 NetCfg_DCM_RR "0300000000000000h";
BA_ "FlexKomSigStartPos" SG_ 995 NetCfg_DCM_RR 7;
BA_ "FlexKomSigName" SG_ 995 NetCfg_DCM_RR "NET_CFG_DATA_INT";
BA_ "FlexKomSigLaenge" SG_ 995 NetCfg_DCM_RR 64;
BA_ "FlexKomSID" SG_ 995 NetCfg_DCM_RR 38;
BA_ "FlexKomIsMotorola" SG_ 995 NetCfg_DCM_RR 1;
BA_ "FlexKomComment" SG_ 995 NetCfg_DCM_RR "Network ECU config data for interior";
BA_ "GenSigTimeout_RF_HUB" SG_ 995 NetCfg_PSD_RT 21000;
BA_ "GenSigTimeout_IC" SG_ 995 NetCfg_PSD_RT 21000;
BA_ "GenSigSNA" SG_ 995 NetCfg_PSD_RT "0h";
BA_ "GenSigSendType" SG_ 995 NetCfg_PSD_RT 5;
BA_ "GenSigCycleTime" SG_ 995 NetCfg_PSD_RT 2000;
BA_ "FlexKomSigStartValue" SG_ 995 NetCfg_PSD_RT "0300000000000000h";
BA_ "FlexKomSigStartPos" SG_ 995 NetCfg_PSD_RT 7;
BA_ "FlexKomSigName" SG_ 995 NetCfg_PSD_RT "NET_CFG_DATA_INT";
BA_ "FlexKomSigLaenge" SG_ 995 NetCfg_PSD_RT 64;
BA_ "FlexKomSID" SG_ 995 NetCfg_PSD_RT 38;
BA_ "FlexKomIsMotorola" SG_ 995 NetCfg_PSD_RT 1;
BA_ "FlexKomComment" SG_ 995 NetCfg_PSD_RT "Network ECU config data for interior";
BA_ "GenSigTimeout_RF_HUB" SG_ 995 NetCfg_PTCM 21000;
BA_ "GenSigTimeout_IC" SG_ 995 NetCfg_PTCM 21000;
BA_ "GenSigSNA" SG_ 995 NetCfg_PTCM "0h";
BA_ "GenSigSendType" SG_ 995 NetCfg_PTCM 5;
BA_ "GenSigCycleTime" SG_ 995 NetCfg_PTCM 2000;
BA_ "FlexKomSigStartValue" SG_ 995 NetCfg_PTCM "0300000000000000h";
BA_ "FlexKomSigStartPos" SG_ 995 NetCfg_PTCM 7;
BA_ "FlexKomSigName" SG_ 995 NetCfg_PTCM "NET_CFG_DATA_INT";
BA_ "FlexKomSigLaenge" SG_ 995 NetCfg_PTCM 64;
BA_ "FlexKomSID" SG_ 995 NetCfg_PTCM 38;
BA_ "FlexKomIsMotorola" SG_ 995 NetCfg_PTCM 1;
BA_ "FlexKomComment" SG_ 995 NetCfg_PTCM "Network ECU config data for interior";
BA_ "GenSigTimeout_RF_HUB" SG_ 995 NetCfg_ITM 21000;
BA_ "GenSigTimeout_IC" SG_ 995 NetCfg_ITM 21000;
BA_ "GenSigSNA" SG_ 995 NetCfg_ITM "0h";
BA_ "GenSigSendType" SG_ 995 NetCfg_ITM 5;
BA_ "GenSigCycleTime" SG_ 995 NetCfg_ITM 2000;
BA_ "FlexKomSigStartValue" SG_ 995 NetCfg_ITM "0300000000000000h";
BA_ "FlexKomSigStartPos" SG_ 995 NetCfg_ITM 7;
BA_ "FlexKomSigName" SG_ 995 NetCfg_ITM "NET_CFG_DATA_INT";
BA_ "FlexKomSigLaenge" SG_ 995 NetCfg_ITM 64;
BA_ "FlexKomSID" SG_ 995 NetCfg_ITM 38;
BA_ "FlexKomIsMotorola" SG_ 995 NetCfg_ITM 1;
BA_ "FlexKomComment" SG_ 995 NetCfg_ITM "Network ECU config data for interior";
BA_ "GenSigTimeout_RF_HUB" SG_ 995 NetCfg_ICS_I 21000;
BA_ "GenSigSNA" SG_ 995 NetCfg_ICS_I "0h";
BA_ "GenSigSendType" SG_ 995 NetCfg_ICS_I 5;
BA_ "GenSigCycleTime" SG_ 995 NetCfg_ICS_I 2000;
BA_ "FlexKomSigStartValue" SG_ 995 NetCfg_ICS_I "0300000000000000h";
BA_ "FlexKomSigStartPos" SG_ 995 NetCfg_ICS_I 7;
BA_ "FlexKomSigName" SG_ 995 NetCfg_ICS_I "NET_CFG_DATA_INT";
BA_ "FlexKomSigLaenge" SG_ 995 NetCfg_ICS_I 64;
BA_ "FlexKomSID" SG_ 995 NetCfg_ICS_I 38;
BA_ "FlexKomIsMotorola" SG_ 995 NetCfg_ICS_I 1;
BA_ "FlexKomComment" SG_ 995 NetCfg_ICS_I "Network ECU config data for interior";
BA_ "GenSigTimeout_RF_HUB" SG_ 995 NetCfg_TMM 21000;
BA_ "GenSigSNA" SG_ 995 NetCfg_TMM "0h";
BA_ "GenSigSendType" SG_ 995 NetCfg_TMM 5;
BA_ "GenSigCycleTime" SG_ 995 NetCfg_TMM 2000;
BA_ "FlexKomSigStartValue" SG_ 995 NetCfg_TMM "0300000000000000h";
BA_ "FlexKomSigStartPos" SG_ 995 NetCfg_TMM 7;
BA_ "FlexKomSigName" SG_ 995 NetCfg_TMM "NET_CFG_DATA_INT";
BA_ "FlexKomSigLaenge" SG_ 995 NetCfg_TMM 64;
BA_ "FlexKomSID" SG_ 995 NetCfg_TMM 38;
BA_ "FlexKomIsMotorola" SG_ 995 NetCfg_TMM 1;
BA_ "FlexKomComment" SG_ 995 NetCfg_TMM "Network ECU config data for interior";
BA_ "GenSigTimeout_RF_HUB" SG_ 995 NetCfg_DCSD 21000;
BA_ "GenSigSNA" SG_ 995 NetCfg_DCSD "0h";
BA_ "GenSigSendType" SG_ 995 NetCfg_DCSD 5;
BA_ "GenSigCycleTime" SG_ 995 NetCfg_DCSD 2000;
BA_ "FlexKomSigStartValue" SG_ 995 NetCfg_DCSD "0300000000000000h";
BA_ "FlexKomSigStartPos" SG_ 995 NetCfg_DCSD 7;
BA_ "FlexKomSigName" SG_ 995 NetCfg_DCSD "NET_CFG_DATA_INT";
BA_ "FlexKomSigLaenge" SG_ 995 NetCfg_DCSD 64;
BA_ "FlexKomSID" SG_ 995 NetCfg_DCSD 38;
BA_ "FlexKomIsMotorola" SG_ 995 NetCfg_DCSD 1;
BA_ "FlexKomComment" SG_ 995 NetCfg_DCSD "Network ECU config data for interior";
BA_ "GenSigTimeout_RF_HUB" SG_ 995 NetCfg_ANC_I 21000;
BA_ "GenSigSNA" SG_ 995 NetCfg_ANC_I "0h";
BA_ "GenSigSendType" SG_ 995 NetCfg_ANC_I 5;
BA_ "GenSigCycleTime" SG_ 995 NetCfg_ANC_I 2000;
BA_ "FlexKomSigStartValue" SG_ 995 NetCfg_ANC_I "0300000000000000h";
BA_ "FlexKomSigStartPos" SG_ 995 NetCfg_ANC_I 7;
BA_ "FlexKomSigName" SG_ 995 NetCfg_ANC_I "NET_CFG_DATA_INT";
BA_ "FlexKomSigLaenge" SG_ 995 NetCfg_ANC_I 64;
BA_ "FlexKomSID" SG_ 995 NetCfg_ANC_I 38;
BA_ "FlexKomIsMotorola" SG_ 995 NetCfg_ANC_I 1;
BA_ "FlexKomComment" SG_ 995 NetCfg_ANC_I "Network ECU config data for interior";
VAL_ 956 NAV_GrpTyp 0 "NO_TEXT" 63 "SNA" ;
VAL_ 958 Electric_Dist_Miles 1023 "SNA" ;
VAL_ 958 Hybrid_Dist_Miles 1023 "SNA" ;
VAL_ 959 Electric_Dist_Kilometers 1023 "SNA" ;
VAL_ 959 Hybrid_Dist_Kilometers 1023 "SNA" ;
VAL_ 962 VC_FOA_Type 0 "Absent" 1 "Type1" 2 "Type2" 3 "Type3" ;
VAL_ 962 VC_CHMSL_DYN_CNTR_CSO 0 "Absent" 1 "Present" ;
VAL_ 962 VC_VehCfgCSO3_Stat 0 "NA" 1 "PROGAMMED" 2 "REQUEST_DATA" 3 "SNA" ;
VAL_ 962 VC_PEB_CSO 0 "Absent" 1 "Present" ;
VAL_ 962 VC_ESAVE_CSO 0 "Absent" 1 "Present" ;
VAL_ 962 VC_ESAVE_BATT_LVL_CSO 0 "Absent" 1 "Present" ;
VAL_ 962 VC_AL_OR_PLUS_CSO 0 "Absent" 1 "Present" ;
VAL_ 963 VC_BU_FOA_Type 0 "Absent" 1 "Type1" 2 "Type2" 3 "Type3" ;
VAL_ 963 VC_BU_CHMSL_DYN_CNTR_CSO 0 "Absent" 1 "Present" ;
VAL_ 963 VC_BU_ESAVE_CSO 0 "Absent" 1 "Present" ;
VAL_ 963 VC_BU_ESAVE_BATT_LVL_CSO 0 "Absent" 1 "Present" ;
VAL_ 963 VC_BU_VehCfgCSO3_Stat 0 "NA" 1 "PROGAMMED" 2 "REQUEST_DATA" 3 "SNA" ;
VAL_ 963 VC_BU_PEB_CSO 0 "Absent" 1 "Present" ;
VAL_ 963 VC_BU_AL_OR_PLUS_CSO 0 "Absent" 1 "Present" ;
VAL_ 965 FusedSpeedLimit 0 "Unknown" 1 "Less_Equal_5kmh" 2 "7_kmh_mph" 3 "10_kmh_mph" 4 "15_kmh_mph" 5 "20_kmh_mph" 6 "25_kmh_mph" 7 "30_kmh_mph" 8 "35_kmh_mph" 9 "40_kmh_mph" 10 "45_kmh_mph" 11 "50_kmh_mph" 12 "55_kmh_mph" 13 "60_kmh_mph" 14 "65_kmh_mph" 15 "70_kmh_mph" 16 "75_kmh_mph" 17 "80_kmh_mph" 18 "85_kmh_mph" 19 "90_kmh_mph" 20 "95_kmh_mph" 21 "100_kmh_mph" 22 "105_kmh_mph" 23 "110_kmh_mph" 24 "115_kmh_mph" 25 "120_kmh_mph" 26 "130_kmh_mph" 27 "140_kmh_mph" 28 "150_kmh_mph" 29 "160_kmh_mph" 30 "Unlimited" 31 "Invalid" ;
VAL_ 965 SupplementarySignSpeed 0 "Unknown" 1 "Less_Equal_5kmh" 2 "7_kmh_mph" 3 "10_kmh_mph" 4 "15_kmh_mph" 5 "20_kmh_mph" 6 "25_kmh_mph" 7 "30_kmh_mph" 8 "35_kmh_mph" 9 "40_kmh_mph" 10 "45_kmh_mph" 11 "50_kmh_mph" 12 "55_kmh_mph" 13 "60_kmh_mph" 14 "65_kmh_mph" 15 "70_kmh_mph" 16 "75_kmh_mph" 17 "80_kmh_mph" 18 "85_kmh_mph" 19 "90_kmh_mph" 20 "95_kmh_mph" 21 "100_kmh_mph" 22 "105_kmh_mph" 23 "110_kmh_mph" 24 "115_kmh_mph" 25 "120_kmh_mph" 26 "130_kmh_mph" 27 "140_kmh_mph" 28 "150_kmh_mph" 29 "160_kmh_mph" 30 "Unlimited" 31 "Invalid" ;
VAL_ 965 SourceFusedSpeedLimit 0 "None" 1 "Camera" 2 "Map" 3 "Camera_and_Map" ;
VAL_ 965 SpdUnits_CAM 0 "km_h" 1 "mph" ;
VAL_ 965 SupplementarySign 0 "None" 1 "Rain" 2 "Snow" 3 "Trailer" 4 "Time" 5 "Arrow_left" 6 "Arrow_right" 7 "Bend_arrow_left" 8 "Bend_arrow_right" 9 "Truck" 10 "Distance_arrow" 11 "Weight" 12 "Distance_in" 13 "Tractor" 14 "Snow_rain" 15 "School" 16 "Rain_cloud" 17 "Fog" 18 "Hazardous_materials" 19 "Night" 20 "Generic" 21 "Rappel" 22 "Zone" 23 "Ramp" 24 "Expressway" 25 "End_of_expressway" 26 "Motorway" 27 "End_of_motorway" 28 "Residential_area" 29 "End_of_residential_area" 30 "Built_up_area" 31 "End_of_built_up_area_1" 32 "End_of_built_up_area_2" 33 "End_of_all" 34 "End_of_speed_limit" 35 "Unknown" 36 "Invalid" 255 "SNA" ;
VAL_ 965 OvertakingSign 0 "None" 1 "No_Overtaking_US" 2 "No_Overtaking_Canada" 3 "No_Overtaking_Ireland" 4 "No_Overtaking_China" 5 "No_Overtaking_Korea" 6 "No_Overtaking_Japan" 7 "No_Overtaking_UK" 8 "No_Overtaking_Row" 9 "No_Overtaking_for_truck" 10 "End_of_no_overtaking" 11 "End_of_no_overtaking_for_truck" 12 "Unknown" 13 "Invalid" 14 "TBD" 15 "SNA" ;
VAL_ 965 Speed_Sign_Shape 0 "Not_Detected" 1 "Shape_1_Square" 2 "Shape_2_Round" 3 "TBD" ;
VAL_ 965 CAM_Fault_Status 0 "OFF" 1 "Working_Correctly" 2 "Partial_blockage" 3 "Full_blockage" 4 "Fault" ;
VAL_ 967 DrvSeatDPSts 0 "Unoccupied" 1 "Occupied" 2 "Undetermined" 3 "SNA" ;
VAL_ 967 DrvSeatDPFaultSts 0 "NO_FAULT" 1 "FAULTED" ;
VAL_ 969 AMB_TEMP_AVG_F 255 "SNA" ;
VAL_ 969 AMB_TEMP_AVG_C 255 "SNA" ;
VAL_ 973 EPB_WARN_STAT 0 "OFF" 1 "CONT" 2 "BLINK" 3 "SNA" ;
VAL_ 973 CATALYST_TEMP_STAT 0 "OFF" 1 "CONT" 2 "BLINK" 3 "SNA" ;
VAL_ 973 FUEL_CAP_STAT 0 "OFF" 1 "CONT" 2 "BLINK" 3 "SNA" ;
VAL_ 973 WINDSHIELD_FLUID_STAT 0 "OFF" 1 "CONT" 2 "BLINK" 3 "SNA" ;
VAL_ 973 COOLENT_LEVEL_STAT 0 "OFF" 1 "CONT" 2 "BLINK" 3 "SNA" ;
VAL_ 973 OIL_LEVEL_STAT 0 "OFF" 1 "CONT" 2 "BLINK" 3 "SNA" ;
VAL_ 973 ELECTRIC_WRENCH_STAT 0 "OFF" 1 "CONT" 2 "BLINK" 3 "SNA" ;
VAL_ 973 ENGINE_TEMP_STAT 0 "OFF" 1 "CONT" 2 "BLINK" 3 "SNA" ;
VAL_ 973 BATTERY_CHARGE_STAT 0 "OFF" 1 "CONT" 2 "BLINK" 3 "SNA" ;
VAL_ 973 OIL_PRESSURE_STAT 0 "OFF" 1 "CONT" 2 "BLINK" 3 "SNA" ;
VAL_ 973 BRK_IND_STAT 0 "OFF" 1 "CONT" 2 "BLINK" 3 "SNA" ;
VAL_ 973 ABS_IND_STAT 0 "OFF" 1 "CONT" 2 "BLINK" 3 "SNA" ;
VAL_ 973 ENGINE_MIL_STAT 0 "OFF" 1 "CONT" 2 "BLINK" 3 "SNA" ;
VAL_ 973 TIRE_PRESSURE_STAT 0 "OFF" 1 "CONT" 2 "BLINK" 3 "SNA" ;
VAL_ 973 ETC_CONTROL_STAT 0 "OFF" 1 "CONT" 2 "BLINK" 3 "SNA" ;
VAL_ 973 ELEC_STAB_STAT 0 "OFF" 1 "CONT" 2 "BLINK" 3 "SNA" ;
VAL_ 973 OVER_TEMP_STAT 0 "OFF" 1 "CONT" 2 "BLINK" 3 "SNA" ;
VAL_ 973 STOP_START_STAT 0 "OFF" 1 "CONT" 2 "BLINK" 3 "SNA" ;
VAL_ 973 EPS_STAT 0 "OFF" 1 "CONT" 2 "BLINK" 3 "SNA" ;
VAL_ 973 FCW_SYSTEM_STAT 0 "OFF" 1 "CONT" 2 "BLINK" 3 "SNA" ;
VAL_ 973 SERVICE_ACC_STAT 0 "OFF" 1 "CONT" 2 "BLINK" 3 "SNA" ;
VAL_ 973 WATER_IN_FUEL_STAT 0 "OFF" 1 "CONT" 2 "BLINK" 3 "SNA" ;
VAL_ 973 TORQUE_STAT 0 "OFF" 1 "CONT" 2 "BLINK" 3 "SNA" ;
VAL_ 973 DEF_STAT 0 "OFF" 1 "CONT" 2 "BLINK" 3 "SNA" ;
VAL_ 973 OIL_TEMP_STAT 0 "OFF" 1 "CONT" 2 "BLINK" 3 "SNA" ;
VAL_ 973 SERVICE_STAT 0 "OFF" 1 "CONT" 2 "BLINK" 3 "SNA" ;
VAL_ 973 DAMPING_SYSTEM_STAT 0 "OFF" 1 "CONT" 2 "BLINK" 3 "SNA" ;
VAL_ 973 BRAKE_PAD_STAT 0 "OFF" 1 "CONT" 2 "BLINK" 3 "SNA" ;
VAL_ 973 FOUR_WD_SERVICE_STAT 0 "OFF" 1 "CONT" 2 "BLINK" 3 "SNA" ;
VAL_ 973 LANE_SENSE_STAT 0 "OFF" 1 "CONT" 2 "BLINK" 3 "SNA" ;
VAL_ 973 AWD_SERVICE_STAT 0 "OFF" 1 "CONT" 2 "BLINK" 3 "SNA" ;
VAL_ 976 PF_WARN_MSG 0 "PF_WARN" 1 "PF_WARN_REG_REQ" 2 "PF_WARN_REG_STRT" 3 "PF_WARN_REG_CMPT" 4 "PF_WARN_REG_SERV" 5 "PF_WARN_REG_PW_RED" 6 "PF_WARN_6" 7 "PF_WARN_7" ;
VAL_ 976 KNK_MG_TRIGGER 0 "LSPI_NO_MESSAGE" 1 "LSPI_LEVEL_1" 2 "LSPI_LEVEL_2" 3 "LSPI_LEVEL_3" ;
VAL_ 979 EC_ECUCfg14_Stat 0 "NA" 1 "PROGAMMED" 2 "REQUEST_DATA" 3 "SNA" ;
VAL_ 980 EC_ECUCfg13_Stat 0 "NA" 1 "PROGAMMED" 2 "REQUEST_DATA" 3 "SNA" ;
VAL_ 981 EC_ECUCfg12_Stat 0 "NA" 1 "PROGAMMED" 2 "REQUEST_DATA" 3 "SNA" ;
VAL_ 982 EC_ECUCfg11_Stat 0 "NA" 1 "PROGAMMED" 2 "REQUEST_DATA" 3 "SNA" ;
VAL_ 983 EC_ECUCfg10_Stat 0 "NA" 1 "PROGAMMED" 2 "REQUEST_DATA" 3 "SNA" ;
VAL_ 984 EC_ECUCfg9_Stat 0 "NA" 1 "PROGAMMED" 2 "REQUEST_DATA" 3 "SNA" ;
VAL_ 985 EC_BU_ECUCfg14_Stat 0 "NA" 1 "PROGAMMED" 2 "NA1" 3 "SNA" ;
VAL_ 986 EC_BU_ECUCfg13_Stat 0 "NA" 1 "PROGAMMED" 2 "NA1" 3 "SNA" ;
VAL_ 987 EC_BU_ECUCfg12_Stat 0 "NA" 1 "PROGAMMED" 2 "NA1" 3 "SNA" ;
VAL_ 988 EC_BU_ECUCfg11_Stat 0 "NA" 1 "PROGAMMED" 2 "REQUEST_DATA" 3 "SNA" ;
VAL_ 989 EC_BU_ECUCfg10_Stat 0 "NA" 1 "PROGAMMED" 2 "NA1" 3 "SNA" ;
VAL_ 991 EC_BU_ECUCfg9_Stat 0 "NA" 1 "PROGAMMED" 2 "NA1" 3 "SNA" ;
VAL_ 992 VIN_MSG 0 "VIN_LO" 1 "VIN_MID" 2 "VIN_HI" 3 "SNA" ;
VAL_ 993 Manufacture 0 "ENG_DCA" 1 "ENG_DCS" 2 "ENG_MMC" 3 "ENG_HY" 7 "ENG_NP" ;
VAL_ 993 NUM_VALVE 7 "SNA" ;
VAL_ 993 EngStyle 0 "CHOICE1" 1 "CHOICE2" 2 "CHOICE3" 3 "CHOICE4" 4 "CHOICE5" 5 "CHOICE6" 7 "SNA" ;
VAL_ 993 DISPLACEMENT 255 "SNA" ;
VAL_ 993 NUM_CYL 15 "SNA" ;
VAL_ 993 ENG_ASP 0 "INTAKE_NORM" 1 "TURBO1" 2 "TURBO2" 3 "SUPER" 7 "SNA" ;
VAL_ 993 FUEL_TYPE 0 "UNLEADED" 1 "DIESEL" 2 "FLEX" 3 "CNG" 7 "SNA" ;
VAL_ 993 ECM_Vehi_Type 0 "STANDARD" 1 "EVEHICLE" 3 "SNA" ;
VAL_ 995 NetCfg_TTM 0 "Not_Present" 1 "Present" ;
VAL_ 995 NET_CFG_STAT_INT 0 "NA" 1 "PROGAMMED" 2 "REQUEST_DATA" 3 "SNA" ;
VAL_ 995 NetCfg_ANC_I 0 "Not_Present" 1 "Present" ;
